VERSION ""

NS_ :

BS_:

BU_: AHLM ASBS CBC DIAGNOST DPDM DTCM ECM EHPS ESC ESL ESM ETM GPF HCP IC IRCM OCM ORC PTS RF_HUB SCCM SGW TBM TCM TPM

BO_ 969 AMB_TEMP_DISP: 4 CBC
 SG_ AMB_TEMP_AVG_C : 8|8@1+ (1,-40) [-40|210] "°C"  IC,SGW
 SG_ AMB_TEMP_AVG_F : 0|8@1+ (1,-40) [-40|210] "°F"  IC,SGW

BO_ 1769 APPL_ECU_AHLM: 8 DIAGNOST
 SG_ APPL_ECU_AHLM : 7|64@0+ (1,0) [0|0] ""  AHLM

BO_ 1738 APPL_ECU_ASBS: 8 DIAGNOST
 SG_ APPL_ECU_ASBS : 7|64@0+ (1,0) [0|0] ""  ASBS

BO_ 1788 APPL_ECU_BSMO: 8 DIAGNOST
 SG_ APPL_ECU_BSMO : 7|64@0+ (1,0) [0|0] ""  ESC

BO_ 1729 APPL_ECU_CBC: 8 DIAGNOST
 SG_ APPL_ECU_CBC : 7|64@0+ (1,0) [0|0] ""  CBC

BO_ 1747 APPL_ECU_DASM: 8 DIAGNOST
 SG_ APPL_ECU_DASM : 7|64@0+ (1,0) [0|0] ""  IRCM

BO_ 1745 APPL_ECU_DPDM: 8 DIAGNOST
 SG_ APPL_ECU_DPDM : 7|64@0+ (1,0) [0|0] ""  DPDM

BO_ 1739 APPL_ECU_DTCM: 8 DIAGNOST
 SG_ APPL_ECU_DTCM : 7|64@0+ (1,0) [0|0] ""  DTCM

BO_ 1784 APPL_ECU_ECM: 8 DIAGNOST
 SG_ APPL_ECU_ECM : 7|64@0+ (1,0) [0|0] ""  ECM

BO_ 1754 APPL_ECU_EPS: 8 DIAGNOST
 SG_ APPL_ECU_EPS : 7|64@0+ (1,0) [0|0] ""  EHPS

BO_ 1735 APPL_ECU_ESC: 8 DIAGNOST
 SG_ APPL_ECU_ESC : 7|64@0+ (1,0) [0|0] ""  ESC

BO_ 1736 APPL_ECU_ESL: 8 DIAGNOST
 SG_ APPL_ECU_ESL : 7|64@0+ (1,0) [0|0] ""  ESL

BO_ 1737 APPL_ECU_ESM: 8 DIAGNOST
 SG_ APPL_ECU_ESM : 7|64@0+ (1,0) [0|0] ""  ESM

BO_ 1778 APPL_ECU_GPF: 8 DIAGNOST
 SG_ APPL_ECU_GPF : 7|64@0+ (1,0) [0|0] ""  GPF

BO_ 1786 APPL_ECU_HCP: 8 DIAGNOST
 SG_ APPL_ECU_HCP : 7|64@0+ (1,0) [0|0] ""  HCP

BO_ 1730 APPL_ECU_IC: 8 DIAGNOST
 SG_ APPL_ECU_IC : 7|64@0+ (1,0) [0|0] ""  IC

BO_ 1758 APPL_ECU_OCM: 8 DIAGNOST
 SG_ APPL_ECU_OCM : 7|64@0+ (1,0) [0|0] ""  OCM

BO_ 1732 APPL_ECU_ORC: 8 DIAGNOST
 SG_ APPL_ECU_ORC : 7|64@0+ (1,0) [0|0] ""  ORC

BO_ 1762 APPL_ECU_PTS: 8 DIAGNOST
 SG_ APPL_ECU_PTS : 7|64@0+ (1,0) [0|0] ""  PTS

BO_ 1728 APPL_ECU_RF_HUB: 8 DIAGNOST
 SG_ APPL_ECU_RF_HUB : 7|64@0+ (1,0) [0|0] ""  RF_HUB

BO_ 1763 APPL_ECU_SCCM: 8 DIAGNOST
 SG_ APPL_ECU_SCCM : 7|64@0+ (1,0) [0|0] ""  SCCM

BO_ 1835 APPL_ECU_TBM: 8 DIAGNOST
 SG_ APPL_ECU_TBM : 7|64@0+ (1,0) [0|0] ""  TBM

BO_ 1785 APPL_ECU_TCM: 8 DIAGNOST
 SG_ APPL_ECU_TCM : 7|64@0+ (1,0) [0|0] ""  TCM

BO_ 1731 APPL_ECU_TPM: 8 DIAGNOST
 SG_ APPL_ECU_TPM : 7|64@0+ (1,0) [0|0] ""  TPM

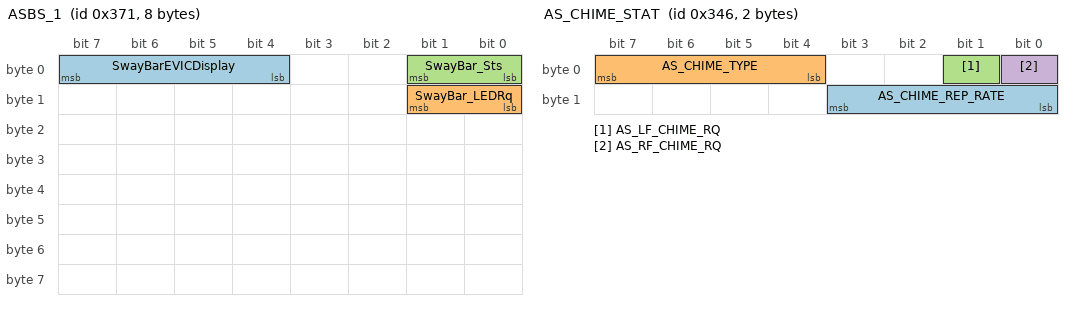
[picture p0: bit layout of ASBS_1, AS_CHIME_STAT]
BO_ 881 ASBS_1: 8 ASBS
 SG_ SwayBarEVICDisplay : 4|4@1+ (1,0) [0|0] ""  ETM,IC,SGW
 SG_ SwayBar_LEDRq : 8|2@1+ (1,0) [0|0] ""  CBC,SGW
 SG_ SwayBar_Sts : 0|2@1+ (1,0) [0|0] ""  ETM,IC,SGW

BO_ 838 AS_CHIME_STAT: 2 IRCM
 SG_ AS_CHIME_REP_RATE : 8|4@1+ (1,0) [0|15] "Hz"  CBC,SGW
 SG_ AS_CHIME_TYPE : 4|4@1+ (1,0) [0|0] ""  CBC,ORC,SGW
 SG_ AS_LF_CHIME_RQ : 1|1@1+ (1,0) [0|0] ""  CBC,SGW
 SG_ AS_RF_CHIME_RQ : 0|1@1+ (1,0) [0|0] ""  CBC,SGW

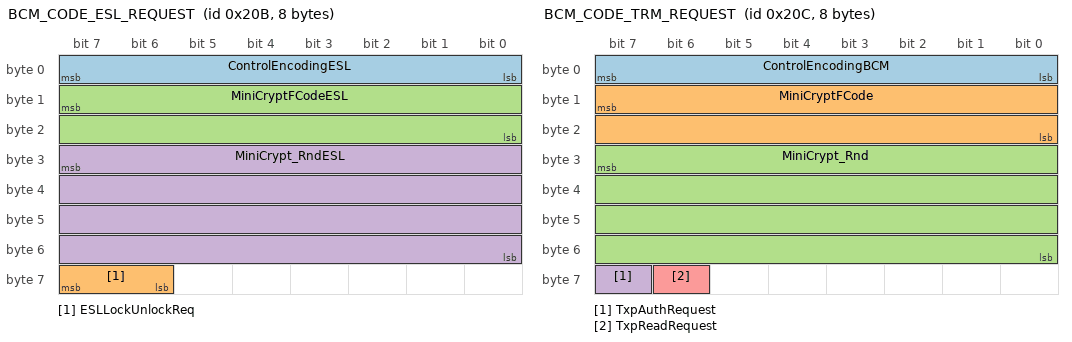
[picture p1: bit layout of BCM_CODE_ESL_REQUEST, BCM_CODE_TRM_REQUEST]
BO_ 523 BCM_CODE_ESL_REQUEST: 8 CBC
 SG_ ControlEncodingESL : 0|8@1+ (1,0) [0|0] ""  ESL,SGW
 SG_ ESLLockUnlockReq : 62|2@1+ (1,0) [0|0] ""  ESL,SGW
 SG_ MiniCryptFCodeESL : 15|16@0+ (1,0) [0|0] ""  ESL,SGW
 SG_ MiniCrypt_RndESL : 31|32@0+ (1,0) [0|0] ""  ESL,SGW

BO_ 524 BCM_CODE_TRM_REQUEST: 8 CBC
 SG_ ControlEncodingBCM : 0|8@1+ (1,0) [0|0] ""  RF_HUB,SGW
 SG_ MiniCryptFCode : 15|16@0+ (1,0) [0|0] ""  RF_HUB,SGW
 SG_ MiniCrypt_Rnd : 31|32@0+ (1,0) [0|0] ""  RF_HUB,SGW
 SG_ TxpAuthRequest : 63|1@1+ (1,0) [0|0] ""  RF_HUB,SGW
 SG_ TxpReadRequest : 62|1@1+ (1,0) [0|0] ""  RF_HUB,SGW

BO_ 525 BCM_MINICRYPT_ACK: 1 CBC
 SG_ MinicryptReceptionSts : 7|1@1+ (1,0) [0|0] ""  RF_HUB,SGW

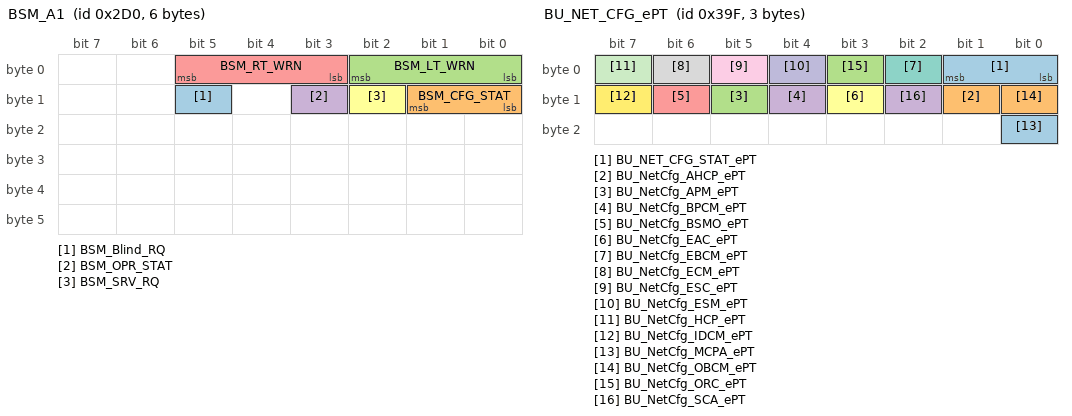
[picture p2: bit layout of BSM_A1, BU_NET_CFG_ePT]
BO_ 720 BSM_A1: 6 CBC
 SG_ BSM_Blind_RQ : 13|1@1+ (1,0) [0|0] ""  IC,IRCM,ORC,SGW
 SG_ BSM_CFG_STAT : 8|2@1+ (1,0) [0|0] ""  IC,IRCM,ORC,SGW
 SG_ BSM_LT_WRN : 0|3@1+ (1,0) [0|0] ""  IRCM,ORC,SGW
 SG_ BSM_OPR_STAT : 11|1@1+ (1,0) [0|0] ""  IC,IRCM,SGW
 SG_ BSM_RT_WRN : 3|3@1+ (1,0) [0|0] ""  IRCM,ORC,SGW
 SG_ BSM_SRV_RQ : 10|1@1+ (1,0) [0|0] ""  IC,IRCM,ORC,SGW

BO_ 998 BU_NET_CFG_INT: 8 RF_HUB
 SG_ BU_NET_CFG_STAT_INT : 0|2@1+ (1,0) [0|0] ""  CBC,SGW
 SG_ BU_NetCfg_AMP_I : 24|1@1+ (1,0) [0|0] ""  CBC,SGW
 SG_ BU_NetCfg_ANC_I : 39|1@1+ (1,0) [0|0] ""  CBC,SGW
 SG_ BU_NetCfg_BSM : 3|1@1+ (1,0) [0|0] ""  CBC,SGW
 SG_ BU_NetCfg_CBC_IN : 4|1@1+ (1,0) [0|0] ""  CBC,SGW
 SG_ BU_NetCfg_CLOCK : 21|1@1+ (1,0) [0|0] ""  CBC,SGW
 SG_ BU_NetCfg_CRSM : 30|1@1+ (1,0) [0|0] ""  CBC,SGW
 SG_ BU_NetCfg_CSWM : 5|1@1+ (1,0) [0|0] ""  CBC,SGW
 SG_ BU_NetCfg_CVPM : 32|1@1+ (1,0) [0|0] ""  CBC,SGW
 SG_ BU_NetCfg_DCM_DR : 6|1@1+ (1,0) [0|0] ""  CBC,SGW
 SG_ BU_NetCfg_DCM_PASS : 7|1@1+ (1,0) [0|0] ""  CBC,SGW
 SG_ BU_NetCfg_DCM_RL : 8|1@1+ (1,0) [0|0] ""  CBC,SGW
 SG_ BU_NetCfg_DCM_RR : 9|1@1+ (1,0) [0|0] ""  CBC,SGW
 SG_ BU_NetCfg_DCSD : 37|1@1+ (1,0) [0|0] ""  CBC,SGW
 SG_ BU_NetCfg_DTV : 19|1@1+ (1,0) [0|0] ""  CBC,SGW
 SG_ BU_NetCfg_DVD_CDM : 25|1@1+ (1,0) [0|0] ""  CBC,SGW
 SG_ BU_NetCfg_FSM : 16|1@1+ (1,0) [0|0] ""  CBC,SGW
 SG_ BU_NetCfg_HFM_CTM : 26|1@1+ (1,0) [0|0] ""  CBC,SGW
 SG_ BU_NetCfg_HVAC : 10|1@1+ (1,0) [0|0] ""  CBC,SGW
 SG_ BU_NetCfg_HVAC_R : 31|1@1+ (1,0) [0|0] ""  CBC,SGW
 SG_ BU_NetCfg_ICS_I : 27|1@1+ (1,0) [0|0] ""  CBC,SGW
 SG_ BU_NetCfg_ICS_R : 34|1@1+ (1,0) [0|0] ""  CBC,SGW
 SG_ BU_NetCfg_ITM : 23|1@1+ (1,0) [0|0] ""  CBC,SGW
 SG_ BU_NetCfg_MSM : 11|1@1+ (1,0) [0|0] ""  CBC,SGW
 SG_ BU_NetCfg_MSM_PASS : 35|1@1+ (1,0) [0|0] ""  CBC,SGW
 SG_ BU_NetCfg_PLG : 12|1@1+ (1,0) [0|0] ""  CBC,SGW
 SG_ BU_NetCfg_PSD_LT : 14|1@1+ (1,0) [0|0] ""  CBC,SGW
 SG_ BU_NetCfg_PSD_RT : 15|1@1+ (1,0) [0|0] ""  CBC,SGW
 SG_ BU_NetCfg_PSSM : 45|1@1+ (1,0) [0|0] ""  CBC,SGW
 SG_ BU_NetCfg_PTCM : 17|1@1+ (1,0) [0|0] ""  CBC,SGW
 SG_ BU_NetCfg_RBC : 18|1@1+ (1,0) [0|0] ""  CBC,SGW
 SG_ BU_NetCfg_RBSS : 2|1@1+ (1,0) [0|0] ""  CBC,SGW
 SG_ BU_NetCfg_TBM : 38|1@1+ (1,0) [0|0] ""  CBC,SGW
 SG_ BU_NetCfg_TGW : 20|1@1+ (1,0) [0|0] ""  CBC,SGW
 SG_ BU_NetCfg_TMM : 33|1@1+ (1,0) [0|0] ""  CBC,SGW
 SG_ BU_NetCfg_TTM : 47|1@1+ (1,0) [0|0] ""  CBC,SGW
 SG_ BU_NetCfg_UPFM : 46|1@1+ (1,0) [0|0] ""  CBC,SGW
 SG_ BU_NetCfg_VES2_I : 28|1@1+ (1,0) [0|0] ""  CBC,SGW
 SG_ BU_NetCfg_VES3_I : 29|1@1+ (1,0) [0|0] ""  CBC,SGW
 SG_ BU_NetCfg_VRM : 36|1@1+ (1,0) [0|0] ""  CBC,SGW
 SG_ BU_NetCfg_VSIM : 22|1@1+ (1,0) [0|0] ""  CBC,SGW
 SG_ BU_NetCfg_VTM : 13|1@1+ (1,0) [0|0] ""  CBC,SGW

BO_ 999 BU_NET_CFG_PT: 8 RF_HUB
 SG_ BU_NET_CFG_STAT_PT : 0|2@1+ (1,0) [0|0] ""  CBC,SGW
 SG_ BU_NetCfg_ACC : 2|1@1+ (1,0) [0|0] ""  CBC,SGW
 SG_ BU_NetCfg_ADCM : 3|1@1+ (1,0) [0|0] ""  CBC,SGW
 SG_ BU_NetCfg_AFLS : 28|1@1+ (1,0) [0|0] ""  CBC,SGW
 SG_ BU_NetCfg_AHLM : 4|1@1+ (1,0) [0|0] ""  CBC,SGW
 SG_ BU_NetCfg_ANC : 39|1@1+ (1,0) [0|0] ""  CBC,SGW
 SG_ BU_NetCfg_ASBS : 35|1@1+ (1,0) [0|0] ""  CBC,SGW
 SG_ BU_NetCfg_ASCM : 6|1@1+ (1,0) [0|0] ""  CBC,SGW
 SG_ BU_NetCfg_BSMO : 36|1@1+ (1,0) [0|0] ""  CBC,SGW
 SG_ BU_NetCfg_CBC_PT : 7|1@1+ (1,0) [0|0] ""  CBC,SGW
 SG_ BU_NetCfg_DASM : 16|1@1+ (1,0) [0|0] ""  CBC,SGW
 SG_ BU_NetCfg_DPDM : 33|1@1+ (1,0) [0|0] ""  CBC,SGW
 SG_ BU_NetCfg_DTCM : 8|1@1+ (1,0) [0|0] ""  CBC,SGW
 SG_ BU_NetCfg_ECM : 9|1@1+ (1,0) [0|0] ""  CBC,SGW
 SG_ BU_NetCfg_ELSD : 24|1@1+ (1,0) [0|0] ""  CBC,SGW
 SG_ BU_NetCfg_EPB : 13|1@1+ (1,0) [0|0] ""  CBC,SGW
 SG_ BU_NetCfg_EPPM : 18|1@1+ (1,0) [0|0] ""  CBC,SGW
 SG_ BU_NetCfg_EPS : 10|1@1+ (1,0) [0|0] ""  CBC,SGW
 SG_ BU_NetCfg_ESC : 12|1@1+ (1,0) [0|0] ""  CBC,SGW
 SG_ BU_NetCfg_ESL : 37|1@1+ (1,0) [0|0] ""  CBC,SGW
 SG_ BU_NetCfg_ESM : 11|1@1+ (1,0) [0|0] ""  CBC,SGW
 SG_ BU_NetCfg_FDCM : 17|1@1+ (1,0) [0|0] ""  CBC,SGW
 SG_ BU_NetCfg_GPF : 58|1@1+ (1,0) [0|0] ""  CBC,SGW
 SG_ BU_NetCfg_HCP : 38|1@1+ (1,0) [0|0] ""  CBC,SGW
 SG_ BU_NetCfg_HaLF : 31|1@1+ (1,0) [0|0] ""  CBC,SGW
 SG_ BU_NetCfg_IC : 15|1@1+ (1,0) [0|0] ""  CBC,SGW
 SG_ BU_NetCfg_ITBM : 29|1@1+ (1,0) [0|0] ""  CBC,SGW
 SG_ BU_NetCfg_OCM : 30|1@1+ (1,0) [0|0] ""  CBC,SGW
 SG_ BU_NetCfg_ORC : 19|1@1+ (1,0) [0|0] ""  CBC,SGW
 SG_ BU_NetCfg_PASS_PT : 27|1@1+ (1,0) [0|0] ""  CBC,SGW
 SG_ BU_NetCfg_PTS : 20|1@1+ (1,0) [0|0] ""  CBC,SGW
 SG_ BU_NetCfg_RF_HUB : 14|1@1+ (1,0) [0|0] ""  CBC,SGW
 SG_ BU_NetCfg_SCCM : 23|1@1+ (1,0) [0|0] ""  CBC,SGW
 SG_ BU_NetCfg_SGW : 34|1@1+ (1,0) [0|0] ""  CBC,SGW
 SG_ BU_NetCfg_TCM : 25|1@1+ (1,0) [0|0] ""  CBC,SGW
 SG_ BU_NetCfg_TIM : 60|1@1+ (1,0) [0|0] ""  CBC,SGW
 SG_ BU_NetCfg_TPM : 26|1@1+ (1,0) [0|0] ""  CBC,SGW
 SG_ BU_NetCfg_TTPM : 59|1@1+ (1,0) [0|0] ""  CBC,SGW
 SG_ BU_NetCfg_VSIM_C : 5|1@1+ (1,0) [0|0] ""  CBC,SGW

BO_ 927 BU_NET_CFG_ePT: 3 RF_HUB
 SG_ BU_NET_CFG_STAT_ePT : 0|2@1+ (1,0) [0|0] ""  CBC,SGW
 SG_ BU_NetCfg_AHCP_ePT : 9|1@1+ (1,0) [0|0] ""  CBC,SGW
 SG_ BU_NetCfg_APM_ePT : 13|1@1+ (1,0) [0|0] ""  CBC,SGW
 SG_ BU_NetCfg_BPCM_ePT : 12|1@1+ (1,0) [0|0] ""  CBC,SGW
 SG_ BU_NetCfg_BSMO_ePT : 14|1@1+ (1,0) [0|0] ""  CBC,SGW
 SG_ BU_NetCfg_EAC_ePT : 11|1@1+ (1,0) [0|0] ""  CBC,SGW
 SG_ BU_NetCfg_EBCM_ePT : 2|1@1+ (1,0) [0|0] ""  CBC,SGW
 SG_ BU_NetCfg_ECM_ePT : 6|1@1+ (1,0) [0|0] ""  CBC,SGW
 SG_ BU_NetCfg_ESC_ePT : 5|1@1+ (1,0) [0|0] ""  CBC,SGW
 SG_ BU_NetCfg_ESM_ePT : 4|1@1+ (1,0) [0|0] ""  CBC,SGW
 SG_ BU_NetCfg_HCP_ePT : 7|1@1+ (1,0) [0|0] ""  CBC,SGW
 SG_ BU_NetCfg_IDCM_ePT : 15|1@1+ (1,0) [0|0] ""  CBC,SGW
 SG_ BU_NetCfg_MCPA_ePT : 16|1@1+ (1,0) [0|0] ""  CBC,SGW
 SG_ BU_NetCfg_OBCM_ePT : 8|1@1+ (1,0) [0|0] ""  CBC,SGW
 SG_ BU_NetCfg_ORC_ePT : 3|1@1+ (1,0) [0|0] ""  CBC,SGW
 SG_ BU_NetCfg_SCA_ePT : 10|1@1+ (1,0) [0|0] ""  CBC,SGW

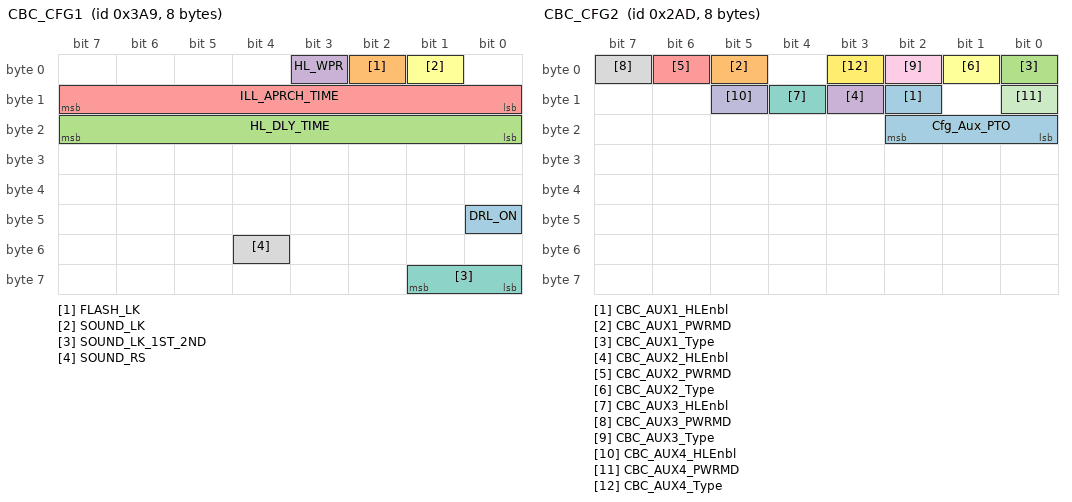
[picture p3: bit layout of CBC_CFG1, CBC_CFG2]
BO_ 937 CBC_CFG1: 8 CBC
 SG_ DRL_ON : 40|1@1+ (1,0) [0|0] ""  SGW
 SG_ FLASH_LK : 2|1@1+ (1,0) [0|0] ""  SGW
 SG_ HL_DLY_TIME : 16|8@1+ (1,0) [0|254] "sec"  SGW
 SG_ HL_WPR : 3|1@1+ (1,0) [0|0] ""  SGW
 SG_ ILL_APRCH_TIME : 8|8@1+ (1,0) [0|254] "sec"  SGW
 SG_ SOUND_LK : 1|1@1+ (1,0) [0|0] ""  SGW
 SG_ SOUND_LK_1ST_2ND : 56|2@1+ (1,0) [0|0] ""  SGW
 SG_ SOUND_RS : 52|1@1+ (1,0) [0|0] ""  SGW

BO_ 685 CBC_CFG2: 8 CBC
 SG_ CBC_AUX1_HLEnbl : 10|1@1+ (1,0) [0|0] ""  SGW
 SG_ CBC_AUX1_PWRMD : 5|1@1+ (1,0) [0|0] ""  SGW
 SG_ CBC_AUX1_Type : 0|1@1+ (1,0) [0|0] ""  SGW
 SG_ CBC_AUX2_HLEnbl : 11|1@1+ (1,0) [0|0] ""  SGW
 SG_ CBC_AUX2_PWRMD : 6|1@1+ (1,0) [0|0] ""  SGW
 SG_ CBC_AUX2_Type : 1|1@1+ (1,0) [0|0] ""  SGW
 SG_ CBC_AUX3_HLEnbl : 12|1@1+ (1,0) [0|0] ""  SGW
 SG_ CBC_AUX3_PWRMD : 7|1@1+ (1,0) [0|0] ""  SGW
 SG_ CBC_AUX3_Type : 2|1@1+ (1,0) [0|0] ""  SGW
 SG_ CBC_AUX4_HLEnbl : 13|1@1+ (1,0) [0|0] ""  SGW
 SG_ CBC_AUX4_PWRMD : 8|1@1+ (1,0) [0|0] ""  SGW
 SG_ CBC_AUX4_Type : 3|1@1+ (1,0) [0|0] ""  SGW
 SG_ Cfg_Aux_PTO : 16|3@1+ (1,0) [0|0] ""  SGW

BO_ 657 CBC_PT1: 8 CBC
 SG_ AHB_ACT : 14|1@1+ (1,0) [0|0] ""  IC,SGW
 SG_ BRK_FLUID_LO : 62|1@1+ (1,0) [0|0] ""  ESC,ETM,IC,SGW,TBM
 SG_ DAY_LGT_MD : 40|1@1+ (1,0) [0|0] ""  ESM,HCP,IC,ORC,RF_HUB,SGW
 SG_ DRV_AJAR : 17|1@1+ (1,0) [0|0] ""  ESC,ETM,HCP,IC,IRCM,RF_HUB,SGW,TBM,TCM
 SG_ DR_LK_STAT : 5|2@1+ (1,0) [0|0] ""  SGW
 SG_ FOB_SrchRq : 8|2@1+ (1,0) [0|0] ""  RF_HUB,SGW
 SG_ FT_FOG_RQ : 2|1@1+ (1,0) [0|0] ""  ECM,ETM,IC,SGW,TBM
 SG_ FT_WPR_NOT_PRK : 56|1@1+ (1,0) [0|0] ""  DTCM,ECM,IRCM,SGW
 SG_ HIBEAM_ON : 58|1@1+ (1,0) [0|0] ""  ECM,ETM,IC,IRCM,SGW,TBM
 SG_ IGN_OFF_TIME_LNG : 27|12@0+ (1,0) [0|4080] "min"  DTCM,ECM,ESC,IRCM,SGW,TCM
 SG_ LOBEAM_ON : 57|1@1+ (1,0) [0|0] ""  AHLM,ECM,ETM,SGW,TBM
 SG_ L_R_AJAR : 19|1@1+ (1,0) [0|0] ""  ETM,IC,RF_HUB,SGW,TBM
 SG_ PANEL_INTS : 48|8@1+ (0.5,0) [0|100] "%"  ESM,HCP,IC,RF_HUB,SGW
 SG_ PARK_BRK_EGD : 23|1@1+ (1,0) [0|0] ""  ECM,ESC,IC,IRCM,ORC,SGW,TCM,TPM
 SG_ PARK_LMP_ON : 16|1@1+ (1,0) [0|0] ""  ETM,IC,SGW,TBM
 SG_ PSG_AJAR : 18|1@1+ (1,0) [0|0] ""  ESC,ETM,IC,RF_HUB,SGW,TBM
 SG_ PTC_REL1_STAT : 42|2@1+ (1,0) [0|0] ""  ECM,SGW
 SG_ PTC_REL2_STAT : 44|2@1+ (1,0) [0|0] ""  ECM,SGW
 SG_ PTC_REL3_STAT : 46|2@1+ (1,0) [0|0] ""  ECM,SGW
 SG_ REV_GEAR : 4|1@1+ (1,0) [0|0] ""  DTCM,ESC,IC,ORC,PTS,SGW,TPM
 SG_ R_FOG_RQ : 3|1@1+ (1,0) [0|0] ""  ECM,ETM,IC,SGW,TBM
 SG_ R_R_AJAR : 20|1@1+ (1,0) [0|0] ""  ETM,IC,RF_HUB,SGW,TBM
 SG_ SHIP_STAT : 28|2@1+ (1,0) [0|0] ""  DTCM,HCP,IC,IRCM,RF_HUB,SGW
 SG_ TLG_AJAR : 22|1@1+ (1,0) [0|0] ""  ETM,IC,RF_HUB,SGW,TBM
 SG_ TurnInd_LT_ON : 30|1@1+ (1,0) [0|0] ""  ETM,IC,SGW,TBM
 SG_ TurnInd_RT_ON : 31|1@1+ (1,0) [0|0] ""  ETM,IC,SGW,TBM
 SG_ WASH_FLUID_LO : 63|1@1+ (1,0) [0|0] ""  ETM,IC,SGW,TBM

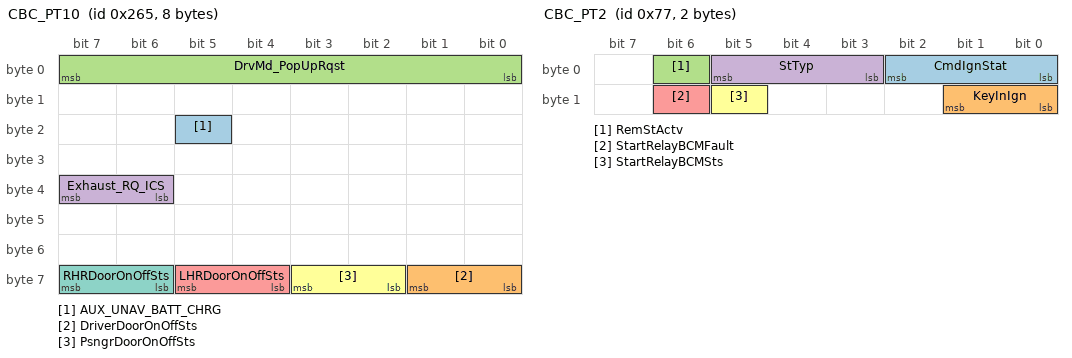
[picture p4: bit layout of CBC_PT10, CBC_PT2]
BO_ 613 CBC_PT10: 8 CBC
 SG_ AUX_UNAV_BATT_CHRG : 21|1@1+ (1,0) [0|0] ""  IC,SGW
 SG_ DriverDoorOnOffSts : 56|2@1+ (1,0) [0|0] ""  ESC,IC,IRCM,RF_HUB,SGW
 SG_ DrvMd_PopUpRqst : 0|8@1+ (1,0) [0|0] ""  IC,SGW
 SG_ Exhaust_RQ_ICS : 38|2@1+ (1,0) [0|0] ""  ECM,SGW
 SG_ LHRDoorOnOffSts : 60|2@1+ (1,0) [0|0] ""  RF_HUB,SGW
 SG_ PsngrDoorOnOffSts : 58|2@1+ (1,0) [0|0] ""  RF_HUB,SGW
 SG_ RHRDoorOnOffSts : 62|2@1+ (1,0) [0|0] ""  RF_HUB,SGW

BO_ 119 CBC_PT2: 2 CBC
 SG_ CmdIgnStat : 0|3@1+ (1,0) [0|0] ""  AHLM,ASBS,DPDM,DTCM,ECM,EHPS,ESC,ESL,ESM,GPF,HCP,IC,IRCM,OCM,ORC,PTS,RF_HUB,SCCM,SGW,TCM,TPM
 SG_ KeyInIgn : 8|2@1+ (1,0) [0|0] ""  ESC,ESL,HCP,IC,RF_HUB,SGW
 SG_ RemStActv : 6|1@1+ (1,0) [0|0] ""  DTCM,ECM,ESM,HCP,IC,ORC,RF_HUB,SGW,TCM,TPM
 SG_ StTyp : 3|3@1+ (1,0) [0|0] ""  DTCM,RF_HUB,SGW
 SG_ StartRelayBCMFault : 14|1@1+ (1,0) [0|0] ""  ECM,SGW
 SG_ StartRelayBCMSts : 13|1@1+ (1,0) [0|0] ""  ECM,SGW

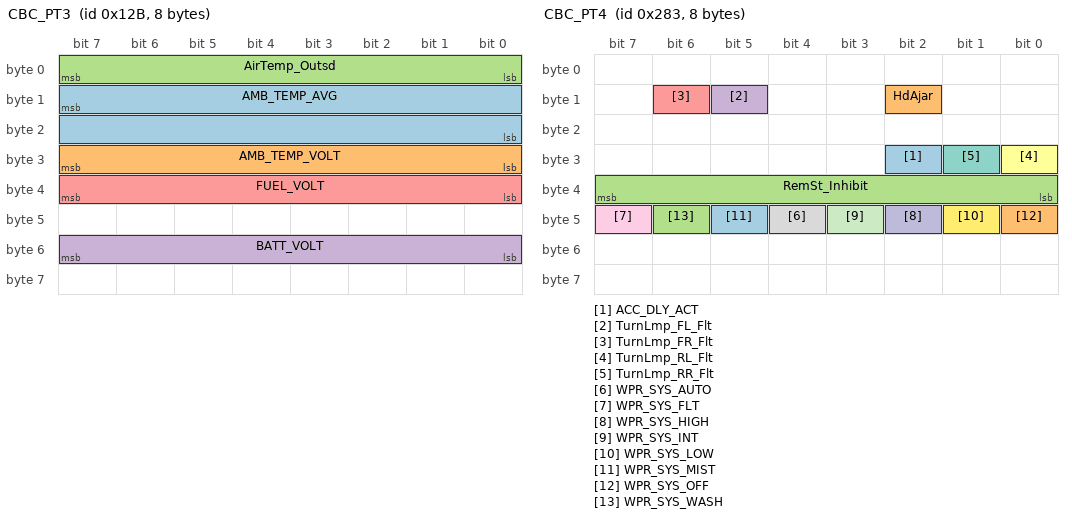
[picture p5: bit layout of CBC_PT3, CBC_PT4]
BO_ 299 CBC_PT3: 8 CBC
 SG_ AMB_TEMP_AVG : 15|16@0+ (0.01,-40) [-40|85] "°C"  DPDM,DTCM,ECM,ESC,HCP,OCM,PTS,SGW,TCM,TPM
 SG_ AMB_TEMP_VOLT : 24|8@1+ (0.019607843,0) [0|4.98] "Volts"  ECM,HCP,SGW
 SG_ AirTemp_Outsd : 0|8@1+ (0.5,-40) [-40|85] "°C"  DTCM,ECM,IRCM,ORC,SGW
 SG_ BATT_VOLT : 48|8@1+ (0.1,0) [5|18] "Volts"  AHLM,ASBS,DPDM,DTCM,ECM,EHPS,ESC,ESL,ESM,GPF,HCP,IC,IRCM,OCM,ORC,PTS,RF_HUB,SCCM,SGW,TCM,TPM
 SG_ FUEL_VOLT : 32|8@1+ (0.019607843,0) [0|4.98] "Volts"  ECM,IC,SGW

BO_ 643 CBC_PT4: 8 CBC
 SG_ ACC_DLY_ACT : 26|1@1+ (1,0) [0|0] ""  IC,SGW
 SG_ HdAjar : 10|1@1+ (1,0) [0|0] ""  ETM,HCP,IC,SGW,TBM
 SG_ RemSt_Inhibit : 32|8@1+ (1,0) [0|0] ""  ETM,IC,SGW,TBM
 SG_ TurnLmp_FL_Flt : 13|1@1+ (1,0) [0|0] ""  ETM,IC,SGW,TBM
 SG_ TurnLmp_FR_Flt : 14|1@1+ (1,0) [0|0] ""  ETM,IC,SGW,TBM
 SG_ TurnLmp_RL_Flt : 24|1@1+ (1,0) [0|0] ""  ETM,IC,SGW,TBM
 SG_ TurnLmp_RR_Flt : 25|1@1+ (1,0) [0|0] ""  ETM,IC,SGW,TBM
 SG_ WPR_SYS_AUTO : 44|1@1+ (1,0) [0|0] ""  ESC,IRCM,SGW
 SG_ WPR_SYS_FLT : 47|1@1+ (1,0) [0|0] ""  ESC,IRCM,SGW
 SG_ WPR_SYS_HIGH : 42|1@1+ (1,0) [0|0] ""  ESC,IRCM,SGW
 SG_ WPR_SYS_INT : 43|1@1+ (1,0) [0|0] ""  ESC,IRCM,SGW
 SG_ WPR_SYS_LOW : 41|1@1+ (1,0) [0|0] ""  ESC,IRCM,SGW
 SG_ WPR_SYS_MIST : 45|1@1+ (1,0) [0|0] ""  DTCM,ESC,IRCM,SGW
 SG_ WPR_SYS_OFF : 40|1@1+ (1,0) [0|0] ""  ESC,IRCM,SGW
 SG_ WPR_SYS_WASH : 46|1@1+ (1,0) [0|0] ""  ESC,IRCM,SGW

BO_TX_BU_ 1769 : DIAGNOST,SGW;
BO_TX_BU_ 1738 : DIAGNOST,SGW;
BO_TX_BU_ 1788 : DIAGNOST,SGW;
BO_TX_BU_ 1729 : DIAGNOST,SGW;
BO_TX_BU_ 1747 : DIAGNOST,SGW;
BO_TX_BU_ 1745 : DIAGNOST,SGW;
BO_TX_BU_ 1739 : DIAGNOST,SGW;
BO_TX_BU_ 1784 : DIAGNOST,SGW;
BO_TX_BU_ 1754 : DIAGNOST,SGW;
BO_TX_BU_ 1735 : DIAGNOST,SGW;
BO_TX_BU_ 1736 : DIAGNOST,SGW;
BO_TX_BU_ 1737 : DIAGNOST,SGW;
BO_TX_BU_ 1778 : DIAGNOST,SGW;
BO_TX_BU_ 1786 : DIAGNOST,SGW;
BO_TX_BU_ 1730 : DIAGNOST,SGW;
BO_TX_BU_ 1758 : DIAGNOST,SGW;
BO_TX_BU_ 1732 : DIAGNOST,SGW;
BO_TX_BU_ 1762 : DIAGNOST,SGW;
BO_TX_BU_ 1728 : DIAGNOST,SGW;
BO_TX_BU_ 1763 : DIAGNOST,SGW;
BO_TX_BU_ 1835 : DIAGNOST,SGW;
BO_TX_BU_ 1785 : DIAGNOST,SGW;
BO_TX_BU_ 1731 : DIAGNOST,SGW;

CM_ "Excel Convert to DBC - Written by Vector CANtech, Inc. 2016";
CM_ SG_ 969 AMB_TEMP_AVG_C "Ambient temperature average - in degrees Celsius";
CM_ SG_ 969 AMB_TEMP_AVG_F "Ambient temperature average - in degrees Fahrenheit";
CM_ SG_ 1769 APPL_ECU_AHLM "External Application to ECU";
CM_ SG_ 1738 APPL_ECU_ASBS "External Application to ECU";
CM_ SG_ 1788 APPL_ECU_BSMO "External Application to ECU";
CM_ SG_ 1729 APPL_ECU_CBC "External Application to ECU";
CM_ SG_ 1747 APPL_ECU_DASM "External Application to ECU";
CM_ SG_ 1745 APPL_ECU_DPDM "External Application to ECU";
CM_ SG_ 1739 APPL_ECU_DTCM "External Application to ECU";
CM_ SG_ 1784 APPL_ECU_ECM "External Application to ECU";
CM_ SG_ 1754 APPL_ECU_EPS "External Application to ECU";
CM_ SG_ 1735 APPL_ECU_ESC "External Application to ECU";
CM_ SG_ 1736 APPL_ECU_ESL "External Application to ECU";
CM_ SG_ 1737 APPL_ECU_ESM "External Application to ECU";
CM_ SG_ 1778 APPL_ECU_GPF "External Application to ECU";
CM_ SG_ 1786 APPL_ECU_HCP "External Application to ECU";
CM_ SG_ 1730 APPL_ECU_IC "External Application to ECU";
CM_ SG_ 1758 APPL_ECU_OCM "External Application to ECU";
CM_ SG_ 1732 APPL_ECU_ORC "External Application to ECU";
CM_ SG_ 1762 APPL_ECU_PTS "External Application to ECU";
CM_ SG_ 1728 APPL_ECU_RF_HUB "External Application to ECU";
CM_ SG_ 1763 APPL_ECU_SCCM "External Application to ECU";
CM_ SG_ 1835 APPL_ECU_TBM "External Application to ECU";
CM_ SG_ 1785 APPL_ECU_TCM "External Application to ECU";
CM_ SG_ 1731 APPL_ECU_TPM "External Application to ECU";
CM_ SG_ 881 SwayBarEVICDisplay "Sway Bar HMI display request";
CM_ SG_ 881 SwayBar_LEDRq "Sway Bar disconnect switch LED request";
CM_ SG_ 881 SwayBar_Sts "Swaybar status";
CM_ SG_ 838 AS_CHIME_REP_RATE "AS chime repetition rate";
CM_ SG_ 838 AS_CHIME_TYPE "AS chime type";
CM_ SG_ 838 AS_LF_CHIME_RQ "AS left front chime on request; True = [1]";
CM_ SG_ 838 AS_RF_CHIME_RQ "AS right front chime on request; True = [1]";
CM_ SG_ 523 ControlEncodingESL "ESL immobilizer action requested";
CM_ SG_ 523 ESLLockUnlockReq "Lock or unlock column";
CM_ SG_ 523 MiniCryptFCodeESL "BCM MiniCrypt code";
CM_ SG_ 523 MiniCrypt_RndESL "MiniCrypt random number";
CM_ SG_ 524 ControlEncodingBCM "Fob authentication or presence query";
CM_ SG_ 524 MiniCryptFCode "MiniCrypt 'F' code output";
CM_ SG_ 524 MiniCrypt_Rnd "MiniCrypt input random number";
CM_ SG_ 524 TxpAuthRequest "Transponder authentication request; Request = [0]";
CM_ SG_ 524 TxpReadRequest "Transponder reading request; Request = [0]";
CM_ SG_ 525 MinicryptReceptionSts "Acknowledge message reception; Received = [1]";
CM_ SG_ 720 BSM_Blind_RQ "Sensor blinded request from BSM; 1= sensor blocked request";
CM_ SG_ 720 BSM_CFG_STAT "BSM configuration status";
CM_ SG_ 720 BSM_LT_WRN "Blind spot detection left side warning";
CM_ SG_ 720 BSM_OPR_STAT "BSM operation status; 1= operational failure";
CM_ SG_ 720 BSM_RT_WRN "Blind spot detection Right side warning";
CM_ SG_ 720 BSM_SRV_RQ "BSM service warning request; 1= service request";
CM_ SG_ 998 BU_NET_CFG_STAT_INT "Backup for network configuration status";
CM_ SG_ 998 BU_NetCfg_AMP_I "Backup for CAN I Amplifier Module (1=present)";
CM_ SG_ 998 BU_NetCfg_ANC_I "Backup for Active Noise Cancellation interior (1=present)";
CM_ SG_ 998 BU_NetCfg_BSM "Backup for Blind-Spot Module (1=present)";
CM_ SG_ 998 BU_NetCfg_CBC_IN "Backup for Common Body Controller Int Bus (1=present)";
CM_ SG_ 998 BU_NetCfg_CLOCK "Backup for CAN I Clock Module (1=present)";
CM_ SG_ 998 BU_NetCfg_CRSM "Backup for CAN I Comfort Rear Seat Module (1=present)";
CM_ SG_ 998 BU_NetCfg_CSWM "Backup for Comfot Seats and Wheel Module (1=present)";
CM_ SG_ 998 BU_NetCfg_CVPM "Backup for CAN I Central Vision Processing Module (1=present)";
CM_ SG_ 998 BU_NetCfg_DCM_DR "Backup for Door Control Module Driver (1=present)";
CM_ SG_ 998 BU_NetCfg_DCM_PASS "Backup for Door Control Module Passenger (1=present)";
CM_ SG_ 998 BU_NetCfg_DCM_RL "Backup for Door Control Module Rear Left (1=present)";
CM_ SG_ 998 BU_NetCfg_DCM_RR "Backup for Door Control Module Rear Right (1=present)";
CM_ SG_ 998 BU_NetCfg_DCSD "Backup for Disassociated Center Stack Display Module (1=present)";
CM_ SG_ 998 BU_NetCfg_DTV "Backup for Digital TV Module (1=present)";
CM_ SG_ 998 BU_NetCfg_DVD_CDM "Backup for CAN I in-dash disc player module (1=present)";
CM_ SG_ 998 BU_NetCfg_FSM "Backup for Folding Seat Module (1=present)";
CM_ SG_ 998 BU_NetCfg_HFM_CTM "Backup for Convergence Telematics Module (1=present)";
CM_ SG_ 998 BU_NetCfg_HVAC "Backup for Heating Ventilation Air Conditioning (1=present)";
CM_ SG_ 998 BU_NetCfg_HVAC_R "Backup for CAN I Rear Heating Ventilation Air Conditioning (1=present)";
CM_ SG_ 998 BU_NetCfg_ICS_I "Backup for CAN I Integrated Center Stack Module (1=present)";
CM_ SG_ 998 BU_NetCfg_ICS_R "Backup for CAN I Integrated rear Center Stack Module (1=present)";
CM_ SG_ 998 BU_NetCfg_ITM "Backup for Intrusion module (1=present)";
CM_ SG_ 998 BU_NetCfg_MSM "Backup for Memory Seat Module (1=present)";
CM_ SG_ 998 BU_NetCfg_MSM_PASS "Backup for CAN I Memory Seat Module Passenger (1=present)";
CM_ SG_ 998 BU_NetCfg_PLG "Backup for Power Liftgate Module (1=present)";
CM_ SG_ 998 BU_NetCfg_PSD_LT "Backup for Power Sliding Door Left Module (1=present)";
CM_ SG_ 998 BU_NetCfg_PSD_RT "Backup for Power Sliding Door Right Module (1=present)";
CM_ SG_ 998 BU_NetCfg_PSSM "NetCfg PSSM";
CM_ SG_ 998 BU_NetCfg_PTCM "Backup for Power Top Control Module (1=present)";
CM_ SG_ 998 BU_NetCfg_RBC "Backup for Rear Body Controller Module (1=present)";
CM_ SG_ 998 BU_NetCfg_RBSS "Backup for Right Blind-Spot Module (1=present)";
CM_ SG_ 998 BU_NetCfg_TBM "Backup for Telematics Box Module (1=present)";
CM_ SG_ 998 BU_NetCfg_TGW "Backup for Telematics gateway (1=present)";
CM_ SG_ 998 BU_NetCfg_TMM "Backup for CAN I Track Mapping Module (1=present)";
CM_ SG_ 998 BU_NetCfg_TTM "0= Not Present;  1= Present";
CM_ SG_ 998 BU_NetCfg_UPFM "Backup for Upfitter Module (1=present)";
CM_ SG_ 998 BU_NetCfg_VES2_I "Backup for CAN I Video Ent. System screen 2 Module (1=present)";
CM_ SG_ 998 BU_NetCfg_VES3_I "Backup for CAN I Video Ent. System screen 1 Module (1=present)";
CM_ SG_ 998 BU_NetCfg_VRM "Backup for Video Routing Module (1=present)";
CM_ SG_ 998 BU_NetCfg_VSIM "Backup for Vehicle System Interface Module (1=present)";
CM_ SG_ 998 BU_NetCfg_VTM "Backup for vehicle theft / tax module (1=present)";
CM_ SG_ 999 BU_NET_CFG_STAT_PT "Backup for network configuration status";
CM_ SG_ 999 BU_NetCfg_ACC "Backup for Active Cruise Control (1=present)";
CM_ SG_ 999 BU_NetCfg_ADCM "Backup for Active Damping Control Module (1=present)";
CM_ SG_ 999 BU_NetCfg_AFLS "Backup for Advanced Front Lighting System (1=present)";
CM_ SG_ 999 BU_NetCfg_AHLM "Backup for Automatic Headlamp Leveling Module (1=present)";
CM_ SG_ 999 BU_NetCfg_ANC "Backup for Active Noise Cancellation (1=present)";
CM_ SG_ 999 BU_NetCfg_ASBS "Automatic Sway Bar System Module (Present = 1, Not Present = 0)";
CM_ SG_ 999 BU_NetCfg_ASCM "Backup for Air Suspension Control Module (1=present)";
CM_ SG_ 999 BU_NetCfg_BSMO "Backup for Brake System Module - OBD (1=present)";
CM_ SG_ 999 BU_NetCfg_CBC_PT "Backup for Common Body Controller PT Bus (1=present)";
CM_ SG_ 999 BU_NetCfg_DASM "Backup for Driver Assistance System Module (1=present)";
CM_ SG_ 999 BU_NetCfg_DPDM "Backup for Driver Presence Detection Module (1=present)";
CM_ SG_ 999 BU_NetCfg_DTCM "Backup for Drivetrain Control Module (1=present)";
CM_ SG_ 999 BU_NetCfg_ECM "Backup for Engine Control Module (1=present)";
CM_ SG_ 999 BU_NetCfg_ELSD "Backup for Electric Limited Slip Differential (1=present)";
CM_ SG_ 999 BU_NetCfg_EPB "Backup for Electric Park Brake Module (1=present)";
CM_ SG_ 999 BU_NetCfg_EPPM "Backup for  Elect. Pedestrian protection module (1=present)";
CM_ SG_ 999 BU_NetCfg_EPS "Backup for Electric Power Steering (1=present)";
CM_ SG_ 999 BU_NetCfg_ESC "Backup for Electronic Stability Module / Anti-Lock Brake (1=present)";
CM_ SG_ 999 BU_NetCfg_ESL "Backup for Electric Steering Lock (1=present)";
CM_ SG_ 999 BU_NetCfg_ESM "Backup for Electronic Shift Module (1=present)";
CM_ SG_ 999 BU_NetCfg_FDCM "Backup for Final Drive Control Module (1=present)";
CM_ SG_ 999 BU_NetCfg_GPF "Gasoline Particulate Filter Net Config Backup, Present=1";
CM_ SG_ 999 BU_NetCfg_HCP "Backup for Hybrid Control Processor (1=present)";
CM_ SG_ 999 BU_NetCfg_HaLF "Backup for Haptic Lane Feedback module (1=present)";
CM_ SG_ 999 BU_NetCfg_IC "Backup for Instrument Cluster (1=present)";
CM_ SG_ 999 BU_NetCfg_ITBM "Backup for Integrated Trailer Brake Module (1=present)";
CM_ SG_ 999 BU_NetCfg_OCM "Backup for Occupant Classification Module (1=present)";
CM_ SG_ 999 BU_NetCfg_ORC "Backup for Occupant Restraint Controller (1=present)";
CM_ SG_ 999 BU_NetCfg_PASS_PT "Backup for Personal Assistant Safety System Module PT Bus (1=present)";
CM_ SG_ 999 BU_NetCfg_PTS "Backup for Parktronics System (1=present)";
CM_ SG_ 999 BU_NetCfg_RF_HUB "Backup for RF HUB Node (1=present)";
CM_ SG_ 999 BU_NetCfg_SCCM "Backup for Steering Column Control Module (1=present)";
CM_ SG_ 999 BU_NetCfg_SGW "Backup for Security GateWay (1=present)";
CM_ SG_ 999 BU_NetCfg_TCM "Backup for Automatic Transmission Controller (1=present)";
CM_ SG_ 999 BU_NetCfg_TIM "Backup for TIM (1=present)";
CM_ SG_ 999 BU_NetCfg_TPM "Backup for Tire Pressure Monitor (1=present)";
CM_ SG_ 999 BU_NetCfg_TTPM "Backup for TTPM (1=present)";
CM_ SG_ 999 BU_NetCfg_VSIM_C "Backup for Vehicle System Interface Module (1=present)";
CM_ SG_ 927 BU_NET_CFG_STAT_ePT "Backup for network configuration status";
CM_ SG_ 927 BU_NetCfg_AHCP_ePT "Backup for Auxiliary Hybrid Control Processor (1=present)";
CM_ SG_ 927 BU_NetCfg_APM_ePT "Backup for Auxiliary Power Module (1=present)";
CM_ SG_ 927 BU_NetCfg_BPCM_ePT "Backup for Battery Pack Control Module (1=present)";
CM_ SG_ 927 BU_NetCfg_BSMO_ePT "Backup for Brake System Module - OBD (1=present)";
CM_ SG_ 927 BU_NetCfg_EAC_ePT "Backup for Electric AC Compressor (1=present)";
CM_ SG_ 927 BU_NetCfg_EBCM_ePT "Backup for Electronic Boost Control Module (1=present)";
CM_ SG_ 927 BU_NetCfg_ECM_ePT "Backup for Engine Controller Module (1=present)";
CM_ SG_ 927 BU_NetCfg_ESC_ePT "Backup for Electronic Stability Control (1=present)";
CM_ SG_ 927 BU_NetCfg_ESM_ePT "Backup for Electronic Shifter Module (1=present)";
CM_ SG_ 927 BU_NetCfg_HCP_ePT "Backup for Hybrid Control Processor (1=present)";
CM_ SG_ 927 BU_NetCfg_IDCM_ePT "Backup for Integrated Dual Charge Module Net Config (1=present)";
CM_ SG_ 927 BU_NetCfg_MCPA_ePT "Backup for Motor Control Processor A (1=present)";
CM_ SG_ 927 BU_NetCfg_OBCM_ePT "Backup for On Board Charging Module (1=present)";
CM_ SG_ 927 BU_NetCfg_ORC_ePT "Backup for Occupant Restraint Controller (1=present)";
CM_ SG_ 927 BU_NetCfg_SCA_ePT "Backup for Smart Cluch Actuator (1=present)";
CM_ SG_ 937 DRL_ON "Daytime running lamps on; enabled = [1]";
CM_ SG_ 937 FLASH_LK "Flash lamps with lock; no = [0], yes = [1]";
CM_ SG_ 937 HL_DLY_TIME "Headlamp delay time";
CM_ SG_ 937 HL_WPR "Headlamp on with wiper; no = [0], yes =[1]";
CM_ SG_ 937 ILL_APRCH_TIME "Illuminated approach time";
CM_ SG_ 937 SOUND_LK "Sound horn on lock; no = [0], yes = [1]";
CM_ SG_ 937 SOUND_LK_1ST_2ND "Sound horn on lock status";
CM_ SG_ 937 SOUND_RS "Sound horn on Remote Start ; no = [0], yes = [1]";
CM_ SG_ 685 CBC_AUX1_HLEnbl "Aux switch 1 enable holding last state; enabled = [1]";
CM_ SG_ 685 CBC_AUX1_PWRMD "Aux switch 1 power mode; ignition = [0], battery = [1]";
CM_ SG_ 685 CBC_AUX1_Type "Aux switch 1 behavior; Latching = [0], Momentary = [1]";
CM_ SG_ 685 CBC_AUX2_HLEnbl "Aux switch 2 enable holding last state; enabled = [1]";
CM_ SG_ 685 CBC_AUX2_PWRMD "Aux switch 2 power mode; ignition = [0], battery = [1]";
CM_ SG_ 685 CBC_AUX2_Type "Aux switch 2 behavior; Latching = [0], Momentary = [1]";
CM_ SG_ 685 CBC_AUX3_HLEnbl "Aux switch 3 enable holding last state; enabled = [1]";
CM_ SG_ 685 CBC_AUX3_PWRMD "Aux switch 3 power mode; ignition = [0], battery = [1]";
CM_ SG_ 685 CBC_AUX3_Type "Aux switch 3 behavior; Latching = [0], Momentary = [1]";
CM_ SG_ 685 CBC_AUX4_HLEnbl "Aux switch 4 enable holding last state; enabled = [1]";
CM_ SG_ 685 CBC_AUX4_PWRMD "Aux switch 4 power mode; ignition = [0], battery = [1]";
CM_ SG_ 685 CBC_AUX4_Type "Aux switch 4 behavior; Latching = [0], Momentary = [1]";
CM_ SG_ 685 Cfg_Aux_PTO "AUX Switches Configuration";
CM_ SG_ 657 AHB_ACT "Automatic high beam active";
CM_ SG_ 657 BRK_FLUID_LO "Low brake fluid warning; low = [1]";
CM_ SG_ 657 DAY_LGT_MD "Day light brightness mode; Night=[0], Day=[1]";
CM_ SG_ 657 DRV_AJAR "Driver door ajar (1 = Door Ajar)";
CM_ SG_ 657 DR_LK_STAT "Door lock status";
CM_ SG_ 657 FOB_SrchRq "FOB search request";
CM_ SG_ 657 FT_FOG_RQ "Front fog request; off=[0], on=[1]";
CM_ SG_ 657 FT_WPR_NOT_PRK "Front wiper outside park position";
CM_ SG_ 657 HIBEAM_ON "High beam is on; off=[0], on=[1]";
CM_ SG_ 657 IGN_OFF_TIME_LNG "Time since last ignition on (long)";
CM_ SG_ 657 LOBEAM_ON "Low beam is on; off=[0], on=[1]";
CM_ SG_ 657 L_R_AJAR "Left rear door ajar";
CM_ SG_ 657 PANEL_INTS "Panel-/display intensity";
CM_ SG_ 657 PARK_BRK_EGD "Park brake switch engaged";
CM_ SG_ 657 PARK_LMP_ON "Parklamps are on; off=[0], on=[1]";
CM_ SG_ 657 PSG_AJAR "Passenger door ajar";
CM_ SG_ 657 PTC_REL1_STAT "PTC Relay # 1 Status";
CM_ SG_ 657 PTC_REL2_STAT "PTC Relay # 2 Status";
CM_ SG_ 657 PTC_REL3_STAT "PTC Relay # 3 Status";
CM_ SG_ 657 REV_GEAR "Reverse Gear (manual trans)";
CM_ SG_ 657 R_FOG_RQ "Rear fog request; [0] = off, [1] = on";
CM_ SG_ 657 R_R_AJAR "Right rear door ajar";
CM_ SG_ 657 SHIP_STAT "Shipping status";
CM_ SG_ 657 TLG_AJAR "Trunk/Liftgate ajar";
CM_ SG_ 657 TurnInd_LT_ON "Turn indication left is on";
CM_ SG_ 657 TurnInd_RT_ON "Turn indication right is on";
CM_ SG_ 657 WASH_FLUID_LO "Low washer fluid warning (1=Fluid is low)";
CM_ SG_ 613 AUX_UNAV_BATT_CHRG "AUX unaviable due to battery charging warning, 1 = Unaviable";
CM_ SG_ 613 DriverDoorOnOffSts "Driver door on/off status";
CM_ SG_ 613 DrvMd_PopUpRqst "Drive modes HMI pop-up message request";
CM_ SG_ 613 Exhaust_RQ_ICS "Exhaust button press status";
CM_ SG_ 613 LHRDoorOnOffSts "Left rear door on/off status";
CM_ SG_ 613 PsngrDoorOnOffSts "Passenger door on/off status";
CM_ SG_ 613 RHRDoorOnOffSts "Right rear door on/off status";
CM_ SG_ 119 CmdIgnStat "Commanded ignition switch status";
CM_ SG_ 119 KeyInIgn "Key in ignition status";
CM_ SG_ 119 RemStActv "Ignition run active for remote start (0=not active, 1=active)";
CM_ SG_ 119 StTyp "Type of start being requested";
CM_ SG_ 119 StartRelayBCMFault "CBC starter relay fault detected";
CM_ SG_ 119 StartRelayBCMSts "CBC starter relay status; [1] = ON";
CM_ SG_ 299 AMB_TEMP_AVG "Averaged ambient temperature";
CM_ SG_ 299 AMB_TEMP_VOLT "Ambient Temp Sensor A/D Voltage";
CM_ SG_ 299 AirTemp_Outsd "Outside air temperature";
CM_ SG_ 299 BATT_VOLT "System voltage";
CM_ SG_ 299 FUEL_VOLT "Fuel level A/D Voltage (Single tank OR Primary on Saddle/Dual Tank)";
CM_ SG_ 643 ACC_DLY_ACT "Accessory Delay Active";
CM_ SG_ 643 HdAjar "Hood latch ajar, left or single (1=ajar)";
CM_ SG_ 643 RemSt_Inhibit "Remote start inhibit";
CM_ SG_ 643 TurnLmp_FL_Flt "Turn indication lamp front left fault";
CM_ SG_ 643 TurnLmp_FR_Flt "Turn indication lamp front right fault";
CM_ SG_ 643 TurnLmp_RL_Flt "Turn indication lamp rear left fault";
CM_ SG_ 643 TurnLmp_RR_Flt "Turn indication lamp rear right fault";
CM_ SG_ 643 WPR_SYS_AUTO "Wiper system auto; [1] = Auto wipers equipped";
CM_ SG_ 643 WPR_SYS_FLT "Wiper system fault present; [1] = fault present";
CM_ SG_ 643 WPR_SYS_HIGH "Wiper system high; [1] = switch is HIGH";
CM_ SG_ 643 WPR_SYS_INT "Wiper system intermittent; [1] = switch is INT";
CM_ SG_ 643 WPR_SYS_LOW "Wiper system low; [1] = switch is LOW";
CM_ SG_ 643 WPR_SYS_MIST "Wiper system mist; [1] = mist request";
CM_ SG_ 643 WPR_SYS_OFF "Wiper system off; [1] = switch is OFF";
CM_ SG_ 643 WPR_SYS_WASH "Wiper system wash; [1] = wash request";
BA_DEF_ BO_  "App-Botschaft" ENUM  "nein","ja";
BA_DEF_ BO_  "CanMsgMinLen" INT 0 8;
BA_DEF_ BO_  "DiagRequest" ENUM  "nein","ja";
BA_DEF_ BO_  "DiagResponse" ENUM  "nein","ja";
BA_DEF_ BO_  "DiagState" ENUM  "nein","ja";
BA_DEF_ BO_  "GenMsgCycleTime" INT 0 65535;
BA_DEF_ BO_  "GenMsgCycleTimeActive" INT 0 65535;
BA_DEF_ BO_  "GenMsgDelayTime" INT 0 65535;
BA_DEF_ BO_  "GenMsgNrOfRepetitions" INT 0 65535;
BA_DEF_ BO_  "GenMsgSendType" ENUM  "cyclicX","spontanX","cyclicIfActiveX","spontanWithDelay","cyclicAndSpontanX","cyclicAndSpontanWithDelay","spontanWithRepitition","cyclicIfActiveAndSpontanWD","cyclicIfActiveFast","cyclicWithRepeatOnDemand","none";
BA_DEF_ BO_  "GenMsgStartDelayTime" INT 0 65535;
BA_DEF_ BO_  "GenMsgStartValue" STRING ;
BA_DEF_ BO_  "NWM-Botschaft" ENUM  "nein","ja";
BA_DEF_ BO_  "TpTxIndex" INT 0 99;
BA_DEF_  "Baudrate" INT 0 1000000;
BA_DEF_  "Manufacturer" ENUM  "DBAG","VAG","BMWAG","PAG","GM";
BA_DEF_  "NBTMax" INT 0 255;
BA_DEF_  "NBTMin" INT 0 255;
BA_DEF_  "NmMessageCount" INT 0 64;
BA_DEF_  "NWM-Basisadresse" HEX 0 536870911;
BA_DEF_  "NWM-Typ" ENUM  "zentral (MB-W210)","dezentral (MB-OSAN)","keines","VAG-OSEK","BMW-OSEK","PAG-OSEK","DBAG-OSEK";
BA_DEF_  "SamplePointMax" FLOAT 0 100;
BA_DEF_  "SamplePointMin" FLOAT 0 100;
BA_DEF_  "Version" HEX 0 4080;
BA_DEF_  "VersionWeek" INT 0 53;
BA_DEF_  "VersionYear" INT 0 99;
BA_DEF_ BU_  "NWM-Knoten" ENUM  "nein","ja";
BA_DEF_ BU_  "NWM-Stationsadresse" HEX 0 63;
BA_DEF_ BU_  "TpNodeBaseAddress" HEX 0 65535;
BA_DEF_ BU_  "TpOwnSystemEcuNumber" HEX 0 255;
BA_DEF_ SG_  "FlexKomComment" STRING ;
BA_DEF_ SG_  "FlexKomIsMotorola" ENUM  "nein","ja";
BA_DEF_ SG_  "FlexKomSID" INT 0 2147483647;
BA_DEF_ SG_  "FlexKomSigLaenge" INT 0 64;
BA_DEF_ SG_  "FlexKomSigName" STRING ;
BA_DEF_ SG_  "FlexKomSigStartPos" INT 0 63;
BA_DEF_ SG_  "FlexKomSigStartValue" STRING ;
BA_DEF_ SG_  "GenSigCycleTime" INT 0 65535;
BA_DEF_ SG_  "GenSigCycleTimeActive" INT 0 65535;
BA_DEF_ SG_  "GenSigSendType" ENUM  "cyclicX","spontanX","cyclicIfActiveX","spontanWithDelay","cyclicAndSpontanX","cyclicAndSpontanWithDelay","spontanWithRepitition","cyclicIfActiveAndSpontanWD","cyclicIfActiveFast","cyclicWithRepeatOnDemand","none";
BA_DEF_ SG_  "GenSigSNA" STRING ;
BA_DEF_ SG_  "GenSigStartValue" HEX 0 2147483648;
BA_DEF_ SG_  "GenSigTimeout_AHLM" INT 0 65535;
BA_DEF_ SG_  "GenSigTimeout_ASBS" INT 0 65535;
BA_DEF_ SG_  "GenSigTimeout_CBC" INT 0 65535;
BA_DEF_ SG_  "GenSigTimeout_DPDM" INT 0 65535;
BA_DEF_ SG_  "GenSigTimeout_DTCM" INT 0 65535;
BA_DEF_ SG_  "GenSigTimeout_EHPS" INT 0 65535;
BA_DEF_ SG_  "GenSigTimeout_ESC" INT 0 65535;
BA_DEF_ SG_  "GenSigTimeout_ESL" INT 0 65535;
BA_DEF_ SG_  "GenSigTimeout_ESM" INT 0 65535;
BA_DEF_ SG_  "GenSigTimeout_ETM" INT 0 65535;
BA_DEF_ SG_  "GenSigTimeout_IC" INT 0 65535;
BA_DEF_ SG_  "GenSigTimeout_OCM" INT 0 65535;
BA_DEF_ SG_  "GenSigTimeout_ORC" INT 0 65535;
BA_DEF_ SG_  "GenSigTimeout_PTS" INT 0 65535;
BA_DEF_ SG_  "GenSigTimeout_RF_HUB" INT 0 65535;
BA_DEF_ SG_  "GenSigTimeout_SCCM" INT 0 65535;
BA_DEF_ SG_  "GenSigTimeout_TBM" INT 0 65535;
BA_DEF_ SG_  "GenSigTimeout_TCM" INT 0 65535;
BA_DEF_ SG_  "GenSigTimeout_TPM" INT 0 65535;
BA_DEF_ SG_  "RID" STRING ;
BA_DEF_ SG_  "SystemSignalLongSymbol" STRING ;
BA_DEF_DEF_  "App-Botschaft" "nein";
BA_DEF_DEF_  "CanMsgMinLen" 0;
BA_DEF_DEF_  "DiagRequest" "nein";
BA_DEF_DEF_  "DiagResponse" "nein";
BA_DEF_DEF_  "DiagState" "nein";
BA_DEF_DEF_  "GenMsgCycleTime" 0;
BA_DEF_DEF_  "GenMsgCycleTimeActive" 0;
BA_DEF_DEF_  "GenMsgDelayTime" 0;
BA_DEF_DEF_  "GenMsgNrOfRepetitions" 0;
BA_DEF_DEF_  "GenMsgSendType" "cyclicX";
BA_DEF_DEF_  "GenMsgStartDelayTime" 0;
BA_DEF_DEF_  "GenMsgStartValue" "";
BA_DEF_DEF_  "NWM-Botschaft" "nein";
BA_DEF_DEF_  "TpTxIndex" 0;
BA_DEF_DEF_  "Baudrate" 500000;
BA_DEF_DEF_  "Manufacturer" "DBAG";
BA_DEF_DEF_  "NBTMax" 20;
BA_DEF_DEF_  "NBTMin" 10;
BA_DEF_DEF_  "NmMessageCount" 64;
BA_DEF_DEF_  "NWM-Basisadresse" 1024;
BA_DEF_DEF_  "NWM-Typ" "DBAG-OSEK";
BA_DEF_DEF_  "SamplePointMax" 81.25;
BA_DEF_DEF_  "SamplePointMin" 75;
BA_DEF_DEF_  "Version" 1;
BA_DEF_DEF_  "VersionWeek" 29;
BA_DEF_DEF_  "VersionYear" 19;
BA_DEF_DEF_  "NWM-Knoten" "nein";
BA_DEF_DEF_  "NWM-Stationsadresse" 0;
BA_DEF_DEF_  "TpNodeBaseAddress" 0;
BA_DEF_DEF_  "TpOwnSystemEcuNumber" 0;
BA_DEF_DEF_  "FlexKomComment" "";
BA_DEF_DEF_  "FlexKomIsMotorola" "nein";
BA_DEF_DEF_  "FlexKomSID" 0;
BA_DEF_DEF_  "FlexKomSigLaenge" 0;
BA_DEF_DEF_  "FlexKomSigName" "";
BA_DEF_DEF_  "FlexKomSigStartPos" 0;
BA_DEF_DEF_  "FlexKomSigStartValue" "";
BA_DEF_DEF_  "GenSigCycleTime" 0;
BA_DEF_DEF_  "GenSigCycleTimeActive" 0;
BA_DEF_DEF_  "GenSigSendType" "cyclicX";
BA_DEF_DEF_  "GenSigSNA" "";
BA_DEF_DEF_  "GenSigStartValue" 0;
BA_DEF_DEF_  "GenSigTimeout_AHLM" 0;
BA_DEF_DEF_  "GenSigTimeout_ASBS" 0;
BA_DEF_DEF_  "GenSigTimeout_CBC" 0;
BA_DEF_DEF_  "GenSigTimeout_DPDM" 0;
BA_DEF_DEF_  "GenSigTimeout_DTCM" 0;
BA_DEF_DEF_  "GenSigTimeout_EHPS" 0;
BA_DEF_DEF_  "GenSigTimeout_ESC" 0;
BA_DEF_DEF_  "GenSigTimeout_ESL" 0;
BA_DEF_DEF_  "GenSigTimeout_ESM" 0;
BA_DEF_DEF_  "GenSigTimeout_ETM" 0;
BA_DEF_DEF_  "GenSigTimeout_IC" 0;
BA_DEF_DEF_  "GenSigTimeout_OCM" 0;
BA_DEF_DEF_  "GenSigTimeout_ORC" 0;
BA_DEF_DEF_  "GenSigTimeout_PTS" 0;
BA_DEF_DEF_  "GenSigTimeout_RF_HUB" 0;
BA_DEF_DEF_  "GenSigTimeout_SCCM" 0;
BA_DEF_DEF_  "GenSigTimeout_TBM" 0;
BA_DEF_DEF_  "GenSigTimeout_TCM" 0;
BA_DEF_DEF_  "GenSigTimeout_TPM" 0;
BA_DEF_DEF_  "RID" "";
BA_DEF_DEF_  "SystemSignalLongSymbol" "";
BA_ "NWM-Stationsadresse" BU_ CBC 1;
BA_ "NWM-Knoten" BU_ CBC 1;
BA_ "NWM-Stationsadresse" BU_ EHPS 26;
BA_ "NWM-Knoten" BU_ EHPS 1;
BA_ "NWM-Stationsadresse" BU_ ESC 7;
BA_ "NWM-Knoten" BU_ ESC 1;
BA_ "NWM-Stationsadresse" BU_ ESL 8;
BA_ "NWM-Knoten" BU_ ESL 1;
BA_ "NWM-Stationsadresse" BU_ ESM 9;
BA_ "NWM-Knoten" BU_ ESM 1;
BA_ "NWM-Stationsadresse" BU_ HCP 58;
BA_ "NWM-Knoten" BU_ HCP 1;
BA_ "NWM-Stationsadresse" BU_ IC 2;
BA_ "NWM-Knoten" BU_ IC 1;
BA_ "NWM-Knoten" BU_ RF_HUB 1;
BA_ "NWM-Stationsadresse" BU_ SCCM 35;
BA_ "NWM-Knoten" BU_ SCCM 1;
BA_ "NWM-Stationsadresse" BU_ TPM 3;
BA_ "NWM-Knoten" BU_ TPM 1;
BA_ "GenMsgStartValue" BO_ 969 "FFFF0000h";
BA_ "GenMsgNrOfRepetitions" BO_ 969 2;
BA_ "GenMsgDelayTime" BO_ 969 20;
BA_ "GenMsgCycleTime" BO_ 969 1000;
BA_ "GenMsgStartValue" BO_ 1769 "0000000000000000h";
BA_ "GenMsgSendType" BO_ 1769 1;
BA_ "GenMsgNrOfRepetitions" BO_ 1769 2;
BA_ "GenMsgDelayTime" BO_ 1769 20;
BA_ "App-Botschaft" BO_ 1769 1;
BA_ "GenMsgStartValue" BO_ 1738 "0000000000000000h";
BA_ "GenMsgSendType" BO_ 1738 1;
BA_ "GenMsgNrOfRepetitions" BO_ 1738 2;
BA_ "GenMsgDelayTime" BO_ 1738 20;
BA_ "App-Botschaft" BO_ 1738 1;
BA_ "GenMsgStartValue" BO_ 1788 "0000000000000000h";
BA_ "GenMsgSendType" BO_ 1788 1;
BA_ "GenMsgNrOfRepetitions" BO_ 1788 2;
BA_ "GenMsgDelayTime" BO_ 1788 20;
BA_ "App-Botschaft" BO_ 1788 1;
BA_ "GenMsgStartValue" BO_ 1729 "0000000000000000h";
BA_ "GenMsgSendType" BO_ 1729 1;
BA_ "GenMsgNrOfRepetitions" BO_ 1729 2;
BA_ "GenMsgDelayTime" BO_ 1729 20;
BA_ "App-Botschaft" BO_ 1729 1;
BA_ "GenMsgStartValue" BO_ 1747 "0000000000000000h";
BA_ "GenMsgSendType" BO_ 1747 1;
BA_ "GenMsgNrOfRepetitions" BO_ 1747 2;
BA_ "GenMsgDelayTime" BO_ 1747 20;
BA_ "App-Botschaft" BO_ 1747 1;
BA_ "GenMsgStartValue" BO_ 1745 "0000000000000000h";
BA_ "GenMsgSendType" BO_ 1745 1;
BA_ "GenMsgNrOfRepetitions" BO_ 1745 2;
BA_ "GenMsgDelayTime" BO_ 1745 20;
BA_ "App-Botschaft" BO_ 1745 1;
BA_ "GenMsgStartValue" BO_ 1739 "0000000000000000h";
BA_ "GenMsgSendType" BO_ 1739 1;
BA_ "GenMsgNrOfRepetitions" BO_ 1739 2;
BA_ "GenMsgDelayTime" BO_ 1739 20;
BA_ "App-Botschaft" BO_ 1739 1;
BA_ "GenMsgStartValue" BO_ 1784 "0000000000000000h";
BA_ "GenMsgSendType" BO_ 1784 1;
BA_ "GenMsgNrOfRepetitions" BO_ 1784 2;
BA_ "GenMsgDelayTime" BO_ 1784 20;
BA_ "App-Botschaft" BO_ 1784 1;
BA_ "GenMsgStartValue" BO_ 1754 "0000000000000000h";
BA_ "GenMsgSendType" BO_ 1754 1;
BA_ "GenMsgNrOfRepetitions" BO_ 1754 2;
BA_ "GenMsgDelayTime" BO_ 1754 20;
BA_ "App-Botschaft" BO_ 1754 1;
BA_ "GenMsgStartValue" BO_ 1735 "0000000000000000h";
BA_ "GenMsgSendType" BO_ 1735 1;
BA_ "GenMsgNrOfRepetitions" BO_ 1735 2;
BA_ "GenMsgDelayTime" BO_ 1735 20;
BA_ "App-Botschaft" BO_ 1735 1;
BA_ "GenMsgStartValue" BO_ 1736 "0000000000000000h";
BA_ "GenMsgSendType" BO_ 1736 1;
BA_ "GenMsgNrOfRepetitions" BO_ 1736 2;
BA_ "GenMsgDelayTime" BO_ 1736 20;
BA_ "App-Botschaft" BO_ 1736 1;
BA_ "GenMsgStartValue" BO_ 1737 "0000000000000000h";
BA_ "GenMsgSendType" BO_ 1737 1;
BA_ "GenMsgNrOfRepetitions" BO_ 1737 2;
BA_ "GenMsgDelayTime" BO_ 1737 20;
BA_ "App-Botschaft" BO_ 1737 1;
BA_ "GenMsgStartValue" BO_ 1778 "0000000000000000h";
BA_ "GenMsgSendType" BO_ 1778 1;
BA_ "GenMsgNrOfRepetitions" BO_ 1778 2;
BA_ "GenMsgDelayTime" BO_ 1778 20;
BA_ "App-Botschaft" BO_ 1778 1;
BA_ "GenMsgStartValue" BO_ 1786 "0000000000000000h";
BA_ "GenMsgSendType" BO_ 1786 1;
BA_ "GenMsgNrOfRepetitions" BO_ 1786 2;
BA_ "GenMsgDelayTime" BO_ 1786 20;
BA_ "App-Botschaft" BO_ 1786 1;
BA_ "GenMsgStartValue" BO_ 1730 "0000000000000000h";
BA_ "GenMsgSendType" BO_ 1730 1;
BA_ "GenMsgNrOfRepetitions" BO_ 1730 2;
BA_ "GenMsgDelayTime" BO_ 1730 20;
BA_ "App-Botschaft" BO_ 1730 1;
BA_ "GenMsgStartValue" BO_ 1758 "0000000000000000h";
BA_ "GenMsgSendType" BO_ 1758 1;
BA_ "GenMsgNrOfRepetitions" BO_ 1758 2;
BA_ "GenMsgDelayTime" BO_ 1758 20;
BA_ "App-Botschaft" BO_ 1758 1;
BA_ "GenMsgStartValue" BO_ 1732 "0000000000000000h";
BA_ "GenMsgSendType" BO_ 1732 1;
BA_ "GenMsgNrOfRepetitions" BO_ 1732 2;
BA_ "GenMsgDelayTime" BO_ 1732 20;
BA_ "App-Botschaft" BO_ 1732 1;
BA_ "GenMsgStartValue" BO_ 1762 "0000000000000000h";
BA_ "GenMsgSendType" BO_ 1762 1;
BA_ "GenMsgNrOfRepetitions" BO_ 1762 2;
BA_ "GenMsgDelayTime" BO_ 1762 20;
BA_ "App-Botschaft" BO_ 1762 1;
BA_ "GenMsgStartValue" BO_ 1728 "0000000000000000h";
BA_ "GenMsgSendType" BO_ 1728 1;
BA_ "GenMsgNrOfRepetitions" BO_ 1728 2;
BA_ "GenMsgDelayTime" BO_ 1728 20;
BA_ "App-Botschaft" BO_ 1728 1;
BA_ "GenMsgStartValue" BO_ 1763 "0000000000000000h";
BA_ "GenMsgSendType" BO_ 1763 1;
BA_ "GenMsgNrOfRepetitions" BO_ 1763 2;
BA_ "GenMsgDelayTime" BO_ 1763 20;
BA_ "App-Botschaft" BO_ 1763 1;
BA_ "GenMsgStartValue" BO_ 1835 "0000000000000000h";
BA_ "GenMsgSendType" BO_ 1835 1;
BA_ "GenMsgNrOfRepetitions" BO_ 1835 2;
BA_ "GenMsgDelayTime" BO_ 1835 20;
BA_ "App-Botschaft" BO_ 1835 1;
BA_ "GenMsgStartValue" BO_ 1785 "0000000000000000h";
BA_ "GenMsgSendType" BO_ 1785 1;
BA_ "GenMsgNrOfRepetitions" BO_ 1785 2;
BA_ "GenMsgDelayTime" BO_ 1785 20;
BA_ "App-Botschaft" BO_ 1785 1;
BA_ "GenMsgStartValue" BO_ 1731 "0000000000000000h";
BA_ "GenMsgSendType" BO_ 1731 1;
BA_ "GenMsgNrOfRepetitions" BO_ 1731 2;
BA_ "GenMsgDelayTime" BO_ 1731 20;
BA_ "App-Botschaft" BO_ 1731 1;
BA_ "GenMsgStartValue" BO_ 881 "0000000000000000h";
BA_ "GenMsgSendType" BO_ 881 5;
BA_ "GenMsgNrOfRepetitions" BO_ 881 2;
BA_ "GenMsgDelayTime" BO_ 881 20;
BA_ "GenMsgCycleTime" BO_ 881 1000;
BA_ "GenMsgStartValue" BO_ 838 "0000h";
BA_ "GenMsgSendType" BO_ 838 5;
BA_ "GenMsgNrOfRepetitions" BO_ 838 2;
BA_ "GenMsgDelayTime" BO_ 838 20;
BA_ "GenMsgCycleTime" BO_ 838 1000;
BA_ "GenMsgStartValue" BO_ 523 "0000000000000000h";
BA_ "GenMsgSendType" BO_ 523 1;
BA_ "GenMsgNrOfRepetitions" BO_ 523 2;
BA_ "GenMsgDelayTime" BO_ 523 20;
BA_ "GenMsgStartValue" BO_ 524 "0000000000000000h";
BA_ "GenMsgSendType" BO_ 524 1;
BA_ "GenMsgNrOfRepetitions" BO_ 524 2;
BA_ "GenMsgDelayTime" BO_ 524 20;
BA_ "GenMsgStartValue" BO_ 525 "00h";
BA_ "GenMsgSendType" BO_ 525 1;
BA_ "GenMsgNrOfRepetitions" BO_ 525 2;
BA_ "GenMsgDelayTime" BO_ 525 20;
BA_ "GenMsgStartValue" BO_ 720 "0003C00006C0h";
BA_ "GenMsgSendType" BO_ 720 5;
BA_ "GenMsgNrOfRepetitions" BO_ 720 2;
BA_ "GenMsgDelayTime" BO_ 720 20;
BA_ "GenMsgCycleTime" BO_ 720 500;
BA_ "GenMsgStartValue" BO_ 998 "0300000000000000h";
BA_ "GenMsgSendType" BO_ 998 1;
BA_ "GenMsgNrOfRepetitions" BO_ 998 2;
BA_ "GenMsgDelayTime" BO_ 998 20;
BA_ "GenMsgStartValue" BO_ 999 "0300000000000000h";
BA_ "GenMsgSendType" BO_ 999 1;
BA_ "GenMsgNrOfRepetitions" BO_ 999 2;
BA_ "GenMsgDelayTime" BO_ 999 20;
BA_ "GenMsgStartValue" BO_ 927 "030000h";
BA_ "GenMsgSendType" BO_ 927 1;
BA_ "GenMsgNrOfRepetitions" BO_ 927 2;
BA_ "GenMsgDelayTime" BO_ 927 20;
BA_ "GenMsgStartValue" BO_ 937 "00FFFFFFFF60C003h";
BA_ "GenMsgStartDelayTime" BO_ 937 10;
BA_ "GenMsgSendType" BO_ 937 5;
BA_ "GenMsgNrOfRepetitions" BO_ 937 2;
BA_ "GenMsgDelayTime" BO_ 937 20;
BA_ "GenMsgCycleTime" BO_ 937 1000;
BA_ "GenMsgStartValue" BO_ 685 "000007000000FFFFh";
BA_ "GenMsgStartDelayTime" BO_ 685 110;
BA_ "GenMsgSendType" BO_ 685 5;
BA_ "GenMsgNrOfRepetitions" BO_ 685 2;
BA_ "GenMsgDelayTime" BO_ 685 20;
BA_ "GenMsgCycleTime" BO_ 685 1000;
BA_ "GenMsgStartValue" BO_ 657 "6000003FFFFC0000h";
BA_ "GenMsgStartDelayTime" BO_ 657 20;
BA_ "GenMsgSendType" BO_ 657 5;
BA_ "GenMsgNrOfRepetitions" BO_ 657 2;
BA_ "GenMsgDelayTime" BO_ 657 20;
BA_ "GenMsgCycleTime" BO_ 657 1000;
BA_ "GenMsgStartValue" BO_ 613 "00000000003F06FFh";
BA_ "GenMsgSendType" BO_ 613 5;
BA_ "GenMsgNrOfRepetitions" BO_ 613 2;
BA_ "GenMsgDelayTime" BO_ 613 20;
BA_ "GenMsgCycleTime" BO_ 613 1000;
BA_ "GenMsgStartValue" BO_ 119 "0000h";
BA_ "GenMsgNrOfRepetitions" BO_ 119 2;
BA_ "GenMsgDelayTime" BO_ 119 20;
BA_ "GenMsgCycleTime" BO_ 119 20;
BA_ "GenMsgStartValue" BO_ 299 "FFFFFFFFFFFFFFFFh";
BA_ "GenMsgNrOfRepetitions" BO_ 299 2;
BA_ "GenMsgDelayTime" BO_ 299 20;
BA_ "GenMsgCycleTime" BO_ 299 100;
BA_ "GenMsgStartValue" BO_ 643 "000C000000010000h";
BA_ "GenMsgStartDelayTime" BO_ 643 30;
BA_ "GenMsgSendType" BO_ 643 5;
BA_ "GenMsgNrOfRepetitions" BO_ 643 2;
BA_ "GenMsgDelayTime" BO_ 643 20;
BA_ "GenMsgCycleTime" BO_ 643 1000;
BA_ "GenSigTimeout_IC" SG_ 969 AMB_TEMP_AVG_C 10500;
BA_ "GenSigTimeout_DTCM" SG_ 969 AMB_TEMP_AVG_C 5500;
BA_ "GenSigStartValue" SG_ 969 AMB_TEMP_AVG_C 255;
BA_ "GenSigSNA" SG_ 969 AMB_TEMP_AVG_C "FFh";
BA_ "GenSigCycleTime" SG_ 969 AMB_TEMP_AVG_C 1000;
BA_ "FlexKomSigStartValue" SG_ 969 AMB_TEMP_AVG_C "FFh";
BA_ "FlexKomSigStartPos" SG_ 969 AMB_TEMP_AVG_C 15;
BA_ "FlexKomSigName" SG_ 969 AMB_TEMP_AVG_C "AMB_TEMP_AVG_C";
BA_ "FlexKomSigLaenge" SG_ 969 AMB_TEMP_AVG_C 8;
BA_ "FlexKomSID" SG_ 969 AMB_TEMP_AVG_C 1427;
BA_ "FlexKomIsMotorola" SG_ 969 AMB_TEMP_AVG_C 1;
BA_ "FlexKomComment" SG_ 969 AMB_TEMP_AVG_C "Ambient temperature average - in degrees Celsius";
BA_ "GenSigTimeout_IC" SG_ 969 AMB_TEMP_AVG_F 10500;
BA_ "GenSigStartValue" SG_ 969 AMB_TEMP_AVG_F 255;
BA_ "GenSigSNA" SG_ 969 AMB_TEMP_AVG_F "FFh";
BA_ "GenSigCycleTime" SG_ 969 AMB_TEMP_AVG_F 1000;
BA_ "FlexKomSigStartValue" SG_ 969 AMB_TEMP_AVG_F "FFh";
BA_ "FlexKomSigStartPos" SG_ 969 AMB_TEMP_AVG_F 7;
BA_ "FlexKomSigName" SG_ 969 AMB_TEMP_AVG_F "AMB_TEMP_AVG_F";
BA_ "FlexKomSigLaenge" SG_ 969 AMB_TEMP_AVG_F 8;
BA_ "FlexKomSID" SG_ 969 AMB_TEMP_AVG_F 1428;
BA_ "FlexKomIsMotorola" SG_ 969 AMB_TEMP_AVG_F 1;
BA_ "FlexKomComment" SG_ 969 AMB_TEMP_AVG_F "Ambient temperature average - in degrees Fahrenhei";
BA_ "GenSigSNA" SG_ 1769 APPL_ECU_AHLM "0h";
BA_ "GenSigSendType" SG_ 1769 APPL_ECU_AHLM 1;
BA_ "FlexKomSigStartValue" SG_ 1769 APPL_ECU_AHLM "0000000000000000h";
BA_ "FlexKomSigStartPos" SG_ 1769 APPL_ECU_AHLM 7;
BA_ "FlexKomSigName" SG_ 1769 APPL_ECU_AHLM "APPL_ECU_AHLM";
BA_ "FlexKomSigLaenge" SG_ 1769 APPL_ECU_AHLM 64;
BA_ "FlexKomSID" SG_ 1769 APPL_ECU_AHLM 275;
BA_ "FlexKomIsMotorola" SG_ 1769 APPL_ECU_AHLM 1;
BA_ "FlexKomComment" SG_ 1769 APPL_ECU_AHLM "External Application to ECU";
BA_ "GenSigSNA" SG_ 1738 APPL_ECU_ASBS "0h";
BA_ "GenSigSendType" SG_ 1738 APPL_ECU_ASBS 1;
BA_ "FlexKomSigStartValue" SG_ 1738 APPL_ECU_ASBS "0000000000000000h";
BA_ "FlexKomSigStartPos" SG_ 1738 APPL_ECU_ASBS 7;
BA_ "FlexKomSigName" SG_ 1738 APPL_ECU_ASBS "APPL_ECU_ASBS";
BA_ "FlexKomSigLaenge" SG_ 1738 APPL_ECU_ASBS 64;
BA_ "FlexKomSID" SG_ 1738 APPL_ECU_ASBS 2622;
BA_ "FlexKomIsMotorola" SG_ 1738 APPL_ECU_ASBS 1;
BA_ "FlexKomComment" SG_ 1738 APPL_ECU_ASBS "External Application to ECU";
BA_ "GenSigSNA" SG_ 1788 APPL_ECU_BSMO "0h";
BA_ "GenSigSendType" SG_ 1788 APPL_ECU_BSMO 1;
BA_ "FlexKomSigStartValue" SG_ 1788 APPL_ECU_BSMO "0000000000000000h";
BA_ "FlexKomSigStartPos" SG_ 1788 APPL_ECU_BSMO 7;
BA_ "FlexKomSigName" SG_ 1788 APPL_ECU_BSMO "APPL_ECU_BSMO";
BA_ "FlexKomSigLaenge" SG_ 1788 APPL_ECU_BSMO 64;
BA_ "FlexKomSID" SG_ 1788 APPL_ECU_BSMO 2285;
BA_ "FlexKomIsMotorola" SG_ 1788 APPL_ECU_BSMO 1;
BA_ "FlexKomComment" SG_ 1788 APPL_ECU_BSMO "External Application to ECU";
BA_ "GenSigSNA" SG_ 1729 APPL_ECU_CBC "0h";
BA_ "GenSigSendType" SG_ 1729 APPL_ECU_CBC 1;
BA_ "FlexKomSigStartValue" SG_ 1729 APPL_ECU_CBC "0000000000000000h";
BA_ "FlexKomSigStartPos" SG_ 1729 APPL_ECU_CBC 7;
BA_ "FlexKomSigName" SG_ 1729 APPL_ECU_CBC "APPL_ECU_CBC";
BA_ "FlexKomSigLaenge" SG_ 1729 APPL_ECU_CBC 64;
BA_ "FlexKomSID" SG_ 1729 APPL_ECU_CBC 280;
BA_ "FlexKomIsMotorola" SG_ 1729 APPL_ECU_CBC 1;
BA_ "FlexKomComment" SG_ 1729 APPL_ECU_CBC "External Application to ECU";
BA_ "GenSigSNA" SG_ 1747 APPL_ECU_DASM "0h";
BA_ "GenSigSendType" SG_ 1747 APPL_ECU_DASM 1;
BA_ "FlexKomSigStartValue" SG_ 1747 APPL_ECU_DASM "0000000000000000h";
BA_ "FlexKomSigStartPos" SG_ 1747 APPL_ECU_DASM 7;
BA_ "FlexKomSigName" SG_ 1747 APPL_ECU_DASM "APPL_ECU_DASM";
BA_ "FlexKomSigLaenge" SG_ 1747 APPL_ECU_DASM 64;
BA_ "FlexKomSID" SG_ 1747 APPL_ECU_DASM 298;
BA_ "FlexKomIsMotorola" SG_ 1747 APPL_ECU_DASM 1;
BA_ "FlexKomComment" SG_ 1747 APPL_ECU_DASM "External Application to ECU";
BA_ "GenSigSNA" SG_ 1745 APPL_ECU_DPDM "0h";
BA_ "GenSigSendType" SG_ 1745 APPL_ECU_DPDM 1;
BA_ "FlexKomSigStartValue" SG_ 1745 APPL_ECU_DPDM "0000000000000000h";
BA_ "FlexKomSigStartPos" SG_ 1745 APPL_ECU_DPDM 7;
BA_ "FlexKomSigName" SG_ 1745 APPL_ECU_DPDM "APPL_ECU_DPDM";
BA_ "FlexKomSigLaenge" SG_ 1745 APPL_ECU_DPDM 64;
BA_ "FlexKomSID" SG_ 1745 APPL_ECU_DPDM 2658;
BA_ "FlexKomIsMotorola" SG_ 1745 APPL_ECU_DPDM 1;
BA_ "FlexKomComment" SG_ 1745 APPL_ECU_DPDM "External Application to ECU";
BA_ "GenSigSNA" SG_ 1739 APPL_ECU_DTCM "0h";
BA_ "GenSigSendType" SG_ 1739 APPL_ECU_DTCM 1;
BA_ "FlexKomSigStartValue" SG_ 1739 APPL_ECU_DTCM "0000000000000000h";
BA_ "FlexKomSigStartPos" SG_ 1739 APPL_ECU_DTCM 7;
BA_ "FlexKomSigName" SG_ 1739 APPL_ECU_DTCM "APPL_ECU_DTCM";
BA_ "FlexKomSigLaenge" SG_ 1739 APPL_ECU_DTCM 64;
BA_ "FlexKomSID" SG_ 1739 APPL_ECU_DTCM 286;
BA_ "FlexKomIsMotorola" SG_ 1739 APPL_ECU_DTCM 1;
BA_ "FlexKomComment" SG_ 1739 APPL_ECU_DTCM "External Application to ECU";
BA_ "GenSigSNA" SG_ 1784 APPL_ECU_ECM "0h";
BA_ "GenSigSendType" SG_ 1784 APPL_ECU_ECM 1;
BA_ "FlexKomSigStartValue" SG_ 1784 APPL_ECU_ECM "0000000000000000h";
BA_ "FlexKomSigStartPos" SG_ 1784 APPL_ECU_ECM 7;
BA_ "FlexKomSigName" SG_ 1784 APPL_ECU_ECM "APPL_ECU_ECM";
BA_ "FlexKomSigLaenge" SG_ 1784 APPL_ECU_ECM 64;
BA_ "FlexKomSID" SG_ 1784 APPL_ECU_ECM 287;
BA_ "FlexKomIsMotorola" SG_ 1784 APPL_ECU_ECM 1;
BA_ "FlexKomComment" SG_ 1784 APPL_ECU_ECM "External Application to ECU";
BA_ "GenSigSNA" SG_ 1754 APPL_ECU_EPS "0h";
BA_ "GenSigSendType" SG_ 1754 APPL_ECU_EPS 1;
BA_ "FlexKomSigStartValue" SG_ 1754 APPL_ECU_EPS "0000000000000000h";
BA_ "FlexKomSigStartPos" SG_ 1754 APPL_ECU_EPS 7;
BA_ "FlexKomSigName" SG_ 1754 APPL_ECU_EPS "APPL_ECU_EPS";
BA_ "FlexKomSigLaenge" SG_ 1754 APPL_ECU_EPS 64;
BA_ "FlexKomSID" SG_ 1754 APPL_ECU_EPS 289;
BA_ "FlexKomIsMotorola" SG_ 1754 APPL_ECU_EPS 1;
BA_ "FlexKomComment" SG_ 1754 APPL_ECU_EPS "External Application to ECU";
BA_ "GenSigSNA" SG_ 1735 APPL_ECU_ESC "0h";
BA_ "GenSigSendType" SG_ 1735 APPL_ECU_ESC 1;
BA_ "FlexKomSigStartValue" SG_ 1735 APPL_ECU_ESC "0000000000000000h";
BA_ "FlexKomSigStartPos" SG_ 1735 APPL_ECU_ESC 7;
BA_ "FlexKomSigName" SG_ 1735 APPL_ECU_ESC "APPL_ECU_ESC";
BA_ "FlexKomSigLaenge" SG_ 1735 APPL_ECU_ESC 64;
BA_ "FlexKomSID" SG_ 1735 APPL_ECU_ESC 291;
BA_ "FlexKomIsMotorola" SG_ 1735 APPL_ECU_ESC 1;
BA_ "FlexKomComment" SG_ 1735 APPL_ECU_ESC "External Application to ECU";
BA_ "GenSigSNA" SG_ 1736 APPL_ECU_ESL "0h";
BA_ "GenSigSendType" SG_ 1736 APPL_ECU_ESL 1;
BA_ "FlexKomSigStartValue" SG_ 1736 APPL_ECU_ESL "0000000000000000h";
BA_ "FlexKomSigStartPos" SG_ 1736 APPL_ECU_ESL 7;
BA_ "FlexKomSigName" SG_ 1736 APPL_ECU_ESL "APPL_ECU_ESL";
BA_ "FlexKomSigLaenge" SG_ 1736 APPL_ECU_ESL 64;
BA_ "FlexKomSID" SG_ 1736 APPL_ECU_ESL 2338;
BA_ "FlexKomIsMotorola" SG_ 1736 APPL_ECU_ESL 1;
BA_ "FlexKomComment" SG_ 1736 APPL_ECU_ESL "External Application to ECU";
BA_ "GenSigSNA" SG_ 1737 APPL_ECU_ESM "0h";
BA_ "GenSigSendType" SG_ 1737 APPL_ECU_ESM 1;
BA_ "FlexKomSigStartValue" SG_ 1737 APPL_ECU_ESM "0000000000000000h";
BA_ "FlexKomSigStartPos" SG_ 1737 APPL_ECU_ESM 7;
BA_ "FlexKomSigName" SG_ 1737 APPL_ECU_ESM "APPL_ECU_ESM";
BA_ "FlexKomSigLaenge" SG_ 1737 APPL_ECU_ESM 64;
BA_ "FlexKomSID" SG_ 1737 APPL_ECU_ESM 290;
BA_ "FlexKomIsMotorola" SG_ 1737 APPL_ECU_ESM 1;
BA_ "FlexKomComment" SG_ 1737 APPL_ECU_ESM "External Application to ECU";
BA_ "GenSigSNA" SG_ 1778 APPL_ECU_GPF "0h";
BA_ "GenSigSendType" SG_ 1778 APPL_ECU_GPF 1;
BA_ "FlexKomSigStartValue" SG_ 1778 APPL_ECU_GPF "0000000000000000h";
BA_ "FlexKomSigStartPos" SG_ 1778 APPL_ECU_GPF 7;
BA_ "FlexKomSigName" SG_ 1778 APPL_ECU_GPF "APPL_ECU_EPS";
BA_ "FlexKomSigLaenge" SG_ 1778 APPL_ECU_GPF 64;
BA_ "FlexKomSID" SG_ 1778 APPL_ECU_GPF 2827;
BA_ "FlexKomIsMotorola" SG_ 1778 APPL_ECU_GPF 1;
BA_ "FlexKomComment" SG_ 1778 APPL_ECU_GPF "External Application to ECU";
BA_ "GenSigSNA" SG_ 1786 APPL_ECU_HCP "0h";
BA_ "GenSigSendType" SG_ 1786 APPL_ECU_HCP 1;
BA_ "FlexKomSigStartValue" SG_ 1786 APPL_ECU_HCP "0000000000000000h";
BA_ "FlexKomSigStartPos" SG_ 1786 APPL_ECU_HCP 7;
BA_ "FlexKomSigName" SG_ 1786 APPL_ECU_HCP "APPL_ECU_HCP";
BA_ "FlexKomSigLaenge" SG_ 1786 APPL_ECU_HCP 64;
BA_ "FlexKomSID" SG_ 1786 APPL_ECU_HCP 2117;
BA_ "FlexKomIsMotorola" SG_ 1786 APPL_ECU_HCP 1;
BA_ "FlexKomComment" SG_ 1786 APPL_ECU_HCP "External Application to ECU";
BA_ "GenSigSNA" SG_ 1730 APPL_ECU_IC "0h";
BA_ "GenSigSendType" SG_ 1730 APPL_ECU_IC 1;
BA_ "FlexKomSigStartValue" SG_ 1730 APPL_ECU_IC "0000000000000000h";
BA_ "FlexKomSigStartPos" SG_ 1730 APPL_ECU_IC 7;
BA_ "FlexKomSigName" SG_ 1730 APPL_ECU_IC "APPL_ECU_IC";
BA_ "FlexKomSigLaenge" SG_ 1730 APPL_ECU_IC 64;
BA_ "FlexKomSID" SG_ 1730 APPL_ECU_IC 296;
BA_ "FlexKomIsMotorola" SG_ 1730 APPL_ECU_IC 1;
BA_ "FlexKomComment" SG_ 1730 APPL_ECU_IC "External Application to ECU";
BA_ "GenSigSNA" SG_ 1758 APPL_ECU_OCM "0h";
BA_ "GenSigSendType" SG_ 1758 APPL_ECU_OCM 1;
BA_ "FlexKomSigStartValue" SG_ 1758 APPL_ECU_OCM "0000000000000000h";
BA_ "FlexKomSigStartPos" SG_ 1758 APPL_ECU_OCM 7;
BA_ "FlexKomSigName" SG_ 1758 APPL_ECU_OCM "APPL_ECU_OCM";
BA_ "FlexKomSigLaenge" SG_ 1758 APPL_ECU_OCM 64;
BA_ "FlexKomSID" SG_ 1758 APPL_ECU_OCM 1539;
BA_ "FlexKomIsMotorola" SG_ 1758 APPL_ECU_OCM 1;
BA_ "FlexKomComment" SG_ 1758 APPL_ECU_OCM "External Application to ECU";
BA_ "GenSigSNA" SG_ 1732 APPL_ECU_ORC "0h";
BA_ "GenSigSendType" SG_ 1732 APPL_ECU_ORC 1;
BA_ "FlexKomSigStartValue" SG_ 1732 APPL_ECU_ORC "0000000000000000h";
BA_ "FlexKomSigStartPos" SG_ 1732 APPL_ECU_ORC 7;
BA_ "FlexKomSigName" SG_ 1732 APPL_ECU_ORC "APPL_ECU_ORC";
BA_ "FlexKomSigLaenge" SG_ 1732 APPL_ECU_ORC 64;
BA_ "FlexKomSID" SG_ 1732 APPL_ECU_ORC 302;
BA_ "FlexKomIsMotorola" SG_ 1732 APPL_ECU_ORC 1;
BA_ "FlexKomComment" SG_ 1732 APPL_ECU_ORC "External Application to ECU";
BA_ "GenSigSNA" SG_ 1762 APPL_ECU_PTS "0h";
BA_ "GenSigSendType" SG_ 1762 APPL_ECU_PTS 1;
BA_ "FlexKomSigStartValue" SG_ 1762 APPL_ECU_PTS "0000000000000000h";
BA_ "FlexKomSigStartPos" SG_ 1762 APPL_ECU_PTS 7;
BA_ "FlexKomSigName" SG_ 1762 APPL_ECU_PTS "APPL_ECU_PTS";
BA_ "FlexKomSigLaenge" SG_ 1762 APPL_ECU_PTS 64;
BA_ "FlexKomSID" SG_ 1762 APPL_ECU_PTS 310;
BA_ "FlexKomIsMotorola" SG_ 1762 APPL_ECU_PTS 1;
BA_ "FlexKomComment" SG_ 1762 APPL_ECU_PTS "External Application to ECU";
BA_ "GenSigSNA" SG_ 1728 APPL_ECU_RF_HUB "0h";
BA_ "GenSigSendType" SG_ 1728 APPL_ECU_RF_HUB 1;
BA_ "FlexKomSigStartValue" SG_ 1728 APPL_ECU_RF_HUB "0000000000000000h";
BA_ "FlexKomSigStartPos" SG_ 1728 APPL_ECU_RF_HUB 7;
BA_ "FlexKomSigName" SG_ 1728 APPL_ECU_RF_HUB "APPL_ECU_RF_HUB";
BA_ "FlexKomSigLaenge" SG_ 1728 APPL_ECU_RF_HUB 64;
BA_ "FlexKomSID" SG_ 1728 APPL_ECU_RF_HUB 293;
BA_ "FlexKomIsMotorola" SG_ 1728 APPL_ECU_RF_HUB 1;
BA_ "FlexKomComment" SG_ 1728 APPL_ECU_RF_HUB "External Application to ECU";
BA_ "GenSigSNA" SG_ 1763 APPL_ECU_SCCM "0h";
BA_ "GenSigSendType" SG_ 1763 APPL_ECU_SCCM 1;
BA_ "FlexKomSigStartValue" SG_ 1763 APPL_ECU_SCCM "0000000000000000h";
BA_ "FlexKomSigStartPos" SG_ 1763 APPL_ECU_SCCM 7;
BA_ "FlexKomSigName" SG_ 1763 APPL_ECU_SCCM "APPL_ECU_SCCM";
BA_ "FlexKomSigLaenge" SG_ 1763 APPL_ECU_SCCM 64;
BA_ "FlexKomSID" SG_ 1763 APPL_ECU_SCCM 314;
BA_ "FlexKomIsMotorola" SG_ 1763 APPL_ECU_SCCM 1;
BA_ "FlexKomComment" SG_ 1763 APPL_ECU_SCCM "External Application to ECU";
BA_ "GenSigSNA" SG_ 1835 APPL_ECU_TBM "0h";
BA_ "GenSigSendType" SG_ 1835 APPL_ECU_TBM 1;
BA_ "FlexKomSigStartValue" SG_ 1835 APPL_ECU_TBM "0000000000000000h";
BA_ "FlexKomSigStartPos" SG_ 1835 APPL_ECU_TBM 7;
BA_ "FlexKomSigName" SG_ 1835 APPL_ECU_TBM "APPL_ECU_TBM";
BA_ "FlexKomSigLaenge" SG_ 1835 APPL_ECU_TBM 64;
BA_ "FlexKomSID" SG_ 1835 APPL_ECU_TBM 2932;
BA_ "FlexKomIsMotorola" SG_ 1835 APPL_ECU_TBM 1;
BA_ "FlexKomComment" SG_ 1835 APPL_ECU_TBM "External Application to ECU";
BA_ "GenSigSNA" SG_ 1785 APPL_ECU_TCM "0h";
BA_ "GenSigSendType" SG_ 1785 APPL_ECU_TCM 1;
BA_ "FlexKomSigStartValue" SG_ 1785 APPL_ECU_TCM "0000000000000000h";
BA_ "FlexKomSigStartPos" SG_ 1785 APPL_ECU_TCM 7;
BA_ "FlexKomSigName" SG_ 1785 APPL_ECU_TCM "APPL_ECU_TCM";
BA_ "FlexKomSigLaenge" SG_ 1785 APPL_ECU_TCM 64;
BA_ "FlexKomSID" SG_ 1785 APPL_ECU_TCM 318;
BA_ "FlexKomIsMotorola" SG_ 1785 APPL_ECU_TCM 1;
BA_ "FlexKomComment" SG_ 1785 APPL_ECU_TCM "External Application to ECU";
BA_ "GenSigSNA" SG_ 1731 APPL_ECU_TPM "0h";
BA_ "GenSigSendType" SG_ 1731 APPL_ECU_TPM 1;
BA_ "FlexKomSigStartValue" SG_ 1731 APPL_ECU_TPM "0000000000000000h";
BA_ "FlexKomSigStartPos" SG_ 1731 APPL_ECU_TPM 7;
BA_ "FlexKomSigName" SG_ 1731 APPL_ECU_TPM "APPL_ECU_TPM";
BA_ "FlexKomSigLaenge" SG_ 1731 APPL_ECU_TPM 64;
BA_ "FlexKomSID" SG_ 1731 APPL_ECU_TPM 321;
BA_ "FlexKomIsMotorola" SG_ 1731 APPL_ECU_TPM 1;
BA_ "FlexKomComment" SG_ 1731 APPL_ECU_TPM "External Application to ECU";
BA_ "GenSigTimeout_IC" SG_ 881 SwayBarEVICDisplay 10500;
BA_ "GenSigSNA" SG_ 881 SwayBarEVICDisplay "Fh";
BA_ "GenSigSendType" SG_ 881 SwayBarEVICDisplay 5;
BA_ "GenSigCycleTime" SG_ 881 SwayBarEVICDisplay 1000;
BA_ "FlexKomSigStartValue" SG_ 881 SwayBarEVICDisplay "0000000000000000h";
BA_ "FlexKomSigStartPos" SG_ 881 SwayBarEVICDisplay 7;
BA_ "FlexKomSigName" SG_ 881 SwayBarEVICDisplay "ASBS_1_Pkt";
BA_ "FlexKomSigLaenge" SG_ 881 SwayBarEVICDisplay 64;
BA_ "FlexKomSID" SG_ 881 SwayBarEVICDisplay 2631;
BA_ "FlexKomIsMotorola" SG_ 881 SwayBarEVICDisplay 1;
BA_ "FlexKomComment" SG_ 881 SwayBarEVICDisplay "ASBS message 1 packet";
BA_ "GenSigTimeout_CBC" SG_ 881 SwayBar_LEDRq 10500;
BA_ "GenSigSNA" SG_ 881 SwayBar_LEDRq "3h";
BA_ "GenSigSendType" SG_ 881 SwayBar_LEDRq 5;
BA_ "GenSigCycleTime" SG_ 881 SwayBar_LEDRq 1000;
BA_ "FlexKomSigStartValue" SG_ 881 SwayBar_LEDRq "0000000000000000h";
BA_ "FlexKomSigStartPos" SG_ 881 SwayBar_LEDRq 7;
BA_ "FlexKomSigName" SG_ 881 SwayBar_LEDRq "ASBS_1_Pkt";
BA_ "FlexKomSigLaenge" SG_ 881 SwayBar_LEDRq 64;
BA_ "FlexKomSID" SG_ 881 SwayBar_LEDRq 2631;
BA_ "FlexKomIsMotorola" SG_ 881 SwayBar_LEDRq 1;
BA_ "FlexKomComment" SG_ 881 SwayBar_LEDRq "ASBS message 1 packet";
BA_ "GenSigTimeout_IC" SG_ 881 SwayBar_Sts 10500;
BA_ "GenSigSNA" SG_ 881 SwayBar_Sts "3h";
BA_ "GenSigSendType" SG_ 881 SwayBar_Sts 5;
BA_ "GenSigCycleTime" SG_ 881 SwayBar_Sts 1000;
BA_ "FlexKomSigStartValue" SG_ 881 SwayBar_Sts "0000000000000000h";
BA_ "FlexKomSigStartPos" SG_ 881 SwayBar_Sts 7;
BA_ "FlexKomSigName" SG_ 881 SwayBar_Sts "ASBS_1_Pkt";
BA_ "FlexKomSigLaenge" SG_ 881 SwayBar_Sts 64;
BA_ "FlexKomSID" SG_ 881 SwayBar_Sts 2631;
BA_ "FlexKomIsMotorola" SG_ 881 SwayBar_Sts 1;
BA_ "FlexKomComment" SG_ 881 SwayBar_Sts "ASBS message 1 packet";
BA_ "RID" SG_ 838 AS_CHIME_REP_RATE "1192";
BA_ "GenSigSNA" SG_ 838 AS_CHIME_REP_RATE "0h";
BA_ "GenSigSendType" SG_ 838 AS_CHIME_REP_RATE 5;
BA_ "GenSigCycleTime" SG_ 838 AS_CHIME_REP_RATE 1000;
BA_ "FlexKomSigStartValue" SG_ 838 AS_CHIME_REP_RATE "0000h";
BA_ "FlexKomSigStartPos" SG_ 838 AS_CHIME_REP_RATE 7;
BA_ "FlexKomSigName" SG_ 838 AS_CHIME_REP_RATE "AS_CHIME_STAT";
BA_ "FlexKomSigLaenge" SG_ 838 AS_CHIME_REP_RATE 16;
BA_ "FlexKomSID" SG_ 838 AS_CHIME_REP_RATE 1016;
BA_ "FlexKomIsMotorola" SG_ 838 AS_CHIME_REP_RATE 1;
BA_ "FlexKomComment" SG_ 838 AS_CHIME_REP_RATE "AS chime status";
BA_ "RID" SG_ 838 AS_CHIME_TYPE "1056";
BA_ "GenSigTimeout_ORC" SG_ 838 AS_CHIME_TYPE 3500;
BA_ "GenSigTimeout_IC" SG_ 838 AS_CHIME_TYPE 10500;
BA_ "GenSigSNA" SG_ 838 AS_CHIME_TYPE "Fh";
BA_ "GenSigSendType" SG_ 838 AS_CHIME_TYPE 5;
BA_ "GenSigCycleTime" SG_ 838 AS_CHIME_TYPE 1000;
BA_ "FlexKomSigStartValue" SG_ 838 AS_CHIME_TYPE "0000h";
BA_ "FlexKomSigStartPos" SG_ 838 AS_CHIME_TYPE 7;
BA_ "FlexKomSigName" SG_ 838 AS_CHIME_TYPE "AS_CHIME_STAT";
BA_ "FlexKomSigLaenge" SG_ 838 AS_CHIME_TYPE 16;
BA_ "FlexKomSID" SG_ 838 AS_CHIME_TYPE 1016;
BA_ "FlexKomIsMotorola" SG_ 838 AS_CHIME_TYPE 1;
BA_ "FlexKomComment" SG_ 838 AS_CHIME_TYPE "AS chime status";
BA_ "RID" SG_ 838 AS_LF_CHIME_RQ "1121";
BA_ "GenSigSNA" SG_ 838 AS_LF_CHIME_RQ "0h";
BA_ "GenSigSendType" SG_ 838 AS_LF_CHIME_RQ 5;
BA_ "GenSigCycleTime" SG_ 838 AS_LF_CHIME_RQ 1000;
BA_ "FlexKomSigStartValue" SG_ 838 AS_LF_CHIME_RQ "0000h";
BA_ "FlexKomSigStartPos" SG_ 838 AS_LF_CHIME_RQ 7;
BA_ "FlexKomSigName" SG_ 838 AS_LF_CHIME_RQ "AS_CHIME_STAT";
BA_ "FlexKomSigLaenge" SG_ 838 AS_LF_CHIME_RQ 16;
BA_ "FlexKomSID" SG_ 838 AS_LF_CHIME_RQ 1016;
BA_ "FlexKomIsMotorola" SG_ 838 AS_LF_CHIME_RQ 1;
BA_ "FlexKomComment" SG_ 838 AS_LF_CHIME_RQ "AS chime status";
BA_ "RID" SG_ 838 AS_RF_CHIME_RQ "1245";
BA_ "GenSigSNA" SG_ 838 AS_RF_CHIME_RQ "0h";
BA_ "GenSigSendType" SG_ 838 AS_RF_CHIME_RQ 5;
BA_ "GenSigCycleTime" SG_ 838 AS_RF_CHIME_RQ 1000;
BA_ "FlexKomSigStartValue" SG_ 838 AS_RF_CHIME_RQ "0000h";
BA_ "FlexKomSigStartPos" SG_ 838 AS_RF_CHIME_RQ 7;
BA_ "FlexKomSigName" SG_ 838 AS_RF_CHIME_RQ "AS_CHIME_STAT";
BA_ "FlexKomSigLaenge" SG_ 838 AS_RF_CHIME_RQ 16;
BA_ "FlexKomSID" SG_ 838 AS_RF_CHIME_RQ 1016;
BA_ "FlexKomIsMotorola" SG_ 838 AS_RF_CHIME_RQ 1;
BA_ "FlexKomComment" SG_ 838 AS_RF_CHIME_RQ "AS chime status";
BA_ "GenSigSNA" SG_ 523 ControlEncodingESL "0h";
BA_ "GenSigSendType" SG_ 523 ControlEncodingESL 1;
BA_ "FlexKomSigStartValue" SG_ 523 ControlEncodingESL "0000000000000000h";
BA_ "FlexKomSigStartPos" SG_ 523 ControlEncodingESL 7;
BA_ "FlexKomSigName" SG_ 523 ControlEncodingESL "Code_ESL_RqPkt";
BA_ "FlexKomSigLaenge" SG_ 523 ControlEncodingESL 64;
BA_ "FlexKomSID" SG_ 523 ControlEncodingESL 2345;
BA_ "FlexKomIsMotorola" SG_ 523 ControlEncodingESL 1;
BA_ "FlexKomComment" SG_ 523 ControlEncodingESL "Code steering lock request packet";
BA_ "GenSigSNA" SG_ 523 ESLLockUnlockReq "0h";
BA_ "GenSigSendType" SG_ 523 ESLLockUnlockReq 1;
BA_ "FlexKomSigStartValue" SG_ 523 ESLLockUnlockReq "0000000000000000h";
BA_ "FlexKomSigStartPos" SG_ 523 ESLLockUnlockReq 7;
BA_ "FlexKomSigName" SG_ 523 ESLLockUnlockReq "Code_ESL_RqPkt";
BA_ "FlexKomSigLaenge" SG_ 523 ESLLockUnlockReq 64;
BA_ "FlexKomSID" SG_ 523 ESLLockUnlockReq 2345;
BA_ "FlexKomIsMotorola" SG_ 523 ESLLockUnlockReq 1;
BA_ "FlexKomComment" SG_ 523 ESLLockUnlockReq "Code steering lock request packet";
BA_ "GenSigSNA" SG_ 523 MiniCryptFCodeESL "0h";
BA_ "GenSigSendType" SG_ 523 MiniCryptFCodeESL 1;
BA_ "FlexKomSigStartValue" SG_ 523 MiniCryptFCodeESL "0000000000000000h";
BA_ "FlexKomSigStartPos" SG_ 523 MiniCryptFCodeESL 7;
BA_ "FlexKomSigName" SG_ 523 MiniCryptFCodeESL "Code_ESL_RqPkt";
BA_ "FlexKomSigLaenge" SG_ 523 MiniCryptFCodeESL 64;
BA_ "FlexKomSID" SG_ 523 MiniCryptFCodeESL 2345;
BA_ "FlexKomIsMotorola" SG_ 523 MiniCryptFCodeESL 1;
BA_ "FlexKomComment" SG_ 523 MiniCryptFCodeESL "Code steering lock request packet";
BA_ "GenSigSNA" SG_ 523 MiniCrypt_RndESL "0h";
BA_ "GenSigSendType" SG_ 523 MiniCrypt_RndESL 1;
BA_ "FlexKomSigStartValue" SG_ 523 MiniCrypt_RndESL "0000000000000000h";
BA_ "FlexKomSigStartPos" SG_ 523 MiniCrypt_RndESL 7;
BA_ "FlexKomSigName" SG_ 523 MiniCrypt_RndESL "Code_ESL_RqPkt";
BA_ "FlexKomSigLaenge" SG_ 523 MiniCrypt_RndESL 64;
BA_ "FlexKomSID" SG_ 523 MiniCrypt_RndESL 2345;
BA_ "FlexKomIsMotorola" SG_ 523 MiniCrypt_RndESL 1;
BA_ "FlexKomComment" SG_ 523 MiniCrypt_RndESL "Code steering lock request packet";
BA_ "GenSigSNA" SG_ 524 ControlEncodingBCM "0h";
BA_ "GenSigSendType" SG_ 524 ControlEncodingBCM 1;
BA_ "FlexKomSigStartValue" SG_ 524 ControlEncodingBCM "0000000000000000h";
BA_ "FlexKomSigStartPos" SG_ 524 ControlEncodingBCM 7;
BA_ "FlexKomSigName" SG_ 524 ControlEncodingBCM "Code_TRM_RqPkt";
BA_ "FlexKomSigLaenge" SG_ 524 ControlEncodingBCM 64;
BA_ "FlexKomSID" SG_ 524 ControlEncodingBCM 2331;
BA_ "FlexKomIsMotorola" SG_ 524 ControlEncodingBCM 1;
BA_ "FlexKomComment" SG_ 524 ControlEncodingBCM "Code transponder request packet";
BA_ "GenSigSNA" SG_ 524 MiniCryptFCode "0h";
BA_ "GenSigSendType" SG_ 524 MiniCryptFCode 1;
BA_ "FlexKomSigStartValue" SG_ 524 MiniCryptFCode "0000000000000000h";
BA_ "FlexKomSigStartPos" SG_ 524 MiniCryptFCode 7;
BA_ "FlexKomSigName" SG_ 524 MiniCryptFCode "Code_TRM_RqPkt";
BA_ "FlexKomSigLaenge" SG_ 524 MiniCryptFCode 64;
BA_ "FlexKomSID" SG_ 524 MiniCryptFCode 2331;
BA_ "FlexKomIsMotorola" SG_ 524 MiniCryptFCode 1;
BA_ "FlexKomComment" SG_ 524 MiniCryptFCode "Code transponder request packet";
BA_ "GenSigSNA" SG_ 524 MiniCrypt_Rnd "0h";
BA_ "GenSigSendType" SG_ 524 MiniCrypt_Rnd 1;
BA_ "FlexKomSigStartValue" SG_ 524 MiniCrypt_Rnd "0000000000000000h";
BA_ "FlexKomSigStartPos" SG_ 524 MiniCrypt_Rnd 7;
BA_ "FlexKomSigName" SG_ 524 MiniCrypt_Rnd "Code_TRM_RqPkt";
BA_ "FlexKomSigLaenge" SG_ 524 MiniCrypt_Rnd 64;
BA_ "FlexKomSID" SG_ 524 MiniCrypt_Rnd 2331;
BA_ "FlexKomIsMotorola" SG_ 524 MiniCrypt_Rnd 1;
BA_ "FlexKomComment" SG_ 524 MiniCrypt_Rnd "Code transponder request packet";
BA_ "GenSigSNA" SG_ 524 TxpAuthRequest "0h";
BA_ "GenSigSendType" SG_ 524 TxpAuthRequest 1;
BA_ "FlexKomSigStartValue" SG_ 524 TxpAuthRequest "0000000000000000h";
BA_ "FlexKomSigStartPos" SG_ 524 TxpAuthRequest 7;
BA_ "FlexKomSigName" SG_ 524 TxpAuthRequest "Code_TRM_RqPkt";
BA_ "FlexKomSigLaenge" SG_ 524 TxpAuthRequest 64;
BA_ "FlexKomSID" SG_ 524 TxpAuthRequest 2331;
BA_ "FlexKomIsMotorola" SG_ 524 TxpAuthRequest 1;
BA_ "FlexKomComment" SG_ 524 TxpAuthRequest "Code transponder request packet";
BA_ "GenSigSNA" SG_ 524 TxpReadRequest "0h";
BA_ "GenSigSendType" SG_ 524 TxpReadRequest 1;
BA_ "FlexKomSigStartValue" SG_ 524 TxpReadRequest "0000000000000000h";
BA_ "FlexKomSigStartPos" SG_ 524 TxpReadRequest 7;
BA_ "FlexKomSigName" SG_ 524 TxpReadRequest "Code_TRM_RqPkt";
BA_ "FlexKomSigLaenge" SG_ 524 TxpReadRequest 64;
BA_ "FlexKomSID" SG_ 524 TxpReadRequest 2331;
BA_ "FlexKomIsMotorola" SG_ 524 TxpReadRequest 1;
BA_ "FlexKomComment" SG_ 524 TxpReadRequest "Code transponder request packet";
BA_ "GenSigSNA" SG_ 525 MinicryptReceptionSts "0h";
BA_ "GenSigSendType" SG_ 525 MinicryptReceptionSts 1;
BA_ "FlexKomSigStartValue" SG_ 525 MinicryptReceptionSts "00h";
BA_ "FlexKomSigStartPos" SG_ 525 MinicryptReceptionSts 7;
BA_ "FlexKomSigName" SG_ 525 MinicryptReceptionSts "Minicrypt_AckPkt";
BA_ "FlexKomSigLaenge" SG_ 525 MinicryptReceptionSts 8;
BA_ "FlexKomSID" SG_ 525 MinicryptReceptionSts 2332;
BA_ "FlexKomIsMotorola" SG_ 525 MinicryptReceptionSts 1;
BA_ "FlexKomComment" SG_ 525 MinicryptReceptionSts "Minicrypt acknowledge packet";
BA_ "RID" SG_ 720 BSM_Blind_RQ "1158";
BA_ "GenSigTimeout_IC" SG_ 720 BSM_Blind_RQ 5250;
BA_ "GenSigSNA" SG_ 720 BSM_Blind_RQ "0h";
BA_ "GenSigSendType" SG_ 720 BSM_Blind_RQ 5;
BA_ "GenSigCycleTime" SG_ 720 BSM_Blind_RQ 500;
BA_ "FlexKomSigStartValue" SG_ 720 BSM_Blind_RQ "00h";
BA_ "FlexKomSigStartPos" SG_ 720 BSM_Blind_RQ 13;
BA_ "FlexKomSigName" SG_ 720 BSM_Blind_RQ "BSM_Blind_RQ";
BA_ "FlexKomSigLaenge" SG_ 720 BSM_Blind_RQ 1;
BA_ "FlexKomSID" SG_ 720 BSM_Blind_RQ 1362;
BA_ "FlexKomIsMotorola" SG_ 720 BSM_Blind_RQ 1;
BA_ "FlexKomComment" SG_ 720 BSM_Blind_RQ "Sensor blinded request from BSM; 1= sensor blocked";
BA_ "RID" SG_ 720 BSM_CFG_STAT "1248";
BA_ "GenSigTimeout_IC" SG_ 720 BSM_CFG_STAT 5250;
BA_ "GenSigStartValue" SG_ 720 BSM_CFG_STAT 3;
BA_ "GenSigSNA" SG_ 720 BSM_CFG_STAT "3h";
BA_ "GenSigSendType" SG_ 720 BSM_CFG_STAT 5;
BA_ "GenSigCycleTime" SG_ 720 BSM_CFG_STAT 500;
BA_ "FlexKomSigStartValue" SG_ 720 BSM_CFG_STAT "03h";
BA_ "FlexKomSigStartPos" SG_ 720 BSM_CFG_STAT 9;
BA_ "FlexKomSigName" SG_ 720 BSM_CFG_STAT "BSM_CFG_STAT";
BA_ "FlexKomSigLaenge" SG_ 720 BSM_CFG_STAT 2;
BA_ "FlexKomSID" SG_ 720 BSM_CFG_STAT 4;
BA_ "FlexKomIsMotorola" SG_ 720 BSM_CFG_STAT 1;
BA_ "FlexKomComment" SG_ 720 BSM_CFG_STAT "BSM configuration status";
BA_ "RID" SG_ 720 BSM_LT_WRN "1209";
BA_ "GenSigTimeout_IC" SG_ 720 BSM_LT_WRN 5250;
BA_ "GenSigSNA" SG_ 720 BSM_LT_WRN "7h";
BA_ "GenSigSendType" SG_ 720 BSM_LT_WRN 5;
BA_ "GenSigCycleTime" SG_ 720 BSM_LT_WRN 500;
BA_ "FlexKomSigStartValue" SG_ 720 BSM_LT_WRN "00h";
BA_ "FlexKomSigStartPos" SG_ 720 BSM_LT_WRN 5;
BA_ "FlexKomSigName" SG_ 720 BSM_LT_WRN "BSM_WRN";
BA_ "FlexKomSigLaenge" SG_ 720 BSM_LT_WRN 6;
BA_ "FlexKomSID" SG_ 720 BSM_LT_WRN 9;
BA_ "FlexKomIsMotorola" SG_ 720 BSM_LT_WRN 1;
BA_ "FlexKomComment" SG_ 720 BSM_LT_WRN "Blind spot detection warning status";
BA_ "RID" SG_ 720 BSM_OPR_STAT "1115";
BA_ "GenSigTimeout_IC" SG_ 720 BSM_OPR_STAT 5250;
BA_ "GenSigSNA" SG_ 720 BSM_OPR_STAT "0h";
BA_ "GenSigSendType" SG_ 720 BSM_OPR_STAT 5;
BA_ "GenSigCycleTime" SG_ 720 BSM_OPR_STAT 500;
BA_ "FlexKomSigStartValue" SG_ 720 BSM_OPR_STAT "00h";
BA_ "FlexKomSigStartPos" SG_ 720 BSM_OPR_STAT 11;
BA_ "FlexKomSigName" SG_ 720 BSM_OPR_STAT "BSM_OPR_STAT";
BA_ "FlexKomSigLaenge" SG_ 720 BSM_OPR_STAT 1;
BA_ "FlexKomSID" SG_ 720 BSM_OPR_STAT 7;
BA_ "FlexKomIsMotorola" SG_ 720 BSM_OPR_STAT 1;
BA_ "FlexKomComment" SG_ 720 BSM_OPR_STAT "BSM operation status; 1= operational failure";
BA_ "RID" SG_ 720 BSM_RT_WRN "1169";
BA_ "GenSigTimeout_IC" SG_ 720 BSM_RT_WRN 5250;
BA_ "GenSigSNA" SG_ 720 BSM_RT_WRN "7h";
BA_ "GenSigSendType" SG_ 720 BSM_RT_WRN 5;
BA_ "GenSigCycleTime" SG_ 720 BSM_RT_WRN 500;
BA_ "FlexKomSigStartValue" SG_ 720 BSM_RT_WRN "00h";
BA_ "FlexKomSigStartPos" SG_ 720 BSM_RT_WRN 5;
BA_ "FlexKomSigName" SG_ 720 BSM_RT_WRN "BSM_WRN";
BA_ "FlexKomSigLaenge" SG_ 720 BSM_RT_WRN 6;
BA_ "FlexKomSID" SG_ 720 BSM_RT_WRN 9;
BA_ "FlexKomIsMotorola" SG_ 720 BSM_RT_WRN 1;
BA_ "FlexKomComment" SG_ 720 BSM_RT_WRN "Blind spot detection warning status";
BA_ "RID" SG_ 720 BSM_SRV_RQ "1242";
BA_ "GenSigTimeout_IC" SG_ 720 BSM_SRV_RQ 5250;
BA_ "GenSigSNA" SG_ 720 BSM_SRV_RQ "0h";
BA_ "GenSigSendType" SG_ 720 BSM_SRV_RQ 5;
BA_ "GenSigCycleTime" SG_ 720 BSM_SRV_RQ 500;
BA_ "FlexKomSigStartValue" SG_ 720 BSM_SRV_RQ "00h";
BA_ "FlexKomSigStartPos" SG_ 720 BSM_SRV_RQ 10;
BA_ "FlexKomSigName" SG_ 720 BSM_SRV_RQ "BSM_SRV_RQ";
BA_ "FlexKomSigLaenge" SG_ 720 BSM_SRV_RQ 1;
BA_ "FlexKomSID" SG_ 720 BSM_SRV_RQ 6;
BA_ "FlexKomIsMotorola" SG_ 720 BSM_SRV_RQ 1;
BA_ "FlexKomComment" SG_ 720 BSM_SRV_RQ "BSM service warning request; 1= service request";
BA_ "GenSigStartValue" SG_ 998 BU_NET_CFG_STAT_INT 3;
BA_ "GenSigSNA" SG_ 998 BU_NET_CFG_STAT_INT "3h";
BA_ "GenSigSendType" SG_ 998 BU_NET_CFG_STAT_INT 1;
BA_ "FlexKomSigStartValue" SG_ 998 BU_NET_CFG_STAT_INT "0300000000000000h";
BA_ "FlexKomSigStartPos" SG_ 998 BU_NET_CFG_STAT_INT 7;
BA_ "FlexKomSigName" SG_ 998 BU_NET_CFG_STAT_INT "BU_NET_CFG_DATA_INT";
BA_ "FlexKomSigLaenge" SG_ 998 BU_NET_CFG_STAT_INT 64;
BA_ "FlexKomSID" SG_ 998 BU_NET_CFG_STAT_INT 871;
BA_ "FlexKomIsMotorola" SG_ 998 BU_NET_CFG_STAT_INT 1;
BA_ "FlexKomComment" SG_ 998 BU_NET_CFG_STAT_INT "Backup for network ECU config data for interior";
BA_ "GenSigSNA" SG_ 998 BU_NetCfg_AMP_I "0h";
BA_ "GenSigSendType" SG_ 998 BU_NetCfg_AMP_I 1;
BA_ "FlexKomSigStartValue" SG_ 998 BU_NetCfg_AMP_I "0300000000000000h";
BA_ "FlexKomSigStartPos" SG_ 998 BU_NetCfg_AMP_I 7;
BA_ "FlexKomSigName" SG_ 998 BU_NetCfg_AMP_I "BU_NET_CFG_DATA_INT";
BA_ "FlexKomSigLaenge" SG_ 998 BU_NetCfg_AMP_I 64;
BA_ "FlexKomSID" SG_ 998 BU_NetCfg_AMP_I 871;
BA_ "FlexKomIsMotorola" SG_ 998 BU_NetCfg_AMP_I 1;
BA_ "FlexKomComment" SG_ 998 BU_NetCfg_AMP_I "Backup for network ECU config data for interior";
BA_ "GenSigSNA" SG_ 998 BU_NetCfg_ANC_I "0h";
BA_ "GenSigSendType" SG_ 998 BU_NetCfg_ANC_I 1;
BA_ "FlexKomSigStartValue" SG_ 998 BU_NetCfg_ANC_I "0300000000000000h";
BA_ "FlexKomSigStartPos" SG_ 998 BU_NetCfg_ANC_I 7;
BA_ "FlexKomSigName" SG_ 998 BU_NetCfg_ANC_I "BU_NET_CFG_DATA_INT";
BA_ "FlexKomSigLaenge" SG_ 998 BU_NetCfg_ANC_I 64;
BA_ "FlexKomSID" SG_ 998 BU_NetCfg_ANC_I 871;
BA_ "FlexKomIsMotorola" SG_ 998 BU_NetCfg_ANC_I 1;
BA_ "FlexKomComment" SG_ 998 BU_NetCfg_ANC_I "Backup for network ECU config data for interior";
BA_ "GenSigSNA" SG_ 998 BU_NetCfg_BSM "0h";
BA_ "GenSigSendType" SG_ 998 BU_NetCfg_BSM 1;
BA_ "FlexKomSigStartValue" SG_ 998 BU_NetCfg_BSM "0300000000000000h";
BA_ "FlexKomSigStartPos" SG_ 998 BU_NetCfg_BSM 7;
BA_ "FlexKomSigName" SG_ 998 BU_NetCfg_BSM "BU_NET_CFG_DATA_INT";
BA_ "FlexKomSigLaenge" SG_ 998 BU_NetCfg_BSM 64;
BA_ "FlexKomSID" SG_ 998 BU_NetCfg_BSM 871;
BA_ "FlexKomIsMotorola" SG_ 998 BU_NetCfg_BSM 1;
BA_ "FlexKomComment" SG_ 998 BU_NetCfg_BSM "Backup for network ECU config data for interior";
BA_ "GenSigSNA" SG_ 998 BU_NetCfg_CBC_IN "0h";
BA_ "GenSigSendType" SG_ 998 BU_NetCfg_CBC_IN 1;
BA_ "FlexKomSigStartValue" SG_ 998 BU_NetCfg_CBC_IN "0300000000000000h";
BA_ "FlexKomSigStartPos" SG_ 998 BU_NetCfg_CBC_IN 7;
BA_ "FlexKomSigName" SG_ 998 BU_NetCfg_CBC_IN "BU_NET_CFG_DATA_INT";
BA_ "FlexKomSigLaenge" SG_ 998 BU_NetCfg_CBC_IN 64;
BA_ "FlexKomSID" SG_ 998 BU_NetCfg_CBC_IN 871;
BA_ "FlexKomIsMotorola" SG_ 998 BU_NetCfg_CBC_IN 1;
BA_ "FlexKomComment" SG_ 998 BU_NetCfg_CBC_IN "Backup for network ECU config data for interior";
BA_ "GenSigSNA" SG_ 998 BU_NetCfg_CLOCK "0h";
BA_ "GenSigSendType" SG_ 998 BU_NetCfg_CLOCK 1;
BA_ "FlexKomSigStartValue" SG_ 998 BU_NetCfg_CLOCK "0300000000000000h";
BA_ "FlexKomSigStartPos" SG_ 998 BU_NetCfg_CLOCK 7;
BA_ "FlexKomSigName" SG_ 998 BU_NetCfg_CLOCK "BU_NET_CFG_DATA_INT";
BA_ "FlexKomSigLaenge" SG_ 998 BU_NetCfg_CLOCK 64;
BA_ "FlexKomSID" SG_ 998 BU_NetCfg_CLOCK 871;
BA_ "FlexKomIsMotorola" SG_ 998 BU_NetCfg_CLOCK 1;
BA_ "FlexKomComment" SG_ 998 BU_NetCfg_CLOCK "Backup for network ECU config data for interior";
BA_ "GenSigSNA" SG_ 998 BU_NetCfg_CRSM "0h";
BA_ "GenSigSendType" SG_ 998 BU_NetCfg_CRSM 1;
BA_ "FlexKomSigStartValue" SG_ 998 BU_NetCfg_CRSM "0300000000000000h";
BA_ "FlexKomSigStartPos" SG_ 998 BU_NetCfg_CRSM 7;
BA_ "FlexKomSigName" SG_ 998 BU_NetCfg_CRSM "BU_NET_CFG_DATA_INT";
BA_ "FlexKomSigLaenge" SG_ 998 BU_NetCfg_CRSM 64;
BA_ "FlexKomSID" SG_ 998 BU_NetCfg_CRSM 871;
BA_ "FlexKomIsMotorola" SG_ 998 BU_NetCfg_CRSM 1;
BA_ "FlexKomComment" SG_ 998 BU_NetCfg_CRSM "Backup for network ECU config data for interior";
BA_ "GenSigSNA" SG_ 998 BU_NetCfg_CSWM "0h";
BA_ "GenSigSendType" SG_ 998 BU_NetCfg_CSWM 1;
BA_ "FlexKomSigStartValue" SG_ 998 BU_NetCfg_CSWM "0300000000000000h";
BA_ "FlexKomSigStartPos" SG_ 998 BU_NetCfg_CSWM 7;
BA_ "FlexKomSigName" SG_ 998 BU_NetCfg_CSWM "BU_NET_CFG_DATA_INT";
BA_ "FlexKomSigLaenge" SG_ 998 BU_NetCfg_CSWM 64;
BA_ "FlexKomSID" SG_ 998 BU_NetCfg_CSWM 871;
BA_ "FlexKomIsMotorola" SG_ 998 BU_NetCfg_CSWM 1;
BA_ "FlexKomComment" SG_ 998 BU_NetCfg_CSWM "Backup for network ECU config data for interior";
BA_ "GenSigSNA" SG_ 998 BU_NetCfg_CVPM "0h";
BA_ "GenSigSendType" SG_ 998 BU_NetCfg_CVPM 1;
BA_ "FlexKomSigStartValue" SG_ 998 BU_NetCfg_CVPM "0300000000000000h";
BA_ "FlexKomSigStartPos" SG_ 998 BU_NetCfg_CVPM 7;
BA_ "FlexKomSigName" SG_ 998 BU_NetCfg_CVPM "BU_NET_CFG_DATA_INT";
BA_ "FlexKomSigLaenge" SG_ 998 BU_NetCfg_CVPM 64;
BA_ "FlexKomSID" SG_ 998 BU_NetCfg_CVPM 871;
BA_ "FlexKomIsMotorola" SG_ 998 BU_NetCfg_CVPM 1;
BA_ "FlexKomComment" SG_ 998 BU_NetCfg_CVPM "Backup for network ECU config data for interior";
BA_ "GenSigSNA" SG_ 998 BU_NetCfg_DCM_DR "0h";
BA_ "GenSigSendType" SG_ 998 BU_NetCfg_DCM_DR 1;
BA_ "FlexKomSigStartValue" SG_ 998 BU_NetCfg_DCM_DR "0300000000000000h";
BA_ "FlexKomSigStartPos" SG_ 998 BU_NetCfg_DCM_DR 7;
BA_ "FlexKomSigName" SG_ 998 BU_NetCfg_DCM_DR "BU_NET_CFG_DATA_INT";
BA_ "FlexKomSigLaenge" SG_ 998 BU_NetCfg_DCM_DR 64;
BA_ "FlexKomSID" SG_ 998 BU_NetCfg_DCM_DR 871;
BA_ "FlexKomIsMotorola" SG_ 998 BU_NetCfg_DCM_DR 1;
BA_ "FlexKomComment" SG_ 998 BU_NetCfg_DCM_DR "Backup for network ECU config data for interior";
BA_ "GenSigSNA" SG_ 998 BU_NetCfg_DCM_PASS "0h";
BA_ "GenSigSendType" SG_ 998 BU_NetCfg_DCM_PASS 1;
BA_ "FlexKomSigStartValue" SG_ 998 BU_NetCfg_DCM_PASS "0300000000000000h";
BA_ "FlexKomSigStartPos" SG_ 998 BU_NetCfg_DCM_PASS 7;
BA_ "FlexKomSigName" SG_ 998 BU_NetCfg_DCM_PASS "BU_NET_CFG_DATA_INT";
BA_ "FlexKomSigLaenge" SG_ 998 BU_NetCfg_DCM_PASS 64;
BA_ "FlexKomSID" SG_ 998 BU_NetCfg_DCM_PASS 871;
BA_ "FlexKomIsMotorola" SG_ 998 BU_NetCfg_DCM_PASS 1;
BA_ "FlexKomComment" SG_ 998 BU_NetCfg_DCM_PASS "Backup for network ECU config data for interior";
BA_ "GenSigSNA" SG_ 998 BU_NetCfg_DCM_RL "0h";
BA_ "GenSigSendType" SG_ 998 BU_NetCfg_DCM_RL 1;
BA_ "FlexKomSigStartValue" SG_ 998 BU_NetCfg_DCM_RL "0300000000000000h";
BA_ "FlexKomSigStartPos" SG_ 998 BU_NetCfg_DCM_RL 7;
BA_ "FlexKomSigName" SG_ 998 BU_NetCfg_DCM_RL "BU_NET_CFG_DATA_INT";
BA_ "FlexKomSigLaenge" SG_ 998 BU_NetCfg_DCM_RL 64;
BA_ "FlexKomSID" SG_ 998 BU_NetCfg_DCM_RL 871;
BA_ "FlexKomIsMotorola" SG_ 998 BU_NetCfg_DCM_RL 1;
BA_ "FlexKomComment" SG_ 998 BU_NetCfg_DCM_RL "Backup for network ECU config data for interior";
BA_ "GenSigSNA" SG_ 998 BU_NetCfg_DCM_RR "0h";
BA_ "GenSigSendType" SG_ 998 BU_NetCfg_DCM_RR 1;
BA_ "FlexKomSigStartValue" SG_ 998 BU_NetCfg_DCM_RR "0300000000000000h";
BA_ "FlexKomSigStartPos" SG_ 998 BU_NetCfg_DCM_RR 7;
BA_ "FlexKomSigName" SG_ 998 BU_NetCfg_DCM_RR "BU_NET_CFG_DATA_INT";
BA_ "FlexKomSigLaenge" SG_ 998 BU_NetCfg_DCM_RR 64;
BA_ "FlexKomSID" SG_ 998 BU_NetCfg_DCM_RR 871;
BA_ "FlexKomIsMotorola" SG_ 998 BU_NetCfg_DCM_RR 1;
BA_ "FlexKomComment" SG_ 998 BU_NetCfg_DCM_RR "Backup for network ECU config data for interior";
BA_ "GenSigSNA" SG_ 998 BU_NetCfg_DCSD "0h";
BA_ "GenSigSendType" SG_ 998 BU_NetCfg_DCSD 1;
BA_ "FlexKomSigStartValue" SG_ 998 BU_NetCfg_DCSD "0300000000000000h";
BA_ "FlexKomSigStartPos" SG_ 998 BU_NetCfg_DCSD 7;
BA_ "FlexKomSigName" SG_ 998 BU_NetCfg_DCSD "BU_NET_CFG_DATA_INT";
BA_ "FlexKomSigLaenge" SG_ 998 BU_NetCfg_DCSD 64;
BA_ "FlexKomSID" SG_ 998 BU_NetCfg_DCSD 871;
BA_ "FlexKomIsMotorola" SG_ 998 BU_NetCfg_DCSD 1;
BA_ "FlexKomComment" SG_ 998 BU_NetCfg_DCSD "Backup for network ECU config data for interior";
BA_ "GenSigSNA" SG_ 998 BU_NetCfg_DTV "0h";
BA_ "GenSigSendType" SG_ 998 BU_NetCfg_DTV 1;
BA_ "FlexKomSigStartValue" SG_ 998 BU_NetCfg_DTV "0300000000000000h";
BA_ "FlexKomSigStartPos" SG_ 998 BU_NetCfg_DTV 7;
BA_ "FlexKomSigName" SG_ 998 BU_NetCfg_DTV "BU_NET_CFG_DATA_INT";
BA_ "FlexKomSigLaenge" SG_ 998 BU_NetCfg_DTV 64;
BA_ "FlexKomSID" SG_ 998 BU_NetCfg_DTV 871;
BA_ "FlexKomIsMotorola" SG_ 998 BU_NetCfg_DTV 1;
BA_ "FlexKomComment" SG_ 998 BU_NetCfg_DTV "Backup for network ECU config data for interior";
BA_ "GenSigSNA" SG_ 998 BU_NetCfg_DVD_CDM "0h";
BA_ "GenSigSendType" SG_ 998 BU_NetCfg_DVD_CDM 1;
BA_ "FlexKomSigStartValue" SG_ 998 BU_NetCfg_DVD_CDM "0300000000000000h";
BA_ "FlexKomSigStartPos" SG_ 998 BU_NetCfg_DVD_CDM 7;
BA_ "FlexKomSigName" SG_ 998 BU_NetCfg_DVD_CDM "BU_NET_CFG_DATA_INT";
BA_ "FlexKomSigLaenge" SG_ 998 BU_NetCfg_DVD_CDM 64;
BA_ "FlexKomSID" SG_ 998 BU_NetCfg_DVD_CDM 871;
BA_ "FlexKomIsMotorola" SG_ 998 BU_NetCfg_DVD_CDM 1;
BA_ "FlexKomComment" SG_ 998 BU_NetCfg_DVD_CDM "Backup for network ECU config data for interior";
BA_ "GenSigSNA" SG_ 998 BU_NetCfg_FSM "0h";
BA_ "GenSigSendType" SG_ 998 BU_NetCfg_FSM 1;
BA_ "FlexKomSigStartValue" SG_ 998 BU_NetCfg_FSM "0300000000000000h";
BA_ "FlexKomSigStartPos" SG_ 998 BU_NetCfg_FSM 7;
BA_ "FlexKomSigName" SG_ 998 BU_NetCfg_FSM "BU_NET_CFG_DATA_INT";
BA_ "FlexKomSigLaenge" SG_ 998 BU_NetCfg_FSM 64;
BA_ "FlexKomSID" SG_ 998 BU_NetCfg_FSM 871;
BA_ "FlexKomIsMotorola" SG_ 998 BU_NetCfg_FSM 1;
BA_ "FlexKomComment" SG_ 998 BU_NetCfg_FSM "Backup for network ECU config data for interior";
BA_ "GenSigSNA" SG_ 998 BU_NetCfg_HFM_CTM "0h";
BA_ "GenSigSendType" SG_ 998 BU_NetCfg_HFM_CTM 1;
BA_ "FlexKomSigStartValue" SG_ 998 BU_NetCfg_HFM_CTM "0300000000000000h";
BA_ "FlexKomSigStartPos" SG_ 998 BU_NetCfg_HFM_CTM 7;
BA_ "FlexKomSigName" SG_ 998 BU_NetCfg_HFM_CTM "BU_NET_CFG_DATA_INT";
BA_ "FlexKomSigLaenge" SG_ 998 BU_NetCfg_HFM_CTM 64;
BA_ "FlexKomSID" SG_ 998 BU_NetCfg_HFM_CTM 871;
BA_ "FlexKomIsMotorola" SG_ 998 BU_NetCfg_HFM_CTM 1;
BA_ "FlexKomComment" SG_ 998 BU_NetCfg_HFM_CTM "Backup for network ECU config data for interior";
BA_ "GenSigSNA" SG_ 998 BU_NetCfg_HVAC "0h";
BA_ "GenSigSendType" SG_ 998 BU_NetCfg_HVAC 1;
BA_ "FlexKomSigStartValue" SG_ 998 BU_NetCfg_HVAC "0300000000000000h";
BA_ "FlexKomSigStartPos" SG_ 998 BU_NetCfg_HVAC 7;
BA_ "FlexKomSigName" SG_ 998 BU_NetCfg_HVAC "BU_NET_CFG_DATA_INT";
BA_ "FlexKomSigLaenge" SG_ 998 BU_NetCfg_HVAC 64;
BA_ "FlexKomSID" SG_ 998 BU_NetCfg_HVAC 871;
BA_ "FlexKomIsMotorola" SG_ 998 BU_NetCfg_HVAC 1;
BA_ "FlexKomComment" SG_ 998 BU_NetCfg_HVAC "Backup for network ECU config data for interior";
BA_ "GenSigSNA" SG_ 998 BU_NetCfg_HVAC_R "0h";
BA_ "GenSigSendType" SG_ 998 BU_NetCfg_HVAC_R 1;
BA_ "FlexKomSigStartValue" SG_ 998 BU_NetCfg_HVAC_R "0300000000000000h";
BA_ "FlexKomSigStartPos" SG_ 998 BU_NetCfg_HVAC_R 7;
BA_ "FlexKomSigName" SG_ 998 BU_NetCfg_HVAC_R "BU_NET_CFG_DATA_INT";
BA_ "FlexKomSigLaenge" SG_ 998 BU_NetCfg_HVAC_R 64;
BA_ "FlexKomSID" SG_ 998 BU_NetCfg_HVAC_R 871;
BA_ "FlexKomIsMotorola" SG_ 998 BU_NetCfg_HVAC_R 1;
BA_ "FlexKomComment" SG_ 998 BU_NetCfg_HVAC_R "Backup for network ECU config data for interior";
BA_ "GenSigSNA" SG_ 998 BU_NetCfg_ICS_I "0h";
BA_ "GenSigSendType" SG_ 998 BU_NetCfg_ICS_I 1;
BA_ "FlexKomSigStartValue" SG_ 998 BU_NetCfg_ICS_I "0300000000000000h";
BA_ "FlexKomSigStartPos" SG_ 998 BU_NetCfg_ICS_I 7;
BA_ "FlexKomSigName" SG_ 998 BU_NetCfg_ICS_I "BU_NET_CFG_DATA_INT";
BA_ "FlexKomSigLaenge" SG_ 998 BU_NetCfg_ICS_I 64;
BA_ "FlexKomSID" SG_ 998 BU_NetCfg_ICS_I 871;
BA_ "FlexKomIsMotorola" SG_ 998 BU_NetCfg_ICS_I 1;
BA_ "FlexKomComment" SG_ 998 BU_NetCfg_ICS_I "Backup for network ECU config data for interior";
BA_ "GenSigSNA" SG_ 998 BU_NetCfg_ICS_R "0h";
BA_ "GenSigSendType" SG_ 998 BU_NetCfg_ICS_R 1;
BA_ "FlexKomSigStartValue" SG_ 998 BU_NetCfg_ICS_R "0300000000000000h";
BA_ "FlexKomSigStartPos" SG_ 998 BU_NetCfg_ICS_R 7;
BA_ "FlexKomSigName" SG_ 998 BU_NetCfg_ICS_R "BU_NET_CFG_DATA_INT";
BA_ "FlexKomSigLaenge" SG_ 998 BU_NetCfg_ICS_R 64;
BA_ "FlexKomSID" SG_ 998 BU_NetCfg_ICS_R 871;
BA_ "FlexKomIsMotorola" SG_ 998 BU_NetCfg_ICS_R 1;
BA_ "FlexKomComment" SG_ 998 BU_NetCfg_ICS_R "Backup for network ECU config data for interior";
BA_ "GenSigSNA" SG_ 998 BU_NetCfg_ITM "0h";
BA_ "GenSigSendType" SG_ 998 BU_NetCfg_ITM 1;
BA_ "FlexKomSigStartValue" SG_ 998 BU_NetCfg_ITM "0300000000000000h";
BA_ "FlexKomSigStartPos" SG_ 998 BU_NetCfg_ITM 7;
BA_ "FlexKomSigName" SG_ 998 BU_NetCfg_ITM "BU_NET_CFG_DATA_INT";
BA_ "FlexKomSigLaenge" SG_ 998 BU_NetCfg_ITM 64;
BA_ "FlexKomSID" SG_ 998 BU_NetCfg_ITM 871;
BA_ "FlexKomIsMotorola" SG_ 998 BU_NetCfg_ITM 1;
BA_ "FlexKomComment" SG_ 998 BU_NetCfg_ITM "Backup for network ECU config data for interior";
BA_ "GenSigSNA" SG_ 998 BU_NetCfg_MSM "0h";
BA_ "GenSigSendType" SG_ 998 BU_NetCfg_MSM 1;
BA_ "FlexKomSigStartValue" SG_ 998 BU_NetCfg_MSM "0300000000000000h";
BA_ "FlexKomSigStartPos" SG_ 998 BU_NetCfg_MSM 7;
BA_ "FlexKomSigName" SG_ 998 BU_NetCfg_MSM "BU_NET_CFG_DATA_INT";
BA_ "FlexKomSigLaenge" SG_ 998 BU_NetCfg_MSM 64;
BA_ "FlexKomSID" SG_ 998 BU_NetCfg_MSM 871;
BA_ "FlexKomIsMotorola" SG_ 998 BU_NetCfg_MSM 1;
BA_ "FlexKomComment" SG_ 998 BU_NetCfg_MSM "Backup for network ECU config data for interior";
BA_ "GenSigSNA" SG_ 998 BU_NetCfg_MSM_PASS "0h";
BA_ "GenSigSendType" SG_ 998 BU_NetCfg_MSM_PASS 1;
BA_ "FlexKomSigStartValue" SG_ 998 BU_NetCfg_MSM_PASS "0300000000000000h";
BA_ "FlexKomSigStartPos" SG_ 998 BU_NetCfg_MSM_PASS 7;
BA_ "FlexKomSigName" SG_ 998 BU_NetCfg_MSM_PASS "BU_NET_CFG_DATA_INT";
BA_ "FlexKomSigLaenge" SG_ 998 BU_NetCfg_MSM_PASS 64;
BA_ "FlexKomSID" SG_ 998 BU_NetCfg_MSM_PASS 871;
BA_ "FlexKomIsMotorola" SG_ 998 BU_NetCfg_MSM_PASS 1;
BA_ "FlexKomComment" SG_ 998 BU_NetCfg_MSM_PASS "Backup for network ECU config data for interior";
BA_ "GenSigSNA" SG_ 998 BU_NetCfg_PLG "0h";
BA_ "GenSigSendType" SG_ 998 BU_NetCfg_PLG 1;
BA_ "FlexKomSigStartValue" SG_ 998 BU_NetCfg_PLG "0300000000000000h";
BA_ "FlexKomSigStartPos" SG_ 998 BU_NetCfg_PLG 7;
BA_ "FlexKomSigName" SG_ 998 BU_NetCfg_PLG "BU_NET_CFG_DATA_INT";
BA_ "FlexKomSigLaenge" SG_ 998 BU_NetCfg_PLG 64;
BA_ "FlexKomSID" SG_ 998 BU_NetCfg_PLG 871;
BA_ "FlexKomIsMotorola" SG_ 998 BU_NetCfg_PLG 1;
BA_ "FlexKomComment" SG_ 998 BU_NetCfg_PLG "Backup for network ECU config data for interior";
BA_ "GenSigSNA" SG_ 998 BU_NetCfg_PSD_LT "0h";
BA_ "GenSigSendType" SG_ 998 BU_NetCfg_PSD_LT 1;
BA_ "FlexKomSigStartValue" SG_ 998 BU_NetCfg_PSD_LT "0300000000000000h";
BA_ "FlexKomSigStartPos" SG_ 998 BU_NetCfg_PSD_LT 7;
BA_ "FlexKomSigName" SG_ 998 BU_NetCfg_PSD_LT "BU_NET_CFG_DATA_INT";
BA_ "FlexKomSigLaenge" SG_ 998 BU_NetCfg_PSD_LT 64;
BA_ "FlexKomSID" SG_ 998 BU_NetCfg_PSD_LT 871;
BA_ "FlexKomIsMotorola" SG_ 998 BU_NetCfg_PSD_LT 1;
BA_ "FlexKomComment" SG_ 998 BU_NetCfg_PSD_LT "Backup for network ECU config data for interior";
BA_ "GenSigSNA" SG_ 998 BU_NetCfg_PSD_RT "0h";
BA_ "GenSigSendType" SG_ 998 BU_NetCfg_PSD_RT 1;
BA_ "FlexKomSigStartValue" SG_ 998 BU_NetCfg_PSD_RT "0300000000000000h";
BA_ "FlexKomSigStartPos" SG_ 998 BU_NetCfg_PSD_RT 7;
BA_ "FlexKomSigName" SG_ 998 BU_NetCfg_PSD_RT "BU_NET_CFG_DATA_INT";
BA_ "FlexKomSigLaenge" SG_ 998 BU_NetCfg_PSD_RT 64;
BA_ "FlexKomSID" SG_ 998 BU_NetCfg_PSD_RT 871;
BA_ "FlexKomIsMotorola" SG_ 998 BU_NetCfg_PSD_RT 1;
BA_ "FlexKomComment" SG_ 998 BU_NetCfg_PSD_RT "Backup for network ECU config data for interior";
BA_ "GenSigSNA" SG_ 998 BU_NetCfg_PSSM "0h";
BA_ "GenSigSendType" SG_ 998 BU_NetCfg_PSSM 1;
BA_ "FlexKomSigStartValue" SG_ 998 BU_NetCfg_PSSM "0300000000000000h";
BA_ "FlexKomSigStartPos" SG_ 998 BU_NetCfg_PSSM 7;
BA_ "FlexKomSigName" SG_ 998 BU_NetCfg_PSSM "BU_NET_CFG_DATA_INT";
BA_ "FlexKomSigLaenge" SG_ 998 BU_NetCfg_PSSM 64;
BA_ "FlexKomSID" SG_ 998 BU_NetCfg_PSSM 871;
BA_ "FlexKomIsMotorola" SG_ 998 BU_NetCfg_PSSM 1;
BA_ "FlexKomComment" SG_ 998 BU_NetCfg_PSSM "Backup for network ECU config data for interior";
BA_ "GenSigSNA" SG_ 998 BU_NetCfg_PTCM "0h";
BA_ "GenSigSendType" SG_ 998 BU_NetCfg_PTCM 1;
BA_ "FlexKomSigStartValue" SG_ 998 BU_NetCfg_PTCM "0300000000000000h";
BA_ "FlexKomSigStartPos" SG_ 998 BU_NetCfg_PTCM 7;
BA_ "FlexKomSigName" SG_ 998 BU_NetCfg_PTCM "BU_NET_CFG_DATA_INT";
BA_ "FlexKomSigLaenge" SG_ 998 BU_NetCfg_PTCM 64;
BA_ "FlexKomSID" SG_ 998 BU_NetCfg_PTCM 871;
BA_ "FlexKomIsMotorola" SG_ 998 BU_NetCfg_PTCM 1;
BA_ "FlexKomComment" SG_ 998 BU_NetCfg_PTCM "Backup for network ECU config data for interior";
BA_ "GenSigSNA" SG_ 998 BU_NetCfg_RBC "0h";
BA_ "GenSigSendType" SG_ 998 BU_NetCfg_RBC 1;
BA_ "FlexKomSigStartValue" SG_ 998 BU_NetCfg_RBC "0300000000000000h";
BA_ "FlexKomSigStartPos" SG_ 998 BU_NetCfg_RBC 7;
BA_ "FlexKomSigName" SG_ 998 BU_NetCfg_RBC "BU_NET_CFG_DATA_INT";
BA_ "FlexKomSigLaenge" SG_ 998 BU_NetCfg_RBC 64;
BA_ "FlexKomSID" SG_ 998 BU_NetCfg_RBC 871;
BA_ "FlexKomIsMotorola" SG_ 998 BU_NetCfg_RBC 1;
BA_ "FlexKomComment" SG_ 998 BU_NetCfg_RBC "Backup for network ECU config data for interior";
BA_ "GenSigSNA" SG_ 998 BU_NetCfg_RBSS "0h";
BA_ "GenSigSendType" SG_ 998 BU_NetCfg_RBSS 1;
BA_ "FlexKomSigStartValue" SG_ 998 BU_NetCfg_RBSS "0300000000000000h";
BA_ "FlexKomSigStartPos" SG_ 998 BU_NetCfg_RBSS 7;
BA_ "FlexKomSigName" SG_ 998 BU_NetCfg_RBSS "BU_NET_CFG_DATA_INT";
BA_ "FlexKomSigLaenge" SG_ 998 BU_NetCfg_RBSS 64;
BA_ "FlexKomSID" SG_ 998 BU_NetCfg_RBSS 871;
BA_ "FlexKomIsMotorola" SG_ 998 BU_NetCfg_RBSS 1;
BA_ "FlexKomComment" SG_ 998 BU_NetCfg_RBSS "Backup for network ECU config data for interior";
BA_ "GenSigSNA" SG_ 998 BU_NetCfg_TBM "0h";
BA_ "GenSigSendType" SG_ 998 BU_NetCfg_TBM 1;
BA_ "FlexKomSigStartValue" SG_ 998 BU_NetCfg_TBM "0300000000000000h";
BA_ "FlexKomSigStartPos" SG_ 998 BU_NetCfg_TBM 7;
BA_ "FlexKomSigName" SG_ 998 BU_NetCfg_TBM "BU_NET_CFG_DATA_INT";
BA_ "FlexKomSigLaenge" SG_ 998 BU_NetCfg_TBM 64;
BA_ "FlexKomSID" SG_ 998 BU_NetCfg_TBM 871;
BA_ "FlexKomIsMotorola" SG_ 998 BU_NetCfg_TBM 1;
BA_ "FlexKomComment" SG_ 998 BU_NetCfg_TBM "Backup for network ECU config data for interior";
BA_ "GenSigSNA" SG_ 998 BU_NetCfg_TGW "0h";
BA_ "GenSigSendType" SG_ 998 BU_NetCfg_TGW 1;
BA_ "FlexKomSigStartValue" SG_ 998 BU_NetCfg_TGW "0300000000000000h";
BA_ "FlexKomSigStartPos" SG_ 998 BU_NetCfg_TGW 7;
BA_ "FlexKomSigName" SG_ 998 BU_NetCfg_TGW "BU_NET_CFG_DATA_INT";
BA_ "FlexKomSigLaenge" SG_ 998 BU_NetCfg_TGW 64;
BA_ "FlexKomSID" SG_ 998 BU_NetCfg_TGW 871;
BA_ "FlexKomIsMotorola" SG_ 998 BU_NetCfg_TGW 1;
BA_ "FlexKomComment" SG_ 998 BU_NetCfg_TGW "Backup for network ECU config data for interior";
BA_ "GenSigSNA" SG_ 998 BU_NetCfg_TMM "0h";
BA_ "GenSigSendType" SG_ 998 BU_NetCfg_TMM 1;
BA_ "FlexKomSigStartValue" SG_ 998 BU_NetCfg_TMM "0300000000000000h";
BA_ "FlexKomSigStartPos" SG_ 998 BU_NetCfg_TMM 7;
BA_ "FlexKomSigName" SG_ 998 BU_NetCfg_TMM "BU_NET_CFG_DATA_INT";
BA_ "FlexKomSigLaenge" SG_ 998 BU_NetCfg_TMM 64;
BA_ "FlexKomSID" SG_ 998 BU_NetCfg_TMM 871;
BA_ "FlexKomIsMotorola" SG_ 998 BU_NetCfg_TMM 1;
BA_ "FlexKomComment" SG_ 998 BU_NetCfg_TMM "Backup for network ECU config data for interior";
BA_ "GenSigSNA" SG_ 998 BU_NetCfg_TTM "0h";
BA_ "GenSigSendType" SG_ 998 BU_NetCfg_TTM 1;
BA_ "FlexKomSigStartValue" SG_ 998 BU_NetCfg_TTM "0300000000000000h";
BA_ "FlexKomSigStartPos" SG_ 998 BU_NetCfg_TTM 7;
BA_ "FlexKomSigName" SG_ 998 BU_NetCfg_TTM "BU_NET_CFG_DATA_INT";
BA_ "FlexKomSigLaenge" SG_ 998 BU_NetCfg_TTM 64;
BA_ "FlexKomSID" SG_ 998 BU_NetCfg_TTM 871;
BA_ "FlexKomIsMotorola" SG_ 998 BU_NetCfg_TTM 1;
BA_ "FlexKomComment" SG_ 998 BU_NetCfg_TTM "Backup for network ECU config data for interior";
BA_ "GenSigSNA" SG_ 998 BU_NetCfg_UPFM "0h";
BA_ "GenSigSendType" SG_ 998 BU_NetCfg_UPFM 1;
BA_ "FlexKomSigStartValue" SG_ 998 BU_NetCfg_UPFM "0300000000000000h";
BA_ "FlexKomSigStartPos" SG_ 998 BU_NetCfg_UPFM 7;
BA_ "FlexKomSigName" SG_ 998 BU_NetCfg_UPFM "BU_NET_CFG_DATA_INT";
BA_ "FlexKomSigLaenge" SG_ 998 BU_NetCfg_UPFM 64;
BA_ "FlexKomSID" SG_ 998 BU_NetCfg_UPFM 871;
BA_ "FlexKomIsMotorola" SG_ 998 BU_NetCfg_UPFM 1;
BA_ "FlexKomComment" SG_ 998 BU_NetCfg_UPFM "Backup for network ECU config data for interior";
BA_ "GenSigSNA" SG_ 998 BU_NetCfg_VES2_I "0h";
BA_ "GenSigSendType" SG_ 998 BU_NetCfg_VES2_I 1;
BA_ "FlexKomSigStartValue" SG_ 998 BU_NetCfg_VES2_I "0300000000000000h";
BA_ "FlexKomSigStartPos" SG_ 998 BU_NetCfg_VES2_I 7;
BA_ "FlexKomSigName" SG_ 998 BU_NetCfg_VES2_I "BU_NET_CFG_DATA_INT";
BA_ "FlexKomSigLaenge" SG_ 998 BU_NetCfg_VES2_I 64;
BA_ "FlexKomSID" SG_ 998 BU_NetCfg_VES2_I 871;
BA_ "FlexKomIsMotorola" SG_ 998 BU_NetCfg_VES2_I 1;
BA_ "FlexKomComment" SG_ 998 BU_NetCfg_VES2_I "Backup for network ECU config data for interior";
BA_ "GenSigSNA" SG_ 998 BU_NetCfg_VES3_I "0h";
BA_ "GenSigSendType" SG_ 998 BU_NetCfg_VES3_I 1;
BA_ "FlexKomSigStartValue" SG_ 998 BU_NetCfg_VES3_I "0300000000000000h";
BA_ "FlexKomSigStartPos" SG_ 998 BU_NetCfg_VES3_I 7;
BA_ "FlexKomSigName" SG_ 998 BU_NetCfg_VES3_I "BU_NET_CFG_DATA_INT";
BA_ "FlexKomSigLaenge" SG_ 998 BU_NetCfg_VES3_I 64;
BA_ "FlexKomSID" SG_ 998 BU_NetCfg_VES3_I 871;
BA_ "FlexKomIsMotorola" SG_ 998 BU_NetCfg_VES3_I 1;
BA_ "FlexKomComment" SG_ 998 BU_NetCfg_VES3_I "Backup for network ECU config data for interior";
BA_ "GenSigSNA" SG_ 998 BU_NetCfg_VRM "0h";
BA_ "GenSigSendType" SG_ 998 BU_NetCfg_VRM 1;
BA_ "FlexKomSigStartValue" SG_ 998 BU_NetCfg_VRM "0300000000000000h";
BA_ "FlexKomSigStartPos" SG_ 998 BU_NetCfg_VRM 7;
BA_ "FlexKomSigName" SG_ 998 BU_NetCfg_VRM "BU_NET_CFG_DATA_INT";
BA_ "FlexKomSigLaenge" SG_ 998 BU_NetCfg_VRM 64;
BA_ "FlexKomSID" SG_ 998 BU_NetCfg_VRM 871;
BA_ "FlexKomIsMotorola" SG_ 998 BU_NetCfg_VRM 1;
BA_ "FlexKomComment" SG_ 998 BU_NetCfg_VRM "Backup for network ECU config data for interior";
BA_ "GenSigSNA" SG_ 998 BU_NetCfg_VSIM "0h";
BA_ "GenSigSendType" SG_ 998 BU_NetCfg_VSIM 1;
BA_ "FlexKomSigStartValue" SG_ 998 BU_NetCfg_VSIM "0300000000000000h";
BA_ "FlexKomSigStartPos" SG_ 998 BU_NetCfg_VSIM 7;
BA_ "FlexKomSigName" SG_ 998 BU_NetCfg_VSIM "BU_NET_CFG_DATA_INT";
BA_ "FlexKomSigLaenge" SG_ 998 BU_NetCfg_VSIM 64;
BA_ "FlexKomSID" SG_ 998 BU_NetCfg_VSIM 871;
BA_ "FlexKomIsMotorola" SG_ 998 BU_NetCfg_VSIM 1;
BA_ "FlexKomComment" SG_ 998 BU_NetCfg_VSIM "Backup for network ECU config data for interior";
BA_ "GenSigSNA" SG_ 998 BU_NetCfg_VTM "0h";
BA_ "GenSigSendType" SG_ 998 BU_NetCfg_VTM 1;
BA_ "FlexKomSigStartValue" SG_ 998 BU_NetCfg_VTM "0300000000000000h";
BA_ "FlexKomSigStartPos" SG_ 998 BU_NetCfg_VTM 7;
BA_ "FlexKomSigName" SG_ 998 BU_NetCfg_VTM "BU_NET_CFG_DATA_INT";
BA_ "FlexKomSigLaenge" SG_ 998 BU_NetCfg_VTM 64;
BA_ "FlexKomSID" SG_ 998 BU_NetCfg_VTM 871;
BA_ "FlexKomIsMotorola" SG_ 998 BU_NetCfg_VTM 1;
BA_ "FlexKomComment" SG_ 998 BU_NetCfg_VTM "Backup for network ECU config data for interior";
BA_ "GenSigStartValue" SG_ 999 BU_NET_CFG_STAT_PT 3;
BA_ "GenSigSNA" SG_ 999 BU_NET_CFG_STAT_PT "3h";
BA_ "GenSigSendType" SG_ 999 BU_NET_CFG_STAT_PT 1;
BA_ "FlexKomSigStartValue" SG_ 999 BU_NET_CFG_STAT_PT "0300000000000000h";
BA_ "FlexKomSigStartPos" SG_ 999 BU_NET_CFG_STAT_PT 7;
BA_ "FlexKomSigName" SG_ 999 BU_NET_CFG_STAT_PT "BU_NET_CFG_DATA_PT";
BA_ "FlexKomSigLaenge" SG_ 999 BU_NET_CFG_STAT_PT 64;
BA_ "FlexKomSID" SG_ 999 BU_NET_CFG_STAT_PT 872;
BA_ "FlexKomIsMotorola" SG_ 999 BU_NET_CFG_STAT_PT 1;
BA_ "FlexKomComment" SG_ 999 BU_NET_CFG_STAT_PT "Backup for network ECU config data for Powertrain";
BA_ "GenSigSNA" SG_ 999 BU_NetCfg_ACC "0h";
BA_ "GenSigSendType" SG_ 999 BU_NetCfg_ACC 1;
BA_ "FlexKomSigStartValue" SG_ 999 BU_NetCfg_ACC "0300000000000000h";
BA_ "FlexKomSigStartPos" SG_ 999 BU_NetCfg_ACC 7;
BA_ "FlexKomSigName" SG_ 999 BU_NetCfg_ACC "BU_NET_CFG_DATA_PT";
BA_ "FlexKomSigLaenge" SG_ 999 BU_NetCfg_ACC 64;
BA_ "FlexKomSID" SG_ 999 BU_NetCfg_ACC 872;
BA_ "FlexKomIsMotorola" SG_ 999 BU_NetCfg_ACC 1;
BA_ "FlexKomComment" SG_ 999 BU_NetCfg_ACC "Backup for network ECU config data for Powertrain";
BA_ "GenSigSNA" SG_ 999 BU_NetCfg_ADCM "0h";
BA_ "GenSigSendType" SG_ 999 BU_NetCfg_ADCM 1;
BA_ "FlexKomSigStartValue" SG_ 999 BU_NetCfg_ADCM "0300000000000000h";
BA_ "FlexKomSigStartPos" SG_ 999 BU_NetCfg_ADCM 7;
BA_ "FlexKomSigName" SG_ 999 BU_NetCfg_ADCM "BU_NET_CFG_DATA_PT";
BA_ "FlexKomSigLaenge" SG_ 999 BU_NetCfg_ADCM 64;
BA_ "FlexKomSID" SG_ 999 BU_NetCfg_ADCM 872;
BA_ "FlexKomIsMotorola" SG_ 999 BU_NetCfg_ADCM 1;
BA_ "FlexKomComment" SG_ 999 BU_NetCfg_ADCM "Backup for network ECU config data for Powertrain";
BA_ "GenSigSNA" SG_ 999 BU_NetCfg_AFLS "0h";
BA_ "GenSigSendType" SG_ 999 BU_NetCfg_AFLS 1;
BA_ "FlexKomSigStartValue" SG_ 999 BU_NetCfg_AFLS "0300000000000000h";
BA_ "FlexKomSigStartPos" SG_ 999 BU_NetCfg_AFLS 7;
BA_ "FlexKomSigName" SG_ 999 BU_NetCfg_AFLS "BU_NET_CFG_DATA_PT";
BA_ "FlexKomSigLaenge" SG_ 999 BU_NetCfg_AFLS 64;
BA_ "FlexKomSID" SG_ 999 BU_NetCfg_AFLS 872;
BA_ "FlexKomIsMotorola" SG_ 999 BU_NetCfg_AFLS 1;
BA_ "FlexKomComment" SG_ 999 BU_NetCfg_AFLS "Backup for network ECU config data for Powertrain";
BA_ "GenSigSNA" SG_ 999 BU_NetCfg_AHLM "0h";
BA_ "GenSigSendType" SG_ 999 BU_NetCfg_AHLM 1;
BA_ "FlexKomSigStartValue" SG_ 999 BU_NetCfg_AHLM "0300000000000000h";
BA_ "FlexKomSigStartPos" SG_ 999 BU_NetCfg_AHLM 7;
BA_ "FlexKomSigName" SG_ 999 BU_NetCfg_AHLM "BU_NET_CFG_DATA_PT";
BA_ "FlexKomSigLaenge" SG_ 999 BU_NetCfg_AHLM 64;
BA_ "FlexKomSID" SG_ 999 BU_NetCfg_AHLM 872;
BA_ "FlexKomIsMotorola" SG_ 999 BU_NetCfg_AHLM 1;
BA_ "FlexKomComment" SG_ 999 BU_NetCfg_AHLM "Backup for network ECU config data for Powertrain";
BA_ "GenSigSNA" SG_ 999 BU_NetCfg_ANC "0h";
BA_ "GenSigSendType" SG_ 999 BU_NetCfg_ANC 1;
BA_ "FlexKomSigStartValue" SG_ 999 BU_NetCfg_ANC "0300000000000000h";
BA_ "FlexKomSigStartPos" SG_ 999 BU_NetCfg_ANC 7;
BA_ "FlexKomSigName" SG_ 999 BU_NetCfg_ANC "BU_NET_CFG_DATA_PT";
BA_ "FlexKomSigLaenge" SG_ 999 BU_NetCfg_ANC 64;
BA_ "FlexKomSID" SG_ 999 BU_NetCfg_ANC 872;
BA_ "FlexKomIsMotorola" SG_ 999 BU_NetCfg_ANC 1;
BA_ "FlexKomComment" SG_ 999 BU_NetCfg_ANC "Backup for network ECU config data for Powertrain";
BA_ "GenSigSNA" SG_ 999 BU_NetCfg_ASBS "0h";
BA_ "GenSigSendType" SG_ 999 BU_NetCfg_ASBS 1;
BA_ "FlexKomSigStartValue" SG_ 999 BU_NetCfg_ASBS "0300000000000000h";
BA_ "FlexKomSigStartPos" SG_ 999 BU_NetCfg_ASBS 7;
BA_ "FlexKomSigName" SG_ 999 BU_NetCfg_ASBS "BU_NET_CFG_DATA_PT";
BA_ "FlexKomSigLaenge" SG_ 999 BU_NetCfg_ASBS 64;
BA_ "FlexKomSID" SG_ 999 BU_NetCfg_ASBS 872;
BA_ "FlexKomIsMotorola" SG_ 999 BU_NetCfg_ASBS 1;
BA_ "FlexKomComment" SG_ 999 BU_NetCfg_ASBS "Backup for network ECU config data for Powertrain";
BA_ "GenSigSNA" SG_ 999 BU_NetCfg_ASCM "0h";
BA_ "GenSigSendType" SG_ 999 BU_NetCfg_ASCM 1;
BA_ "FlexKomSigStartValue" SG_ 999 BU_NetCfg_ASCM "0300000000000000h";
BA_ "FlexKomSigStartPos" SG_ 999 BU_NetCfg_ASCM 7;
BA_ "FlexKomSigName" SG_ 999 BU_NetCfg_ASCM "BU_NET_CFG_DATA_PT";
BA_ "FlexKomSigLaenge" SG_ 999 BU_NetCfg_ASCM 64;
BA_ "FlexKomSID" SG_ 999 BU_NetCfg_ASCM 872;
BA_ "FlexKomIsMotorola" SG_ 999 BU_NetCfg_ASCM 1;
BA_ "FlexKomComment" SG_ 999 BU_NetCfg_ASCM "Backup for network ECU config data for Powertrain";
BA_ "GenSigSNA" SG_ 999 BU_NetCfg_BSMO "0h";
BA_ "GenSigSendType" SG_ 999 BU_NetCfg_BSMO 1;
BA_ "FlexKomSigStartValue" SG_ 999 BU_NetCfg_BSMO "0300000000000000h";
BA_ "FlexKomSigStartPos" SG_ 999 BU_NetCfg_BSMO 7;
BA_ "FlexKomSigName" SG_ 999 BU_NetCfg_BSMO "BU_NET_CFG_DATA_PT";
BA_ "FlexKomSigLaenge" SG_ 999 BU_NetCfg_BSMO 64;
BA_ "FlexKomSID" SG_ 999 BU_NetCfg_BSMO 872;
BA_ "FlexKomIsMotorola" SG_ 999 BU_NetCfg_BSMO 1;
BA_ "FlexKomComment" SG_ 999 BU_NetCfg_BSMO "Backup for network ECU config data for Powertrain";
BA_ "GenSigSNA" SG_ 999 BU_NetCfg_CBC_PT "0h";
BA_ "GenSigSendType" SG_ 999 BU_NetCfg_CBC_PT 1;
BA_ "FlexKomSigStartValue" SG_ 999 BU_NetCfg_CBC_PT "0300000000000000h";
BA_ "FlexKomSigStartPos" SG_ 999 BU_NetCfg_CBC_PT 7;
BA_ "FlexKomSigName" SG_ 999 BU_NetCfg_CBC_PT "BU_NET_CFG_DATA_PT";
BA_ "FlexKomSigLaenge" SG_ 999 BU_NetCfg_CBC_PT 64;
BA_ "FlexKomSID" SG_ 999 BU_NetCfg_CBC_PT 872;
BA_ "FlexKomIsMotorola" SG_ 999 BU_NetCfg_CBC_PT 1;
BA_ "FlexKomComment" SG_ 999 BU_NetCfg_CBC_PT "Backup for network ECU config data for Powertrain";
BA_ "GenSigSNA" SG_ 999 BU_NetCfg_DASM "0h";
BA_ "GenSigSendType" SG_ 999 BU_NetCfg_DASM 1;
BA_ "FlexKomSigStartValue" SG_ 999 BU_NetCfg_DASM "0300000000000000h";
BA_ "FlexKomSigStartPos" SG_ 999 BU_NetCfg_DASM 7;
BA_ "FlexKomSigName" SG_ 999 BU_NetCfg_DASM "BU_NET_CFG_DATA_PT";
BA_ "FlexKomSigLaenge" SG_ 999 BU_NetCfg_DASM 64;
BA_ "FlexKomSID" SG_ 999 BU_NetCfg_DASM 872;
BA_ "FlexKomIsMotorola" SG_ 999 BU_NetCfg_DASM 1;
BA_ "FlexKomComment" SG_ 999 BU_NetCfg_DASM "Backup for network ECU config data for Powertrain";
BA_ "GenSigSNA" SG_ 999 BU_NetCfg_DPDM "0h";
BA_ "GenSigSendType" SG_ 999 BU_NetCfg_DPDM 1;
BA_ "FlexKomSigStartValue" SG_ 999 BU_NetCfg_DPDM "0300000000000000h";
BA_ "FlexKomSigStartPos" SG_ 999 BU_NetCfg_DPDM 7;
BA_ "FlexKomSigName" SG_ 999 BU_NetCfg_DPDM "BU_NET_CFG_DATA_PT";
BA_ "FlexKomSigLaenge" SG_ 999 BU_NetCfg_DPDM 64;
BA_ "FlexKomSID" SG_ 999 BU_NetCfg_DPDM 872;
BA_ "FlexKomIsMotorola" SG_ 999 BU_NetCfg_DPDM 1;
BA_ "FlexKomComment" SG_ 999 BU_NetCfg_DPDM "Backup for network ECU config data for Powertrain";
BA_ "GenSigSNA" SG_ 999 BU_NetCfg_DTCM "0h";
BA_ "GenSigSendType" SG_ 999 BU_NetCfg_DTCM 1;
BA_ "FlexKomSigStartValue" SG_ 999 BU_NetCfg_DTCM "0300000000000000h";
BA_ "FlexKomSigStartPos" SG_ 999 BU_NetCfg_DTCM 7;
BA_ "FlexKomSigName" SG_ 999 BU_NetCfg_DTCM "BU_NET_CFG_DATA_PT";
BA_ "FlexKomSigLaenge" SG_ 999 BU_NetCfg_DTCM 64;
BA_ "FlexKomSID" SG_ 999 BU_NetCfg_DTCM 872;
BA_ "FlexKomIsMotorola" SG_ 999 BU_NetCfg_DTCM 1;
BA_ "FlexKomComment" SG_ 999 BU_NetCfg_DTCM "Backup for network ECU config data for Powertrain";
BA_ "GenSigSNA" SG_ 999 BU_NetCfg_ECM "0h";
BA_ "GenSigSendType" SG_ 999 BU_NetCfg_ECM 1;
BA_ "FlexKomSigStartValue" SG_ 999 BU_NetCfg_ECM "0300000000000000h";
BA_ "FlexKomSigStartPos" SG_ 999 BU_NetCfg_ECM 7;
BA_ "FlexKomSigName" SG_ 999 BU_NetCfg_ECM "BU_NET_CFG_DATA_PT";
BA_ "FlexKomSigLaenge" SG_ 999 BU_NetCfg_ECM 64;
BA_ "FlexKomSID" SG_ 999 BU_NetCfg_ECM 872;
BA_ "FlexKomIsMotorola" SG_ 999 BU_NetCfg_ECM 1;
BA_ "FlexKomComment" SG_ 999 BU_NetCfg_ECM "Backup for network ECU config data for Powertrain";
BA_ "GenSigSNA" SG_ 999 BU_NetCfg_ELSD "0h";
BA_ "GenSigSendType" SG_ 999 BU_NetCfg_ELSD 1;
BA_ "FlexKomSigStartValue" SG_ 999 BU_NetCfg_ELSD "0300000000000000h";
BA_ "FlexKomSigStartPos" SG_ 999 BU_NetCfg_ELSD 7;
BA_ "FlexKomSigName" SG_ 999 BU_NetCfg_ELSD "BU_NET_CFG_DATA_PT";
BA_ "FlexKomSigLaenge" SG_ 999 BU_NetCfg_ELSD 64;
BA_ "FlexKomSID" SG_ 999 BU_NetCfg_ELSD 872;
BA_ "FlexKomIsMotorola" SG_ 999 BU_NetCfg_ELSD 1;
BA_ "FlexKomComment" SG_ 999 BU_NetCfg_ELSD "Backup for network ECU config data for Powertrain";
BA_ "GenSigSNA" SG_ 999 BU_NetCfg_EPB "0h";
BA_ "GenSigSendType" SG_ 999 BU_NetCfg_EPB 1;
BA_ "FlexKomSigStartValue" SG_ 999 BU_NetCfg_EPB "0300000000000000h";
BA_ "FlexKomSigStartPos" SG_ 999 BU_NetCfg_EPB 7;
BA_ "FlexKomSigName" SG_ 999 BU_NetCfg_EPB "BU_NET_CFG_DATA_PT";
BA_ "FlexKomSigLaenge" SG_ 999 BU_NetCfg_EPB 64;
BA_ "FlexKomSID" SG_ 999 BU_NetCfg_EPB 872;
BA_ "FlexKomIsMotorola" SG_ 999 BU_NetCfg_EPB 1;
BA_ "FlexKomComment" SG_ 999 BU_NetCfg_EPB "Backup for network ECU config data for Powertrain";
BA_ "GenSigSNA" SG_ 999 BU_NetCfg_EPPM "0h";
BA_ "GenSigSendType" SG_ 999 BU_NetCfg_EPPM 1;
BA_ "FlexKomSigStartValue" SG_ 999 BU_NetCfg_EPPM "0300000000000000h";
BA_ "FlexKomSigStartPos" SG_ 999 BU_NetCfg_EPPM 7;
BA_ "FlexKomSigName" SG_ 999 BU_NetCfg_EPPM "BU_NET_CFG_DATA_PT";
BA_ "FlexKomSigLaenge" SG_ 999 BU_NetCfg_EPPM 64;
BA_ "FlexKomSID" SG_ 999 BU_NetCfg_EPPM 872;
BA_ "FlexKomIsMotorola" SG_ 999 BU_NetCfg_EPPM 1;
BA_ "FlexKomComment" SG_ 999 BU_NetCfg_EPPM "Backup for network ECU config data for Powertrain";
BA_ "GenSigSNA" SG_ 999 BU_NetCfg_EPS "0h";
BA_ "GenSigSendType" SG_ 999 BU_NetCfg_EPS 1;
BA_ "FlexKomSigStartValue" SG_ 999 BU_NetCfg_EPS "0300000000000000h";
BA_ "FlexKomSigStartPos" SG_ 999 BU_NetCfg_EPS 7;
BA_ "FlexKomSigName" SG_ 999 BU_NetCfg_EPS "BU_NET_CFG_DATA_PT";
BA_ "FlexKomSigLaenge" SG_ 999 BU_NetCfg_EPS 64;
BA_ "FlexKomSID" SG_ 999 BU_NetCfg_EPS 872;
BA_ "FlexKomIsMotorola" SG_ 999 BU_NetCfg_EPS 1;
BA_ "FlexKomComment" SG_ 999 BU_NetCfg_EPS "Backup for network ECU config data for Powertrain";
BA_ "GenSigSNA" SG_ 999 BU_NetCfg_ESC "0h";
BA_ "GenSigSendType" SG_ 999 BU_NetCfg_ESC 1;
BA_ "FlexKomSigStartValue" SG_ 999 BU_NetCfg_ESC "0300000000000000h";
BA_ "FlexKomSigStartPos" SG_ 999 BU_NetCfg_ESC 7;
BA_ "FlexKomSigName" SG_ 999 BU_NetCfg_ESC "BU_NET_CFG_DATA_PT";
BA_ "FlexKomSigLaenge" SG_ 999 BU_NetCfg_ESC 64;
BA_ "FlexKomSID" SG_ 999 BU_NetCfg_ESC 872;
BA_ "FlexKomIsMotorola" SG_ 999 BU_NetCfg_ESC 1;
BA_ "FlexKomComment" SG_ 999 BU_NetCfg_ESC "Backup for network ECU config data for Powertrain";
BA_ "GenSigSNA" SG_ 999 BU_NetCfg_ESL "0h";
BA_ "GenSigSendType" SG_ 999 BU_NetCfg_ESL 1;
BA_ "FlexKomSigStartValue" SG_ 999 BU_NetCfg_ESL "0300000000000000h";
BA_ "FlexKomSigStartPos" SG_ 999 BU_NetCfg_ESL 7;
BA_ "FlexKomSigName" SG_ 999 BU_NetCfg_ESL "BU_NET_CFG_DATA_PT";
BA_ "FlexKomSigLaenge" SG_ 999 BU_NetCfg_ESL 64;
BA_ "FlexKomSID" SG_ 999 BU_NetCfg_ESL 872;
BA_ "FlexKomIsMotorola" SG_ 999 BU_NetCfg_ESL 1;
BA_ "FlexKomComment" SG_ 999 BU_NetCfg_ESL "Backup for network ECU config data for Powertrain";
BA_ "GenSigSNA" SG_ 999 BU_NetCfg_ESM "0h";
BA_ "GenSigSendType" SG_ 999 BU_NetCfg_ESM 1;
BA_ "FlexKomSigStartValue" SG_ 999 BU_NetCfg_ESM "0300000000000000h";
BA_ "FlexKomSigStartPos" SG_ 999 BU_NetCfg_ESM 7;
BA_ "FlexKomSigName" SG_ 999 BU_NetCfg_ESM "BU_NET_CFG_DATA_PT";
BA_ "FlexKomSigLaenge" SG_ 999 BU_NetCfg_ESM 64;
BA_ "FlexKomSID" SG_ 999 BU_NetCfg_ESM 872;
BA_ "FlexKomIsMotorola" SG_ 999 BU_NetCfg_ESM 1;
BA_ "FlexKomComment" SG_ 999 BU_NetCfg_ESM "Backup for network ECU config data for Powertrain";
BA_ "GenSigSNA" SG_ 999 BU_NetCfg_FDCM "0h";
BA_ "GenSigSendType" SG_ 999 BU_NetCfg_FDCM 1;
BA_ "FlexKomSigStartValue" SG_ 999 BU_NetCfg_FDCM "0300000000000000h";
BA_ "FlexKomSigStartPos" SG_ 999 BU_NetCfg_FDCM 7;
BA_ "FlexKomSigName" SG_ 999 BU_NetCfg_FDCM "BU_NET_CFG_DATA_PT";
BA_ "FlexKomSigLaenge" SG_ 999 BU_NetCfg_FDCM 64;
BA_ "FlexKomSID" SG_ 999 BU_NetCfg_FDCM 872;
BA_ "FlexKomIsMotorola" SG_ 999 BU_NetCfg_FDCM 1;
BA_ "FlexKomComment" SG_ 999 BU_NetCfg_FDCM "Backup for network ECU config data for Powertrain";
BA_ "GenSigSNA" SG_ 999 BU_NetCfg_GPF "0h";
BA_ "GenSigSendType" SG_ 999 BU_NetCfg_GPF 1;
BA_ "FlexKomSigStartValue" SG_ 999 BU_NetCfg_GPF "0300000000000000h";
BA_ "FlexKomSigStartPos" SG_ 999 BU_NetCfg_GPF 7;
BA_ "FlexKomSigName" SG_ 999 BU_NetCfg_GPF "BU_NET_CFG_DATA_PT";
BA_ "FlexKomSigLaenge" SG_ 999 BU_NetCfg_GPF 64;
BA_ "FlexKomSID" SG_ 999 BU_NetCfg_GPF 872;
BA_ "FlexKomIsMotorola" SG_ 999 BU_NetCfg_GPF 1;
BA_ "FlexKomComment" SG_ 999 BU_NetCfg_GPF "Backup for network ECU config data for Powertrain";
BA_ "GenSigSNA" SG_ 999 BU_NetCfg_HCP "0h";
BA_ "GenSigSendType" SG_ 999 BU_NetCfg_HCP 1;
BA_ "FlexKomSigStartValue" SG_ 999 BU_NetCfg_HCP "0300000000000000h";
BA_ "FlexKomSigStartPos" SG_ 999 BU_NetCfg_HCP 7;
BA_ "FlexKomSigName" SG_ 999 BU_NetCfg_HCP "BU_NET_CFG_DATA_PT";
BA_ "FlexKomSigLaenge" SG_ 999 BU_NetCfg_HCP 64;
BA_ "FlexKomSID" SG_ 999 BU_NetCfg_HCP 872;
BA_ "FlexKomIsMotorola" SG_ 999 BU_NetCfg_HCP 1;
BA_ "FlexKomComment" SG_ 999 BU_NetCfg_HCP "Backup for network ECU config data for Powertrain";
BA_ "GenSigSNA" SG_ 999 BU_NetCfg_HaLF "0h";
BA_ "GenSigSendType" SG_ 999 BU_NetCfg_HaLF 1;
BA_ "FlexKomSigStartValue" SG_ 999 BU_NetCfg_HaLF "0300000000000000h";
BA_ "FlexKomSigStartPos" SG_ 999 BU_NetCfg_HaLF 7;
BA_ "FlexKomSigName" SG_ 999 BU_NetCfg_HaLF "BU_NET_CFG_DATA_PT";
BA_ "FlexKomSigLaenge" SG_ 999 BU_NetCfg_HaLF 64;
BA_ "FlexKomSID" SG_ 999 BU_NetCfg_HaLF 872;
BA_ "FlexKomIsMotorola" SG_ 999 BU_NetCfg_HaLF 1;
BA_ "FlexKomComment" SG_ 999 BU_NetCfg_HaLF "Backup for network ECU config data for Powertrain";
BA_ "GenSigSNA" SG_ 999 BU_NetCfg_IC "0h";
BA_ "GenSigSendType" SG_ 999 BU_NetCfg_IC 1;
BA_ "FlexKomSigStartValue" SG_ 999 BU_NetCfg_IC "0300000000000000h";
BA_ "FlexKomSigStartPos" SG_ 999 BU_NetCfg_IC 7;
BA_ "FlexKomSigName" SG_ 999 BU_NetCfg_IC "BU_NET_CFG_DATA_PT";
BA_ "FlexKomSigLaenge" SG_ 999 BU_NetCfg_IC 64;
BA_ "FlexKomSID" SG_ 999 BU_NetCfg_IC 872;
BA_ "FlexKomIsMotorola" SG_ 999 BU_NetCfg_IC 1;
BA_ "FlexKomComment" SG_ 999 BU_NetCfg_IC "Backup for network ECU config data for Powertrain";
BA_ "GenSigSNA" SG_ 999 BU_NetCfg_ITBM "0h";
BA_ "GenSigSendType" SG_ 999 BU_NetCfg_ITBM 1;
BA_ "FlexKomSigStartValue" SG_ 999 BU_NetCfg_ITBM "0300000000000000h";
BA_ "FlexKomSigStartPos" SG_ 999 BU_NetCfg_ITBM 7;
BA_ "FlexKomSigName" SG_ 999 BU_NetCfg_ITBM "BU_NET_CFG_DATA_PT";
BA_ "FlexKomSigLaenge" SG_ 999 BU_NetCfg_ITBM 64;
BA_ "FlexKomSID" SG_ 999 BU_NetCfg_ITBM 872;
BA_ "FlexKomIsMotorola" SG_ 999 BU_NetCfg_ITBM 1;
BA_ "FlexKomComment" SG_ 999 BU_NetCfg_ITBM "Backup for network ECU config data for Powertrain";
BA_ "GenSigSNA" SG_ 999 BU_NetCfg_OCM "0h";
BA_ "GenSigSendType" SG_ 999 BU_NetCfg_OCM 1;
BA_ "FlexKomSigStartValue" SG_ 999 BU_NetCfg_OCM "0300000000000000h";
BA_ "FlexKomSigStartPos" SG_ 999 BU_NetCfg_OCM 7;
BA_ "FlexKomSigName" SG_ 999 BU_NetCfg_OCM "BU_NET_CFG_DATA_PT";
BA_ "FlexKomSigLaenge" SG_ 999 BU_NetCfg_OCM 64;
BA_ "FlexKomSID" SG_ 999 BU_NetCfg_OCM 872;
BA_ "FlexKomIsMotorola" SG_ 999 BU_NetCfg_OCM 1;
BA_ "FlexKomComment" SG_ 999 BU_NetCfg_OCM "Backup for network ECU config data for Powertrain";
BA_ "GenSigSNA" SG_ 999 BU_NetCfg_ORC "0h";
BA_ "GenSigSendType" SG_ 999 BU_NetCfg_ORC 1;
BA_ "FlexKomSigStartValue" SG_ 999 BU_NetCfg_ORC "0300000000000000h";
BA_ "FlexKomSigStartPos" SG_ 999 BU_NetCfg_ORC 7;
BA_ "FlexKomSigName" SG_ 999 BU_NetCfg_ORC "BU_NET_CFG_DATA_PT";
BA_ "FlexKomSigLaenge" SG_ 999 BU_NetCfg_ORC 64;
BA_ "FlexKomSID" SG_ 999 BU_NetCfg_ORC 872;
BA_ "FlexKomIsMotorola" SG_ 999 BU_NetCfg_ORC 1;
BA_ "FlexKomComment" SG_ 999 BU_NetCfg_ORC "Backup for network ECU config data for Powertrain";
BA_ "GenSigSNA" SG_ 999 BU_NetCfg_PASS_PT "0h";
BA_ "GenSigSendType" SG_ 999 BU_NetCfg_PASS_PT 1;
BA_ "FlexKomSigStartValue" SG_ 999 BU_NetCfg_PASS_PT "0300000000000000h";
BA_ "FlexKomSigStartPos" SG_ 999 BU_NetCfg_PASS_PT 7;
BA_ "FlexKomSigName" SG_ 999 BU_NetCfg_PASS_PT "BU_NET_CFG_DATA_PT";
BA_ "FlexKomSigLaenge" SG_ 999 BU_NetCfg_PASS_PT 64;
BA_ "FlexKomSID" SG_ 999 BU_NetCfg_PASS_PT 872;
BA_ "FlexKomIsMotorola" SG_ 999 BU_NetCfg_PASS_PT 1;
BA_ "FlexKomComment" SG_ 999 BU_NetCfg_PASS_PT "Backup for network ECU config data for Powertrain";
BA_ "GenSigSNA" SG_ 999 BU_NetCfg_PTS "0h";
BA_ "GenSigSendType" SG_ 999 BU_NetCfg_PTS 1;
BA_ "FlexKomSigStartValue" SG_ 999 BU_NetCfg_PTS "0300000000000000h";
BA_ "FlexKomSigStartPos" SG_ 999 BU_NetCfg_PTS 7;
BA_ "FlexKomSigName" SG_ 999 BU_NetCfg_PTS "BU_NET_CFG_DATA_PT";
BA_ "FlexKomSigLaenge" SG_ 999 BU_NetCfg_PTS 64;
BA_ "FlexKomSID" SG_ 999 BU_NetCfg_PTS 872;
BA_ "FlexKomIsMotorola" SG_ 999 BU_NetCfg_PTS 1;
BA_ "FlexKomComment" SG_ 999 BU_NetCfg_PTS "Backup for network ECU config data for Powertrain";
BA_ "GenSigSNA" SG_ 999 BU_NetCfg_RF_HUB "0h";
BA_ "GenSigSendType" SG_ 999 BU_NetCfg_RF_HUB 1;
BA_ "FlexKomSigStartValue" SG_ 999 BU_NetCfg_RF_HUB "0300000000000000h";
BA_ "FlexKomSigStartPos" SG_ 999 BU_NetCfg_RF_HUB 7;
BA_ "FlexKomSigName" SG_ 999 BU_NetCfg_RF_HUB "BU_NET_CFG_DATA_PT";
BA_ "FlexKomSigLaenge" SG_ 999 BU_NetCfg_RF_HUB 64;
BA_ "FlexKomSID" SG_ 999 BU_NetCfg_RF_HUB 872;
BA_ "FlexKomIsMotorola" SG_ 999 BU_NetCfg_RF_HUB 1;
BA_ "FlexKomComment" SG_ 999 BU_NetCfg_RF_HUB "Backup for network ECU config data for Powertrain";
BA_ "GenSigSNA" SG_ 999 BU_NetCfg_SCCM "0h";
BA_ "GenSigSendType" SG_ 999 BU_NetCfg_SCCM 1;
BA_ "FlexKomSigStartValue" SG_ 999 BU_NetCfg_SCCM "0300000000000000h";
BA_ "FlexKomSigStartPos" SG_ 999 BU_NetCfg_SCCM 7;
BA_ "FlexKomSigName" SG_ 999 BU_NetCfg_SCCM "BU_NET_CFG_DATA_PT";
BA_ "FlexKomSigLaenge" SG_ 999 BU_NetCfg_SCCM 64;
BA_ "FlexKomSID" SG_ 999 BU_NetCfg_SCCM 872;
BA_ "FlexKomIsMotorola" SG_ 999 BU_NetCfg_SCCM 1;
BA_ "FlexKomComment" SG_ 999 BU_NetCfg_SCCM "Backup for network ECU config data for Powertrain";
BA_ "GenSigSNA" SG_ 999 BU_NetCfg_SGW "0h";
BA_ "GenSigSendType" SG_ 999 BU_NetCfg_SGW 1;
BA_ "FlexKomSigStartValue" SG_ 999 BU_NetCfg_SGW "0300000000000000h";
BA_ "FlexKomSigStartPos" SG_ 999 BU_NetCfg_SGW 7;
BA_ "FlexKomSigName" SG_ 999 BU_NetCfg_SGW "BU_NET_CFG_DATA_PT";
BA_ "FlexKomSigLaenge" SG_ 999 BU_NetCfg_SGW 64;
BA_ "FlexKomSID" SG_ 999 BU_NetCfg_SGW 872;
BA_ "FlexKomIsMotorola" SG_ 999 BU_NetCfg_SGW 1;
BA_ "FlexKomComment" SG_ 999 BU_NetCfg_SGW "Backup for network ECU config data for Powertrain";
BA_ "GenSigSNA" SG_ 999 BU_NetCfg_TCM "0h";
BA_ "GenSigSendType" SG_ 999 BU_NetCfg_TCM 1;
BA_ "FlexKomSigStartValue" SG_ 999 BU_NetCfg_TCM "0300000000000000h";
BA_ "FlexKomSigStartPos" SG_ 999 BU_NetCfg_TCM 7;
BA_ "FlexKomSigName" SG_ 999 BU_NetCfg_TCM "BU_NET_CFG_DATA_PT";
BA_ "FlexKomSigLaenge" SG_ 999 BU_NetCfg_TCM 64;
BA_ "FlexKomSID" SG_ 999 BU_NetCfg_TCM 872;
BA_ "FlexKomIsMotorola" SG_ 999 BU_NetCfg_TCM 1;
BA_ "FlexKomComment" SG_ 999 BU_NetCfg_TCM "Backup for network ECU config data for Powertrain";
BA_ "GenSigSNA" SG_ 999 BU_NetCfg_TIM "0h";
BA_ "GenSigSendType" SG_ 999 BU_NetCfg_TIM 1;
BA_ "FlexKomSigStartValue" SG_ 999 BU_NetCfg_TIM "0300000000000000h";
BA_ "FlexKomSigStartPos" SG_ 999 BU_NetCfg_TIM 7;
BA_ "FlexKomSigName" SG_ 999 BU_NetCfg_TIM "BU_NET_CFG_DATA_PT";
BA_ "FlexKomSigLaenge" SG_ 999 BU_NetCfg_TIM 64;
BA_ "FlexKomSID" SG_ 999 BU_NetCfg_TIM 872;
BA_ "FlexKomIsMotorola" SG_ 999 BU_NetCfg_TIM 1;
BA_ "FlexKomComment" SG_ 999 BU_NetCfg_TIM "Backup for network ECU config data for Powertrain";
BA_ "GenSigSNA" SG_ 999 BU_NetCfg_TPM "0h";
BA_ "GenSigSendType" SG_ 999 BU_NetCfg_TPM 1;
BA_ "FlexKomSigStartValue" SG_ 999 BU_NetCfg_TPM "0300000000000000h";
BA_ "FlexKomSigStartPos" SG_ 999 BU_NetCfg_TPM 7;
BA_ "FlexKomSigName" SG_ 999 BU_NetCfg_TPM "BU_NET_CFG_DATA_PT";
BA_ "FlexKomSigLaenge" SG_ 999 BU_NetCfg_TPM 64;
BA_ "FlexKomSID" SG_ 999 BU_NetCfg_TPM 872;
BA_ "FlexKomIsMotorola" SG_ 999 BU_NetCfg_TPM 1;
BA_ "FlexKomComment" SG_ 999 BU_NetCfg_TPM "Backup for network ECU config data for Powertrain";
BA_ "GenSigSNA" SG_ 999 BU_NetCfg_TTPM "0h";
BA_ "GenSigSendType" SG_ 999 BU_NetCfg_TTPM 1;
BA_ "FlexKomSigStartValue" SG_ 999 BU_NetCfg_TTPM "0300000000000000h";
BA_ "FlexKomSigStartPos" SG_ 999 BU_NetCfg_TTPM 7;
BA_ "FlexKomSigName" SG_ 999 BU_NetCfg_TTPM "BU_NET_CFG_DATA_PT";
BA_ "FlexKomSigLaenge" SG_ 999 BU_NetCfg_TTPM 64;
BA_ "FlexKomSID" SG_ 999 BU_NetCfg_TTPM 872;
BA_ "FlexKomIsMotorola" SG_ 999 BU_NetCfg_TTPM 1;
BA_ "FlexKomComment" SG_ 999 BU_NetCfg_TTPM "Backup for network ECU config data for Powertrain";
BA_ "GenSigSNA" SG_ 999 BU_NetCfg_VSIM_C "0h";
BA_ "GenSigSendType" SG_ 999 BU_NetCfg_VSIM_C 1;
BA_ "FlexKomSigStartValue" SG_ 999 BU_NetCfg_VSIM_C "0300000000000000h";
BA_ "FlexKomSigStartPos" SG_ 999 BU_NetCfg_VSIM_C 7;
BA_ "FlexKomSigName" SG_ 999 BU_NetCfg_VSIM_C "BU_NET_CFG_DATA_PT";
BA_ "FlexKomSigLaenge" SG_ 999 BU_NetCfg_VSIM_C 64;
BA_ "FlexKomSID" SG_ 999 BU_NetCfg_VSIM_C 872;
BA_ "FlexKomIsMotorola" SG_ 999 BU_NetCfg_VSIM_C 1;
BA_ "FlexKomComment" SG_ 999 BU_NetCfg_VSIM_C "Backup for network ECU config data for Powertrain";
BA_ "GenSigStartValue" SG_ 927 BU_NET_CFG_STAT_ePT 3;
BA_ "GenSigSNA" SG_ 927 BU_NET_CFG_STAT_ePT "3h";
BA_ "GenSigSendType" SG_ 927 BU_NET_CFG_STAT_ePT 1;
BA_ "FlexKomSigStartValue" SG_ 927 BU_NET_CFG_STAT_ePT "030000h";
BA_ "FlexKomSigStartPos" SG_ 927 BU_NET_CFG_STAT_ePT 7;
BA_ "FlexKomSigName" SG_ 927 BU_NET_CFG_STAT_ePT "BU_NET_CFG_DATA_ePT";
BA_ "FlexKomSigLaenge" SG_ 927 BU_NET_CFG_STAT_ePT 24;
BA_ "FlexKomSID" SG_ 927 BU_NET_CFG_STAT_ePT 2470;
BA_ "FlexKomIsMotorola" SG_ 927 BU_NET_CFG_STAT_ePT 1;
BA_ "FlexKomComment" SG_ 927 BU_NET_CFG_STAT_ePT "Backup for network ECU config data for hybrid netw";
BA_ "GenSigSNA" SG_ 927 BU_NetCfg_AHCP_ePT "0h";
BA_ "GenSigSendType" SG_ 927 BU_NetCfg_AHCP_ePT 1;
BA_ "FlexKomSigStartValue" SG_ 927 BU_NetCfg_AHCP_ePT "030000h";
BA_ "FlexKomSigStartPos" SG_ 927 BU_NetCfg_AHCP_ePT 7;
BA_ "FlexKomSigName" SG_ 927 BU_NetCfg_AHCP_ePT "BU_NET_CFG_DATA_ePT";
BA_ "FlexKomSigLaenge" SG_ 927 BU_NetCfg_AHCP_ePT 24;
BA_ "FlexKomSID" SG_ 927 BU_NetCfg_AHCP_ePT 2470;
BA_ "FlexKomIsMotorola" SG_ 927 BU_NetCfg_AHCP_ePT 1;
BA_ "FlexKomComment" SG_ 927 BU_NetCfg_AHCP_ePT "Backup for network ECU config data for hybrid netw";
BA_ "GenSigSNA" SG_ 927 BU_NetCfg_APM_ePT "0h";
BA_ "GenSigSendType" SG_ 927 BU_NetCfg_APM_ePT 1;
BA_ "FlexKomSigStartValue" SG_ 927 BU_NetCfg_APM_ePT "030000h";
BA_ "FlexKomSigStartPos" SG_ 927 BU_NetCfg_APM_ePT 7;
BA_ "FlexKomSigName" SG_ 927 BU_NetCfg_APM_ePT "BU_NET_CFG_DATA_ePT";
BA_ "FlexKomSigLaenge" SG_ 927 BU_NetCfg_APM_ePT 24;
BA_ "FlexKomSID" SG_ 927 BU_NetCfg_APM_ePT 2470;
BA_ "FlexKomIsMotorola" SG_ 927 BU_NetCfg_APM_ePT 1;
BA_ "FlexKomComment" SG_ 927 BU_NetCfg_APM_ePT "Backup for network ECU config data for hybrid netw";
BA_ "GenSigSNA" SG_ 927 BU_NetCfg_BPCM_ePT "0h";
BA_ "GenSigSendType" SG_ 927 BU_NetCfg_BPCM_ePT 1;
BA_ "FlexKomSigStartValue" SG_ 927 BU_NetCfg_BPCM_ePT "030000h";
BA_ "FlexKomSigStartPos" SG_ 927 BU_NetCfg_BPCM_ePT 7;
BA_ "FlexKomSigName" SG_ 927 BU_NetCfg_BPCM_ePT "BU_NET_CFG_DATA_ePT";
BA_ "FlexKomSigLaenge" SG_ 927 BU_NetCfg_BPCM_ePT 24;
BA_ "FlexKomSID" SG_ 927 BU_NetCfg_BPCM_ePT 2470;
BA_ "FlexKomIsMotorola" SG_ 927 BU_NetCfg_BPCM_ePT 1;
BA_ "FlexKomComment" SG_ 927 BU_NetCfg_BPCM_ePT "Backup for network ECU config data for hybrid netw";
BA_ "GenSigSNA" SG_ 927 BU_NetCfg_BSMO_ePT "0h";
BA_ "GenSigSendType" SG_ 927 BU_NetCfg_BSMO_ePT 1;
BA_ "FlexKomSigStartValue" SG_ 927 BU_NetCfg_BSMO_ePT "030000h";
BA_ "FlexKomSigStartPos" SG_ 927 BU_NetCfg_BSMO_ePT 7;
BA_ "FlexKomSigName" SG_ 927 BU_NetCfg_BSMO_ePT "BU_NET_CFG_DATA_ePT";
BA_ "FlexKomSigLaenge" SG_ 927 BU_NetCfg_BSMO_ePT 24;
BA_ "FlexKomSID" SG_ 927 BU_NetCfg_BSMO_ePT 2470;
BA_ "FlexKomIsMotorola" SG_ 927 BU_NetCfg_BSMO_ePT 1;
BA_ "FlexKomComment" SG_ 927 BU_NetCfg_BSMO_ePT "Backup for network ECU config data for hybrid netw";
BA_ "GenSigSNA" SG_ 927 BU_NetCfg_EAC_ePT "0h";
BA_ "GenSigSendType" SG_ 927 BU_NetCfg_EAC_ePT 1;
BA_ "FlexKomSigStartValue" SG_ 927 BU_NetCfg_EAC_ePT "030000h";
BA_ "FlexKomSigStartPos" SG_ 927 BU_NetCfg_EAC_ePT 7;
BA_ "FlexKomSigName" SG_ 927 BU_NetCfg_EAC_ePT "BU_NET_CFG_DATA_ePT";
BA_ "FlexKomSigLaenge" SG_ 927 BU_NetCfg_EAC_ePT 24;
BA_ "FlexKomSID" SG_ 927 BU_NetCfg_EAC_ePT 2470;
BA_ "FlexKomIsMotorola" SG_ 927 BU_NetCfg_EAC_ePT 1;
BA_ "FlexKomComment" SG_ 927 BU_NetCfg_EAC_ePT "Backup for network ECU config data for hybrid netw";
BA_ "GenSigSNA" SG_ 927 BU_NetCfg_EBCM_ePT "0h";
BA_ "GenSigSendType" SG_ 927 BU_NetCfg_EBCM_ePT 1;
BA_ "FlexKomSigStartValue" SG_ 927 BU_NetCfg_EBCM_ePT "030000h";
BA_ "FlexKomSigStartPos" SG_ 927 BU_NetCfg_EBCM_ePT 7;
BA_ "FlexKomSigName" SG_ 927 BU_NetCfg_EBCM_ePT "BU_NET_CFG_DATA_ePT";
BA_ "FlexKomSigLaenge" SG_ 927 BU_NetCfg_EBCM_ePT 24;
BA_ "FlexKomSID" SG_ 927 BU_NetCfg_EBCM_ePT 2470;
BA_ "FlexKomIsMotorola" SG_ 927 BU_NetCfg_EBCM_ePT 1;
BA_ "FlexKomComment" SG_ 927 BU_NetCfg_EBCM_ePT "Backup for network ECU config data for hybrid netw";
BA_ "GenSigSNA" SG_ 927 BU_NetCfg_ECM_ePT "0h";
BA_ "GenSigSendType" SG_ 927 BU_NetCfg_ECM_ePT 1;
BA_ "FlexKomSigStartValue" SG_ 927 BU_NetCfg_ECM_ePT "030000h";
BA_ "FlexKomSigStartPos" SG_ 927 BU_NetCfg_ECM_ePT 7;
BA_ "FlexKomSigName" SG_ 927 BU_NetCfg_ECM_ePT "BU_NET_CFG_DATA_ePT";
BA_ "FlexKomSigLaenge" SG_ 927 BU_NetCfg_ECM_ePT 24;
BA_ "FlexKomSID" SG_ 927 BU_NetCfg_ECM_ePT 2470;
BA_ "FlexKomIsMotorola" SG_ 927 BU_NetCfg_ECM_ePT 1;
BA_ "FlexKomComment" SG_ 927 BU_NetCfg_ECM_ePT "Backup for network ECU config data for hybrid netw";
BA_ "GenSigSNA" SG_ 927 BU_NetCfg_ESC_ePT "0h";
BA_ "GenSigSendType" SG_ 927 BU_NetCfg_ESC_ePT 1;
BA_ "FlexKomSigStartValue" SG_ 927 BU_NetCfg_ESC_ePT "030000h";
BA_ "FlexKomSigStartPos" SG_ 927 BU_NetCfg_ESC_ePT 7;
BA_ "FlexKomSigName" SG_ 927 BU_NetCfg_ESC_ePT "BU_NET_CFG_DATA_ePT";
BA_ "FlexKomSigLaenge" SG_ 927 BU_NetCfg_ESC_ePT 24;
BA_ "FlexKomSID" SG_ 927 BU_NetCfg_ESC_ePT 2470;
BA_ "FlexKomIsMotorola" SG_ 927 BU_NetCfg_ESC_ePT 1;
BA_ "FlexKomComment" SG_ 927 BU_NetCfg_ESC_ePT "Backup for network ECU config data for hybrid netw";
BA_ "GenSigSNA" SG_ 927 BU_NetCfg_ESM_ePT "0h";
BA_ "GenSigSendType" SG_ 927 BU_NetCfg_ESM_ePT 1;
BA_ "FlexKomSigStartValue" SG_ 927 BU_NetCfg_ESM_ePT "030000h";
BA_ "FlexKomSigStartPos" SG_ 927 BU_NetCfg_ESM_ePT 7;
BA_ "FlexKomSigName" SG_ 927 BU_NetCfg_ESM_ePT "BU_NET_CFG_DATA_ePT";
BA_ "FlexKomSigLaenge" SG_ 927 BU_NetCfg_ESM_ePT 24;
BA_ "FlexKomSID" SG_ 927 BU_NetCfg_ESM_ePT 2470;
BA_ "FlexKomIsMotorola" SG_ 927 BU_NetCfg_ESM_ePT 1;
BA_ "FlexKomComment" SG_ 927 BU_NetCfg_ESM_ePT "Backup for network ECU config data for hybrid netw";
BA_ "GenSigSNA" SG_ 927 BU_NetCfg_HCP_ePT "0h";
BA_ "GenSigSendType" SG_ 927 BU_NetCfg_HCP_ePT 1;
BA_ "FlexKomSigStartValue" SG_ 927 BU_NetCfg_HCP_ePT "030000h";
BA_ "FlexKomSigStartPos" SG_ 927 BU_NetCfg_HCP_ePT 7;
BA_ "FlexKomSigName" SG_ 927 BU_NetCfg_HCP_ePT "BU_NET_CFG_DATA_ePT";
BA_ "FlexKomSigLaenge" SG_ 927 BU_NetCfg_HCP_ePT 24;
BA_ "FlexKomSID" SG_ 927 BU_NetCfg_HCP_ePT 2470;
BA_ "FlexKomIsMotorola" SG_ 927 BU_NetCfg_HCP_ePT 1;
BA_ "FlexKomComment" SG_ 927 BU_NetCfg_HCP_ePT "Backup for network ECU config data for hybrid netw";
BA_ "GenSigSNA" SG_ 927 BU_NetCfg_IDCM_ePT "0h";
BA_ "GenSigSendType" SG_ 927 BU_NetCfg_IDCM_ePT 1;
BA_ "FlexKomSigStartValue" SG_ 927 BU_NetCfg_IDCM_ePT "030000h";
BA_ "FlexKomSigStartPos" SG_ 927 BU_NetCfg_IDCM_ePT 7;
BA_ "FlexKomSigName" SG_ 927 BU_NetCfg_IDCM_ePT "BU_NET_CFG_DATA_ePT";
BA_ "FlexKomSigLaenge" SG_ 927 BU_NetCfg_IDCM_ePT 24;
BA_ "FlexKomSID" SG_ 927 BU_NetCfg_IDCM_ePT 2470;
BA_ "FlexKomIsMotorola" SG_ 927 BU_NetCfg_IDCM_ePT 1;
BA_ "FlexKomComment" SG_ 927 BU_NetCfg_IDCM_ePT "Backup for network ECU config data for hybrid netw";
BA_ "GenSigSNA" SG_ 927 BU_NetCfg_MCPA_ePT "0h";
BA_ "GenSigSendType" SG_ 927 BU_NetCfg_MCPA_ePT 1;
BA_ "FlexKomSigStartValue" SG_ 927 BU_NetCfg_MCPA_ePT "030000h";
BA_ "FlexKomSigStartPos" SG_ 927 BU_NetCfg_MCPA_ePT 7;
BA_ "FlexKomSigName" SG_ 927 BU_NetCfg_MCPA_ePT "BU_NET_CFG_DATA_ePT";
BA_ "FlexKomSigLaenge" SG_ 927 BU_NetCfg_MCPA_ePT 24;
BA_ "FlexKomSID" SG_ 927 BU_NetCfg_MCPA_ePT 2470;
BA_ "FlexKomIsMotorola" SG_ 927 BU_NetCfg_MCPA_ePT 1;
BA_ "FlexKomComment" SG_ 927 BU_NetCfg_MCPA_ePT "Backup for network ECU config data for hybrid netw";
BA_ "GenSigSNA" SG_ 927 BU_NetCfg_OBCM_ePT "0h";
BA_ "GenSigSendType" SG_ 927 BU_NetCfg_OBCM_ePT 1;
BA_ "FlexKomSigStartValue" SG_ 927 BU_NetCfg_OBCM_ePT "030000h";
BA_ "FlexKomSigStartPos" SG_ 927 BU_NetCfg_OBCM_ePT 7;
BA_ "FlexKomSigName" SG_ 927 BU_NetCfg_OBCM_ePT "BU_NET_CFG_DATA_ePT";
BA_ "FlexKomSigLaenge" SG_ 927 BU_NetCfg_OBCM_ePT 24;
BA_ "FlexKomSID" SG_ 927 BU_NetCfg_OBCM_ePT 2470;
BA_ "FlexKomIsMotorola" SG_ 927 BU_NetCfg_OBCM_ePT 1;
BA_ "FlexKomComment" SG_ 927 BU_NetCfg_OBCM_ePT "Backup for network ECU config data for hybrid netw";
BA_ "GenSigSNA" SG_ 927 BU_NetCfg_ORC_ePT "0h";
BA_ "GenSigSendType" SG_ 927 BU_NetCfg_ORC_ePT 1;
BA_ "FlexKomSigStartValue" SG_ 927 BU_NetCfg_ORC_ePT "030000h";
BA_ "FlexKomSigStartPos" SG_ 927 BU_NetCfg_ORC_ePT 7;
BA_ "FlexKomSigName" SG_ 927 BU_NetCfg_ORC_ePT "BU_NET_CFG_DATA_ePT";
BA_ "FlexKomSigLaenge" SG_ 927 BU_NetCfg_ORC_ePT 24;
BA_ "FlexKomSID" SG_ 927 BU_NetCfg_ORC_ePT 2470;
BA_ "FlexKomIsMotorola" SG_ 927 BU_NetCfg_ORC_ePT 1;
BA_ "FlexKomComment" SG_ 927 BU_NetCfg_ORC_ePT "Backup for network ECU config data for hybrid netw";
BA_ "GenSigSNA" SG_ 927 BU_NetCfg_SCA_ePT "0h";
BA_ "GenSigSendType" SG_ 927 BU_NetCfg_SCA_ePT 1;
BA_ "FlexKomSigStartValue" SG_ 927 BU_NetCfg_SCA_ePT "030000h";
BA_ "FlexKomSigStartPos" SG_ 927 BU_NetCfg_SCA_ePT 7;
BA_ "FlexKomSigName" SG_ 927 BU_NetCfg_SCA_ePT "BU_NET_CFG_DATA_ePT";
BA_ "FlexKomSigLaenge" SG_ 927 BU_NetCfg_SCA_ePT 24;
BA_ "FlexKomSID" SG_ 927 BU_NetCfg_SCA_ePT 2470;
BA_ "FlexKomIsMotorola" SG_ 927 BU_NetCfg_SCA_ePT 1;
BA_ "FlexKomComment" SG_ 927 BU_NetCfg_SCA_ePT "Backup for network ECU config data for hybrid netw";
BA_ "GenSigTimeout_IC" SG_ 937 DRL_ON 10500;
BA_ "GenSigSNA" SG_ 937 DRL_ON "0h";
BA_ "GenSigSendType" SG_ 937 DRL_ON 5;
BA_ "GenSigCycleTime" SG_ 937 DRL_ON 1000;
BA_ "FlexKomSigStartValue" SG_ 937 DRL_ON "00FFFFFFFF60h";
BA_ "FlexKomSigStartPos" SG_ 937 DRL_ON 7;
BA_ "FlexKomSigName" SG_ 937 DRL_ON "CBC_CFG_STAT";
BA_ "FlexKomSigLaenge" SG_ 937 DRL_ON 48;
BA_ "FlexKomSID" SG_ 937 DRL_ON 843;
BA_ "FlexKomIsMotorola" SG_ 937 DRL_ON 1;
BA_ "FlexKomComment" SG_ 937 DRL_ON "Configuration status CBC";
BA_ "GenSigTimeout_IC" SG_ 937 FLASH_LK 10500;
BA_ "GenSigSNA" SG_ 937 FLASH_LK "0h";
BA_ "GenSigSendType" SG_ 937 FLASH_LK 5;
BA_ "GenSigCycleTime" SG_ 937 FLASH_LK 1000;
BA_ "FlexKomSigStartValue" SG_ 937 FLASH_LK "00FFFFFFFF60h";
BA_ "FlexKomSigStartPos" SG_ 937 FLASH_LK 7;
BA_ "FlexKomSigName" SG_ 937 FLASH_LK "CBC_CFG_STAT";
BA_ "FlexKomSigLaenge" SG_ 937 FLASH_LK 48;
BA_ "FlexKomSID" SG_ 937 FLASH_LK 843;
BA_ "FlexKomIsMotorola" SG_ 937 FLASH_LK 1;
BA_ "FlexKomComment" SG_ 937 FLASH_LK "Configuration status CBC";
BA_ "GenSigTimeout_IC" SG_ 937 HL_DLY_TIME 10500;
BA_ "GenSigStartValue" SG_ 937 HL_DLY_TIME 255;
BA_ "GenSigSNA" SG_ 937 HL_DLY_TIME "FFh";
BA_ "GenSigSendType" SG_ 937 HL_DLY_TIME 5;
BA_ "GenSigCycleTime" SG_ 937 HL_DLY_TIME 1000;
BA_ "FlexKomSigStartValue" SG_ 937 HL_DLY_TIME "00FFFFFFFF60h";
BA_ "FlexKomSigStartPos" SG_ 937 HL_DLY_TIME 7;
BA_ "FlexKomSigName" SG_ 937 HL_DLY_TIME "CBC_CFG_STAT";
BA_ "FlexKomSigLaenge" SG_ 937 HL_DLY_TIME 48;
BA_ "FlexKomSID" SG_ 937 HL_DLY_TIME 843;
BA_ "FlexKomIsMotorola" SG_ 937 HL_DLY_TIME 1;
BA_ "FlexKomComment" SG_ 937 HL_DLY_TIME "Configuration status CBC";
BA_ "GenSigTimeout_IC" SG_ 937 HL_WPR 10500;
BA_ "GenSigSNA" SG_ 937 HL_WPR "0h";
BA_ "GenSigSendType" SG_ 937 HL_WPR 5;
BA_ "GenSigCycleTime" SG_ 937 HL_WPR 1000;
BA_ "FlexKomSigStartValue" SG_ 937 HL_WPR "00FFFFFFFF60h";
BA_ "FlexKomSigStartPos" SG_ 937 HL_WPR 7;
BA_ "FlexKomSigName" SG_ 937 HL_WPR "CBC_CFG_STAT";
BA_ "FlexKomSigLaenge" SG_ 937 HL_WPR 48;
BA_ "FlexKomSID" SG_ 937 HL_WPR 843;
BA_ "FlexKomIsMotorola" SG_ 937 HL_WPR 1;
BA_ "FlexKomComment" SG_ 937 HL_WPR "Configuration status CBC";
BA_ "GenSigTimeout_IC" SG_ 937 ILL_APRCH_TIME 10500;
BA_ "GenSigStartValue" SG_ 937 ILL_APRCH_TIME 255;
BA_ "GenSigSNA" SG_ 937 ILL_APRCH_TIME "FFh";
BA_ "GenSigSendType" SG_ 937 ILL_APRCH_TIME 5;
BA_ "GenSigCycleTime" SG_ 937 ILL_APRCH_TIME 1000;
BA_ "FlexKomSigStartValue" SG_ 937 ILL_APRCH_TIME "00FFFFFFFF60h";
BA_ "FlexKomSigStartPos" SG_ 937 ILL_APRCH_TIME 7;
BA_ "FlexKomSigName" SG_ 937 ILL_APRCH_TIME "CBC_CFG_STAT";
BA_ "FlexKomSigLaenge" SG_ 937 ILL_APRCH_TIME 48;
BA_ "FlexKomSID" SG_ 937 ILL_APRCH_TIME 843;
BA_ "FlexKomIsMotorola" SG_ 937 ILL_APRCH_TIME 1;
BA_ "FlexKomComment" SG_ 937 ILL_APRCH_TIME "Configuration status CBC";
BA_ "GenSigTimeout_IC" SG_ 937 SOUND_LK 10500;
BA_ "GenSigSNA" SG_ 937 SOUND_LK "0h";
BA_ "GenSigSendType" SG_ 937 SOUND_LK 5;
BA_ "GenSigCycleTime" SG_ 937 SOUND_LK 1000;
BA_ "FlexKomSigStartValue" SG_ 937 SOUND_LK "00FFFFFFFF60h";
BA_ "FlexKomSigStartPos" SG_ 937 SOUND_LK 7;
BA_ "FlexKomSigName" SG_ 937 SOUND_LK "CBC_CFG_STAT";
BA_ "FlexKomSigLaenge" SG_ 937 SOUND_LK 48;
BA_ "FlexKomSID" SG_ 937 SOUND_LK 843;
BA_ "FlexKomIsMotorola" SG_ 937 SOUND_LK 1;
BA_ "FlexKomComment" SG_ 937 SOUND_LK "Configuration status CBC";
BA_ "GenSigTimeout_IC" SG_ 937 SOUND_LK_1ST_2ND 10500;
BA_ "GenSigStartValue" SG_ 937 SOUND_LK_1ST_2ND 3;
BA_ "GenSigSNA" SG_ 937 SOUND_LK_1ST_2ND "3h";
BA_ "GenSigSendType" SG_ 937 SOUND_LK_1ST_2ND 5;
BA_ "GenSigCycleTime" SG_ 937 SOUND_LK_1ST_2ND 1000;
BA_ "FlexKomSigStartValue" SG_ 937 SOUND_LK_1ST_2ND "03h";
BA_ "FlexKomSigStartPos" SG_ 937 SOUND_LK_1ST_2ND 57;
BA_ "FlexKomSigName" SG_ 937 SOUND_LK_1ST_2ND "SOUND_LK_1ST_2ND";
BA_ "FlexKomSigLaenge" SG_ 937 SOUND_LK_1ST_2ND 2;
BA_ "FlexKomSID" SG_ 937 SOUND_LK_1ST_2ND 1956;
BA_ "FlexKomIsMotorola" SG_ 937 SOUND_LK_1ST_2ND 1;
BA_ "FlexKomComment" SG_ 937 SOUND_LK_1ST_2ND "Sound horn on lock status";
BA_ "GenSigTimeout_IC" SG_ 937 SOUND_RS 10500;
BA_ "GenSigSNA" SG_ 937 SOUND_RS "0h";
BA_ "GenSigSendType" SG_ 937 SOUND_RS 5;
BA_ "GenSigCycleTime" SG_ 937 SOUND_RS 1000;
BA_ "FlexKomSigStartValue" SG_ 937 SOUND_RS "00h";
BA_ "FlexKomSigStartPos" SG_ 937 SOUND_RS 52;
BA_ "FlexKomSigName" SG_ 937 SOUND_RS "SOUND_RS";
BA_ "FlexKomSigLaenge" SG_ 937 SOUND_RS 1;
BA_ "FlexKomSID" SG_ 937 SOUND_RS 966;
BA_ "FlexKomIsMotorola" SG_ 937 SOUND_RS 1;
BA_ "FlexKomComment" SG_ 937 SOUND_RS "Sound horn on Remote Start ; no = [0], yes = [1]";
BA_ "GenSigTimeout_IC" SG_ 685 CBC_AUX1_HLEnbl 10500;
BA_ "GenSigSNA" SG_ 685 CBC_AUX1_HLEnbl "0h";
BA_ "GenSigSendType" SG_ 685 CBC_AUX1_HLEnbl 5;
BA_ "GenSigCycleTime" SG_ 685 CBC_AUX1_HLEnbl 1000;
BA_ "FlexKomSigStartValue" SG_ 685 CBC_AUX1_HLEnbl "000007000000FFFFh";
BA_ "FlexKomSigStartPos" SG_ 685 CBC_AUX1_HLEnbl 7;
BA_ "FlexKomSigName" SG_ 685 CBC_AUX1_HLEnbl "CBC_Cfg2_Pkt";
BA_ "FlexKomSigLaenge" SG_ 685 CBC_AUX1_HLEnbl 64;
BA_ "FlexKomSID" SG_ 685 CBC_AUX1_HLEnbl 1957;
BA_ "FlexKomIsMotorola" SG_ 685 CBC_AUX1_HLEnbl 1;
BA_ "FlexKomComment" SG_ 685 CBC_AUX1_HLEnbl "Configuration status CBC 2";
BA_ "GenSigTimeout_IC" SG_ 685 CBC_AUX1_PWRMD 10500;
BA_ "GenSigSNA" SG_ 685 CBC_AUX1_PWRMD "0h";
BA_ "GenSigSendType" SG_ 685 CBC_AUX1_PWRMD 5;
BA_ "GenSigCycleTime" SG_ 685 CBC_AUX1_PWRMD 1000;
BA_ "FlexKomSigStartValue" SG_ 685 CBC_AUX1_PWRMD "000007000000FFFFh";
BA_ "FlexKomSigStartPos" SG_ 685 CBC_AUX1_PWRMD 7;
BA_ "FlexKomSigName" SG_ 685 CBC_AUX1_PWRMD "CBC_Cfg2_Pkt";
BA_ "FlexKomSigLaenge" SG_ 685 CBC_AUX1_PWRMD 64;
BA_ "FlexKomSID" SG_ 685 CBC_AUX1_PWRMD 1957;
BA_ "FlexKomIsMotorola" SG_ 685 CBC_AUX1_PWRMD 1;
BA_ "FlexKomComment" SG_ 685 CBC_AUX1_PWRMD "Configuration status CBC 2";
BA_ "GenSigTimeout_IC" SG_ 685 CBC_AUX1_Type 10500;
BA_ "GenSigSNA" SG_ 685 CBC_AUX1_Type "0h";
BA_ "GenSigSendType" SG_ 685 CBC_AUX1_Type 5;
BA_ "GenSigCycleTime" SG_ 685 CBC_AUX1_Type 1000;
BA_ "FlexKomSigStartValue" SG_ 685 CBC_AUX1_Type "000007000000FFFFh";
BA_ "FlexKomSigStartPos" SG_ 685 CBC_AUX1_Type 7;
BA_ "FlexKomSigName" SG_ 685 CBC_AUX1_Type "CBC_Cfg2_Pkt";
BA_ "FlexKomSigLaenge" SG_ 685 CBC_AUX1_Type 64;
BA_ "FlexKomSID" SG_ 685 CBC_AUX1_Type 1957;
BA_ "FlexKomIsMotorola" SG_ 685 CBC_AUX1_Type 1;
BA_ "FlexKomComment" SG_ 685 CBC_AUX1_Type "Configuration status CBC 2";
BA_ "GenSigTimeout_IC" SG_ 685 CBC_AUX2_HLEnbl 10500;
BA_ "GenSigSNA" SG_ 685 CBC_AUX2_HLEnbl "0h";
BA_ "GenSigSendType" SG_ 685 CBC_AUX2_HLEnbl 5;
BA_ "GenSigCycleTime" SG_ 685 CBC_AUX2_HLEnbl 1000;
BA_ "FlexKomSigStartValue" SG_ 685 CBC_AUX2_HLEnbl "000007000000FFFFh";
BA_ "FlexKomSigStartPos" SG_ 685 CBC_AUX2_HLEnbl 7;
BA_ "FlexKomSigName" SG_ 685 CBC_AUX2_HLEnbl "CBC_Cfg2_Pkt";
BA_ "FlexKomSigLaenge" SG_ 685 CBC_AUX2_HLEnbl 64;
BA_ "FlexKomSID" SG_ 685 CBC_AUX2_HLEnbl 1957;
BA_ "FlexKomIsMotorola" SG_ 685 CBC_AUX2_HLEnbl 1;
BA_ "FlexKomComment" SG_ 685 CBC_AUX2_HLEnbl "Configuration status CBC 2";
BA_ "GenSigTimeout_IC" SG_ 685 CBC_AUX2_PWRMD 10500;
BA_ "GenSigSNA" SG_ 685 CBC_AUX2_PWRMD "0h";
BA_ "GenSigSendType" SG_ 685 CBC_AUX2_PWRMD 5;
BA_ "GenSigCycleTime" SG_ 685 CBC_AUX2_PWRMD 1000;
BA_ "FlexKomSigStartValue" SG_ 685 CBC_AUX2_PWRMD "000007000000FFFFh";
BA_ "FlexKomSigStartPos" SG_ 685 CBC_AUX2_PWRMD 7;
BA_ "FlexKomSigName" SG_ 685 CBC_AUX2_PWRMD "CBC_Cfg2_Pkt";
BA_ "FlexKomSigLaenge" SG_ 685 CBC_AUX2_PWRMD 64;
BA_ "FlexKomSID" SG_ 685 CBC_AUX2_PWRMD 1957;
BA_ "FlexKomIsMotorola" SG_ 685 CBC_AUX2_PWRMD 1;
BA_ "FlexKomComment" SG_ 685 CBC_AUX2_PWRMD "Configuration status CBC 2";
BA_ "GenSigTimeout_IC" SG_ 685 CBC_AUX2_Type 10500;
BA_ "GenSigSNA" SG_ 685 CBC_AUX2_Type "0h";
BA_ "GenSigSendType" SG_ 685 CBC_AUX2_Type 5;
BA_ "GenSigCycleTime" SG_ 685 CBC_AUX2_Type 1000;
BA_ "FlexKomSigStartValue" SG_ 685 CBC_AUX2_Type "000007000000FFFFh";
BA_ "FlexKomSigStartPos" SG_ 685 CBC_AUX2_Type 7;
BA_ "FlexKomSigName" SG_ 685 CBC_AUX2_Type "CBC_Cfg2_Pkt";
BA_ "FlexKomSigLaenge" SG_ 685 CBC_AUX2_Type 64;
BA_ "FlexKomSID" SG_ 685 CBC_AUX2_Type 1957;
BA_ "FlexKomIsMotorola" SG_ 685 CBC_AUX2_Type 1;
BA_ "FlexKomComment" SG_ 685 CBC_AUX2_Type "Configuration status CBC 2";
BA_ "GenSigTimeout_IC" SG_ 685 CBC_AUX3_HLEnbl 10500;
BA_ "GenSigSNA" SG_ 685 CBC_AUX3_HLEnbl "0h";
BA_ "GenSigSendType" SG_ 685 CBC_AUX3_HLEnbl 5;
BA_ "GenSigCycleTime" SG_ 685 CBC_AUX3_HLEnbl 1000;
BA_ "FlexKomSigStartValue" SG_ 685 CBC_AUX3_HLEnbl "000007000000FFFFh";
BA_ "FlexKomSigStartPos" SG_ 685 CBC_AUX3_HLEnbl 7;
BA_ "FlexKomSigName" SG_ 685 CBC_AUX3_HLEnbl "CBC_Cfg2_Pkt";
BA_ "FlexKomSigLaenge" SG_ 685 CBC_AUX3_HLEnbl 64;
BA_ "FlexKomSID" SG_ 685 CBC_AUX3_HLEnbl 1957;
BA_ "FlexKomIsMotorola" SG_ 685 CBC_AUX3_HLEnbl 1;
BA_ "FlexKomComment" SG_ 685 CBC_AUX3_HLEnbl "Configuration status CBC 2";
BA_ "GenSigTimeout_IC" SG_ 685 CBC_AUX3_PWRMD 10500;
BA_ "GenSigSNA" SG_ 685 CBC_AUX3_PWRMD "0h";
BA_ "GenSigSendType" SG_ 685 CBC_AUX3_PWRMD 5;
BA_ "GenSigCycleTime" SG_ 685 CBC_AUX3_PWRMD 1000;
BA_ "FlexKomSigStartValue" SG_ 685 CBC_AUX3_PWRMD "000007000000FFFFh";
BA_ "FlexKomSigStartPos" SG_ 685 CBC_AUX3_PWRMD 7;
BA_ "FlexKomSigName" SG_ 685 CBC_AUX3_PWRMD "CBC_Cfg2_Pkt";
BA_ "FlexKomSigLaenge" SG_ 685 CBC_AUX3_PWRMD 64;
BA_ "FlexKomSID" SG_ 685 CBC_AUX3_PWRMD 1957;
BA_ "FlexKomIsMotorola" SG_ 685 CBC_AUX3_PWRMD 1;
BA_ "FlexKomComment" SG_ 685 CBC_AUX3_PWRMD "Configuration status CBC 2";
BA_ "GenSigTimeout_IC" SG_ 685 CBC_AUX3_Type 10500;
BA_ "GenSigSNA" SG_ 685 CBC_AUX3_Type "0h";
BA_ "GenSigSendType" SG_ 685 CBC_AUX3_Type 5;
BA_ "GenSigCycleTime" SG_ 685 CBC_AUX3_Type 1000;
BA_ "FlexKomSigStartValue" SG_ 685 CBC_AUX3_Type "000007000000FFFFh";
BA_ "FlexKomSigStartPos" SG_ 685 CBC_AUX3_Type 7;
BA_ "FlexKomSigName" SG_ 685 CBC_AUX3_Type "CBC_Cfg2_Pkt";
BA_ "FlexKomSigLaenge" SG_ 685 CBC_AUX3_Type 64;
BA_ "FlexKomSID" SG_ 685 CBC_AUX3_Type 1957;
BA_ "FlexKomIsMotorola" SG_ 685 CBC_AUX3_Type 1;
BA_ "FlexKomComment" SG_ 685 CBC_AUX3_Type "Configuration status CBC 2";
BA_ "GenSigTimeout_IC" SG_ 685 CBC_AUX4_HLEnbl 10500;
BA_ "GenSigSNA" SG_ 685 CBC_AUX4_HLEnbl "0h";
BA_ "GenSigSendType" SG_ 685 CBC_AUX4_HLEnbl 5;
BA_ "GenSigCycleTime" SG_ 685 CBC_AUX4_HLEnbl 1000;
BA_ "FlexKomSigStartValue" SG_ 685 CBC_AUX4_HLEnbl "000007000000FFFFh";
BA_ "FlexKomSigStartPos" SG_ 685 CBC_AUX4_HLEnbl 7;
BA_ "FlexKomSigName" SG_ 685 CBC_AUX4_HLEnbl "CBC_Cfg2_Pkt";
BA_ "FlexKomSigLaenge" SG_ 685 CBC_AUX4_HLEnbl 64;
BA_ "FlexKomSID" SG_ 685 CBC_AUX4_HLEnbl 1957;
BA_ "FlexKomIsMotorola" SG_ 685 CBC_AUX4_HLEnbl 1;
BA_ "FlexKomComment" SG_ 685 CBC_AUX4_HLEnbl "Configuration status CBC 2";
BA_ "GenSigTimeout_IC" SG_ 685 CBC_AUX4_PWRMD 10500;
BA_ "GenSigSNA" SG_ 685 CBC_AUX4_PWRMD "0h";
BA_ "GenSigSendType" SG_ 685 CBC_AUX4_PWRMD 5;
BA_ "GenSigCycleTime" SG_ 685 CBC_AUX4_PWRMD 1000;
BA_ "FlexKomSigStartValue" SG_ 685 CBC_AUX4_PWRMD "000007000000FFFFh";
BA_ "FlexKomSigStartPos" SG_ 685 CBC_AUX4_PWRMD 7;
BA_ "FlexKomSigName" SG_ 685 CBC_AUX4_PWRMD "CBC_Cfg2_Pkt";
BA_ "FlexKomSigLaenge" SG_ 685 CBC_AUX4_PWRMD 64;
BA_ "FlexKomSID" SG_ 685 CBC_AUX4_PWRMD 1957;
BA_ "FlexKomIsMotorola" SG_ 685 CBC_AUX4_PWRMD 1;
BA_ "FlexKomComment" SG_ 685 CBC_AUX4_PWRMD "Configuration status CBC 2";
BA_ "GenSigTimeout_IC" SG_ 685 CBC_AUX4_Type 10500;
BA_ "GenSigSNA" SG_ 685 CBC_AUX4_Type "0h";
BA_ "GenSigSendType" SG_ 685 CBC_AUX4_Type 5;
BA_ "GenSigCycleTime" SG_ 685 CBC_AUX4_Type 1000;
BA_ "FlexKomSigStartValue" SG_ 685 CBC_AUX4_Type "000007000000FFFFh";
BA_ "FlexKomSigStartPos" SG_ 685 CBC_AUX4_Type 7;
BA_ "FlexKomSigName" SG_ 685 CBC_AUX4_Type "CBC_Cfg2_Pkt";
BA_ "FlexKomSigLaenge" SG_ 685 CBC_AUX4_Type 64;
BA_ "FlexKomSID" SG_ 685 CBC_AUX4_Type 1957;
BA_ "FlexKomIsMotorola" SG_ 685 CBC_AUX4_Type 1;
BA_ "FlexKomComment" SG_ 685 CBC_AUX4_Type "Configuration status CBC 2";
BA_ "GenSigTimeout_IC" SG_ 685 Cfg_Aux_PTO 10500;
BA_ "GenSigStartValue" SG_ 685 Cfg_Aux_PTO 7;
BA_ "GenSigSNA" SG_ 685 Cfg_Aux_PTO "7h";
BA_ "GenSigSendType" SG_ 685 Cfg_Aux_PTO 5;
BA_ "GenSigCycleTime" SG_ 685 Cfg_Aux_PTO 1000;
BA_ "FlexKomSigStartValue" SG_ 685 Cfg_Aux_PTO "000007000000FFFFh";
BA_ "FlexKomSigStartPos" SG_ 685 Cfg_Aux_PTO 7;
BA_ "FlexKomSigName" SG_ 685 Cfg_Aux_PTO "CBC_Cfg2_Pkt";
BA_ "FlexKomSigLaenge" SG_ 685 Cfg_Aux_PTO 64;
BA_ "FlexKomSID" SG_ 685 Cfg_Aux_PTO 1957;
BA_ "FlexKomIsMotorola" SG_ 685 Cfg_Aux_PTO 1;
BA_ "FlexKomComment" SG_ 685 Cfg_Aux_PTO "Configuration status CBC 2";
BA_ "RID" SG_ 657 AHB_ACT "971";
BA_ "GenSigTimeout_IC" SG_ 657 AHB_ACT 10500;
BA_ "GenSigSNA" SG_ 657 AHB_ACT "0h";
BA_ "GenSigSendType" SG_ 657 AHB_ACT 5;
BA_ "GenSigCycleTime" SG_ 657 AHB_ACT 1000;
BA_ "FlexKomSigStartValue" SG_ 657 AHB_ACT "00h";
BA_ "FlexKomSigStartPos" SG_ 657 AHB_ACT 14;
BA_ "FlexKomSigName" SG_ 657 AHB_ACT "AHB_ACT";
BA_ "FlexKomSigLaenge" SG_ 657 AHB_ACT 1;
BA_ "FlexKomSID" SG_ 657 AHB_ACT 732;
BA_ "FlexKomIsMotorola" SG_ 657 AHB_ACT 1;
BA_ "FlexKomComment" SG_ 657 AHB_ACT "Automatic high beam active";
BA_ "GenSigTimeout_TBM" SG_ 657 BRK_FLUID_LO 10500;
BA_ "GenSigTimeout_IC" SG_ 657 BRK_FLUID_LO 10500;
BA_ "GenSigTimeout_ETM" SG_ 657 BRK_FLUID_LO 10500;
BA_ "GenSigSNA" SG_ 657 BRK_FLUID_LO "0h";
BA_ "GenSigSendType" SG_ 657 BRK_FLUID_LO 5;
BA_ "GenSigCycleTime" SG_ 657 BRK_FLUID_LO 1000;
BA_ "FlexKomSigStartValue" SG_ 657 BRK_FLUID_LO "00h";
BA_ "FlexKomSigStartPos" SG_ 657 BRK_FLUID_LO 62;
BA_ "FlexKomSigName" SG_ 657 BRK_FLUID_LO "BRK_FLUID_LO";
BA_ "FlexKomSigLaenge" SG_ 657 BRK_FLUID_LO 1;
BA_ "FlexKomSID" SG_ 657 BRK_FLUID_LO 885;
BA_ "FlexKomIsMotorola" SG_ 657 BRK_FLUID_LO 1;
BA_ "FlexKomComment" SG_ 657 BRK_FLUID_LO "Low brake fluid warning; low = [1]";
BA_ "GenSigTimeout_SCCM" SG_ 657 DAY_LGT_MD 10500;
BA_ "GenSigTimeout_RF_HUB" SG_ 657 DAY_LGT_MD 10500;
BA_ "GenSigTimeout_IC" SG_ 657 DAY_LGT_MD 10500;
BA_ "GenSigTimeout_ESM" SG_ 657 DAY_LGT_MD 10500;
BA_ "GenSigSNA" SG_ 657 DAY_LGT_MD "0h";
BA_ "GenSigSendType" SG_ 657 DAY_LGT_MD 5;
BA_ "GenSigCycleTime" SG_ 657 DAY_LGT_MD 1000;
BA_ "FlexKomSigStartValue" SG_ 657 DAY_LGT_MD "000000h";
BA_ "FlexKomSigStartPos" SG_ 657 DAY_LGT_MD 47;
BA_ "FlexKomSigName" SG_ 657 DAY_LGT_MD "IntLtSt_PT";
BA_ "FlexKomSigLaenge" SG_ 657 DAY_LGT_MD 24;
BA_ "FlexKomSID" SG_ 657 DAY_LGT_MD 1417;
BA_ "FlexKomIsMotorola" SG_ 657 DAY_LGT_MD 1;
BA_ "FlexKomComment" SG_ 657 DAY_LGT_MD "Interior lighting status powertrain";
BA_ "GenSigTimeout_TBM" SG_ 657 DRV_AJAR 10500;
BA_ "GenSigTimeout_RF_HUB" SG_ 657 DRV_AJAR 10500;
BA_ "GenSigTimeout_IC" SG_ 657 DRV_AJAR 10500;
BA_ "GenSigSNA" SG_ 657 DRV_AJAR "0h";
BA_ "GenSigSendType" SG_ 657 DRV_AJAR 5;
BA_ "GenSigCycleTime" SG_ 657 DRV_AJAR 1000;
BA_ "FlexKomSigStartValue" SG_ 657 DRV_AJAR "00h";
BA_ "FlexKomSigStartPos" SG_ 657 DRV_AJAR 22;
BA_ "FlexKomSigName" SG_ 657 DRV_AJAR "DR_AJAR";
BA_ "FlexKomSigLaenge" SG_ 657 DRV_AJAR 6;
BA_ "FlexKomSID" SG_ 657 DRV_AJAR 797;
BA_ "FlexKomIsMotorola" SG_ 657 DRV_AJAR 1;
BA_ "FlexKomComment" SG_ 657 DRV_AJAR "Door ajar";
BA_ "GenSigTimeout_RF_HUB" SG_ 657 DR_LK_STAT 10500;
BA_ "GenSigTimeout_IC" SG_ 657 DR_LK_STAT 10500;
BA_ "GenSigStartValue" SG_ 657 DR_LK_STAT 3;
BA_ "GenSigSNA" SG_ 657 DR_LK_STAT "3h";
BA_ "GenSigSendType" SG_ 657 DR_LK_STAT 5;
BA_ "GenSigCycleTime" SG_ 657 DR_LK_STAT 1000;
BA_ "FlexKomSigStartValue" SG_ 657 DR_LK_STAT "03h";
BA_ "FlexKomSigStartPos" SG_ 657 DR_LK_STAT 6;
BA_ "FlexKomSigName" SG_ 657 DR_LK_STAT "DR_LK_STAT";
BA_ "FlexKomSigLaenge" SG_ 657 DR_LK_STAT 2;
BA_ "FlexKomSID" SG_ 657 DR_LK_STAT 861;
BA_ "FlexKomIsMotorola" SG_ 657 DR_LK_STAT 1;
BA_ "FlexKomComment" SG_ 657 DR_LK_STAT "Door lock status";
BA_ "GenSigTimeout_RF_HUB" SG_ 657 FOB_SrchRq 5500;
BA_ "GenSigSNA" SG_ 657 FOB_SrchRq "0h";
BA_ "GenSigSendType" SG_ 657 FOB_SrchRq 5;
BA_ "GenSigCycleTime" SG_ 657 FOB_SrchRq 1000;
BA_ "FlexKomSigStartValue" SG_ 657 FOB_SrchRq "00h";
BA_ "FlexKomSigStartPos" SG_ 657 FOB_SrchRq 9;
BA_ "FlexKomSigName" SG_ 657 FOB_SrchRq "FOB_SrchRq";
BA_ "FlexKomSigLaenge" SG_ 657 FOB_SrchRq 2;
BA_ "FlexKomSID" SG_ 657 FOB_SrchRq 1392;
BA_ "FlexKomIsMotorola" SG_ 657 FOB_SrchRq 1;
BA_ "FlexKomComment" SG_ 657 FOB_SrchRq "FOB search request";
BA_ "GenSigTimeout_IC" SG_ 657 FT_FOG_RQ 10500;
BA_ "GenSigSNA" SG_ 657 FT_FOG_RQ "0h";
BA_ "GenSigSendType" SG_ 657 FT_FOG_RQ 5;
BA_ "GenSigCycleTime" SG_ 657 FT_FOG_RQ 1000;
BA_ "FlexKomSigStartValue" SG_ 657 FT_FOG_RQ "00h";
BA_ "FlexKomSigStartPos" SG_ 657 FT_FOG_RQ 2;
BA_ "FlexKomSigName" SG_ 657 FT_FOG_RQ "FT_FOG_RQ";
BA_ "FlexKomSigLaenge" SG_ 657 FT_FOG_RQ 1;
BA_ "FlexKomSID" SG_ 657 FT_FOG_RQ 758;
BA_ "FlexKomIsMotorola" SG_ 657 FT_FOG_RQ 1;
BA_ "FlexKomComment" SG_ 657 FT_FOG_RQ "Front fog request; off=[0], on=[1]";
BA_ "GenSigSNA" SG_ 657 FT_WPR_NOT_PRK "0h";
BA_ "GenSigSendType" SG_ 657 FT_WPR_NOT_PRK 5;
BA_ "GenSigCycleTime" SG_ 657 FT_WPR_NOT_PRK 1000;
BA_ "FlexKomSigStartValue" SG_ 657 FT_WPR_NOT_PRK "00h";
BA_ "FlexKomSigStartPos" SG_ 657 FT_WPR_NOT_PRK 56;
BA_ "FlexKomSigName" SG_ 657 FT_WPR_NOT_PRK "FT_WPR_NOT_PRK";
BA_ "FlexKomSigLaenge" SG_ 657 FT_WPR_NOT_PRK 1;
BA_ "FlexKomSID" SG_ 657 FT_WPR_NOT_PRK 1046;
BA_ "FlexKomIsMotorola" SG_ 657 FT_WPR_NOT_PRK 1;
BA_ "FlexKomComment" SG_ 657 FT_WPR_NOT_PRK "Front wiper outside park position";
BA_ "GenSigTimeout_IC" SG_ 657 HIBEAM_ON 10500;
BA_ "GenSigSNA" SG_ 657 HIBEAM_ON "0h";
BA_ "GenSigSendType" SG_ 657 HIBEAM_ON 5;
BA_ "GenSigCycleTime" SG_ 657 HIBEAM_ON 1000;
BA_ "FlexKomSigStartValue" SG_ 657 HIBEAM_ON "00h";
BA_ "FlexKomSigStartPos" SG_ 657 HIBEAM_ON 58;
BA_ "FlexKomSigName" SG_ 657 HIBEAM_ON "HIBEAM_ON";
BA_ "FlexKomSigLaenge" SG_ 657 HIBEAM_ON 1;
BA_ "FlexKomSID" SG_ 657 HIBEAM_ON 884;
BA_ "FlexKomIsMotorola" SG_ 657 HIBEAM_ON 1;
BA_ "FlexKomComment" SG_ 657 HIBEAM_ON "High beam is on; off=[0], on=[1]";
BA_ "GenSigTimeout_RF_HUB" SG_ 657 IGN_OFF_TIME_LNG 10500;
BA_ "GenSigTimeout_IC" SG_ 657 IGN_OFF_TIME_LNG 10500;
BA_ "GenSigTimeout_DTCM" SG_ 657 IGN_OFF_TIME_LNG 10500;
BA_ "GenSigStartValue" SG_ 657 IGN_OFF_TIME_LNG 4095;
BA_ "GenSigSNA" SG_ 657 IGN_OFF_TIME_LNG "FFFh";
BA_ "GenSigSendType" SG_ 657 IGN_OFF_TIME_LNG 5;
BA_ "GenSigCycleTime" SG_ 657 IGN_OFF_TIME_LNG 1000;
BA_ "FlexKomSigStartValue" SG_ 657 IGN_OFF_TIME_LNG "0FFFh";
BA_ "FlexKomSigStartPos" SG_ 657 IGN_OFF_TIME_LNG 31;
BA_ "FlexKomSigName" SG_ 657 IGN_OFF_TIME_LNG "IGN_OFF_TIME_LNG";
BA_ "FlexKomSigLaenge" SG_ 657 IGN_OFF_TIME_LNG 16;
BA_ "FlexKomSID" SG_ 657 IGN_OFF_TIME_LNG 998;
BA_ "FlexKomIsMotorola" SG_ 657 IGN_OFF_TIME_LNG 1;
BA_ "FlexKomComment" SG_ 657 IGN_OFF_TIME_LNG "Time since last ignition on (long)";
BA_ "GenSigTimeout_TPM" SG_ 657 LOBEAM_ON 10500;
BA_ "GenSigTimeout_IC" SG_ 657 LOBEAM_ON 10500;
BA_ "GenSigSNA" SG_ 657 LOBEAM_ON "0h";
BA_ "GenSigSendType" SG_ 657 LOBEAM_ON 5;
BA_ "GenSigCycleTime" SG_ 657 LOBEAM_ON 1000;
BA_ "FlexKomSigStartValue" SG_ 657 LOBEAM_ON "00h";
BA_ "FlexKomSigStartPos" SG_ 657 LOBEAM_ON 57;
BA_ "FlexKomSigName" SG_ 657 LOBEAM_ON "LOBEAM_ON";
BA_ "FlexKomSigLaenge" SG_ 657 LOBEAM_ON 1;
BA_ "FlexKomSID" SG_ 657 LOBEAM_ON 883;
BA_ "FlexKomIsMotorola" SG_ 657 LOBEAM_ON 1;
BA_ "FlexKomComment" SG_ 657 LOBEAM_ON "Low beam is on; off=[0], on=[1]";
BA_ "GenSigTimeout_TBM" SG_ 657 L_R_AJAR 10500;
BA_ "GenSigTimeout_RF_HUB" SG_ 657 L_R_AJAR 10500;
BA_ "GenSigTimeout_IC" SG_ 657 L_R_AJAR 10500;
BA_ "GenSigSNA" SG_ 657 L_R_AJAR "0h";
BA_ "GenSigSendType" SG_ 657 L_R_AJAR 5;
BA_ "GenSigCycleTime" SG_ 657 L_R_AJAR 1000;
BA_ "FlexKomSigStartValue" SG_ 657 L_R_AJAR "00h";
BA_ "FlexKomSigStartPos" SG_ 657 L_R_AJAR 22;
BA_ "FlexKomSigName" SG_ 657 L_R_AJAR "DR_AJAR";
BA_ "FlexKomSigLaenge" SG_ 657 L_R_AJAR 6;
BA_ "FlexKomSID" SG_ 657 L_R_AJAR 797;
BA_ "FlexKomIsMotorola" SG_ 657 L_R_AJAR 1;
BA_ "FlexKomComment" SG_ 657 L_R_AJAR "Door ajar";
BA_ "GenSigTimeout_SCCM" SG_ 657 PANEL_INTS 10500;
BA_ "GenSigTimeout_RF_HUB" SG_ 657 PANEL_INTS 10500;
BA_ "GenSigTimeout_IC" SG_ 657 PANEL_INTS 10500;
BA_ "GenSigTimeout_ESM" SG_ 657 PANEL_INTS 10500;
BA_ "GenSigSNA" SG_ 657 PANEL_INTS "FFh";
BA_ "GenSigSendType" SG_ 657 PANEL_INTS 5;
BA_ "GenSigCycleTime" SG_ 657 PANEL_INTS 1000;
BA_ "FlexKomSigStartValue" SG_ 657 PANEL_INTS "000000h";
BA_ "FlexKomSigStartPos" SG_ 657 PANEL_INTS 47;
BA_ "FlexKomSigName" SG_ 657 PANEL_INTS "IntLtSt_PT";
BA_ "FlexKomSigLaenge" SG_ 657 PANEL_INTS 24;
BA_ "FlexKomSID" SG_ 657 PANEL_INTS 1417;
BA_ "FlexKomIsMotorola" SG_ 657 PANEL_INTS 1;
BA_ "FlexKomComment" SG_ 657 PANEL_INTS "Interior lighting status powertrain";
BA_ "GenSigTimeout_RF_HUB" SG_ 657 PARK_BRK_EGD 10500;
BA_ "GenSigTimeout_IC" SG_ 657 PARK_BRK_EGD 10500;
BA_ "GenSigTimeout_DTCM" SG_ 657 PARK_BRK_EGD 10500;
BA_ "GenSigSNA" SG_ 657 PARK_BRK_EGD "0h";
BA_ "GenSigSendType" SG_ 657 PARK_BRK_EGD 5;
BA_ "GenSigCycleTime" SG_ 657 PARK_BRK_EGD 1000;
BA_ "FlexKomSigStartValue" SG_ 657 PARK_BRK_EGD "00h";
BA_ "FlexKomSigStartPos" SG_ 657 PARK_BRK_EGD 23;
BA_ "FlexKomSigName" SG_ 657 PARK_BRK_EGD "PARK_BRK_EGD";
BA_ "FlexKomSigLaenge" SG_ 657 PARK_BRK_EGD 1;
BA_ "FlexKomSID" SG_ 657 PARK_BRK_EGD 805;
BA_ "FlexKomIsMotorola" SG_ 657 PARK_BRK_EGD 1;
BA_ "FlexKomComment" SG_ 657 PARK_BRK_EGD "Park brake switch engaged";
BA_ "GenSigTimeout_IC" SG_ 657 PARK_LMP_ON 10500;
BA_ "GenSigSNA" SG_ 657 PARK_LMP_ON "0h";
BA_ "GenSigSendType" SG_ 657 PARK_LMP_ON 5;
BA_ "GenSigCycleTime" SG_ 657 PARK_LMP_ON 1000;
BA_ "FlexKomSigStartValue" SG_ 657 PARK_LMP_ON "00h";
BA_ "FlexKomSigStartPos" SG_ 657 PARK_LMP_ON 16;
BA_ "FlexKomSigName" SG_ 657 PARK_LMP_ON "PARK_LMP_ON";
BA_ "FlexKomSigLaenge" SG_ 657 PARK_LMP_ON 1;
BA_ "FlexKomSID" SG_ 657 PARK_LMP_ON 767;
BA_ "FlexKomIsMotorola" SG_ 657 PARK_LMP_ON 1;
BA_ "FlexKomComment" SG_ 657 PARK_LMP_ON "Parklamps are on; off=[0], on=[1]";
BA_ "GenSigTimeout_TBM" SG_ 657 PSG_AJAR 10500;
BA_ "GenSigTimeout_RF_HUB" SG_ 657 PSG_AJAR 10500;
BA_ "GenSigTimeout_ORC" SG_ 657 PSG_AJAR 3500;
BA_ "GenSigTimeout_IC" SG_ 657 PSG_AJAR 10500;
BA_ "GenSigSNA" SG_ 657 PSG_AJAR "0h";
BA_ "GenSigSendType" SG_ 657 PSG_AJAR 5;
BA_ "GenSigCycleTime" SG_ 657 PSG_AJAR 1000;
BA_ "FlexKomSigStartValue" SG_ 657 PSG_AJAR "00h";
BA_ "FlexKomSigStartPos" SG_ 657 PSG_AJAR 22;
BA_ "FlexKomSigName" SG_ 657 PSG_AJAR "DR_AJAR";
BA_ "FlexKomSigLaenge" SG_ 657 PSG_AJAR 6;
BA_ "FlexKomSID" SG_ 657 PSG_AJAR 797;
BA_ "FlexKomIsMotorola" SG_ 657 PSG_AJAR 1;
BA_ "FlexKomComment" SG_ 657 PSG_AJAR "Door ajar";
BA_ "GenSigStartValue" SG_ 657 PTC_REL1_STAT 3;
BA_ "GenSigSNA" SG_ 657 PTC_REL1_STAT "3h";
BA_ "GenSigSendType" SG_ 657 PTC_REL1_STAT 5;
BA_ "GenSigCycleTime" SG_ 657 PTC_REL1_STAT 1000;
BA_ "FlexKomSigStartValue" SG_ 657 PTC_REL1_STAT "3Fh";
BA_ "FlexKomSigStartPos" SG_ 657 PTC_REL1_STAT 47;
BA_ "FlexKomSigName" SG_ 657 PTC_REL1_STAT "PTC_REL_STAT";
BA_ "FlexKomSigLaenge" SG_ 657 PTC_REL1_STAT 6;
BA_ "FlexKomSID" SG_ 657 PTC_REL1_STAT 859;
BA_ "FlexKomIsMotorola" SG_ 657 PTC_REL1_STAT 1;
BA_ "FlexKomComment" SG_ 657 PTC_REL1_STAT "PTC relays status";
BA_ "GenSigStartValue" SG_ 657 PTC_REL2_STAT 3;
BA_ "GenSigSNA" SG_ 657 PTC_REL2_STAT "3h";
BA_ "GenSigSendType" SG_ 657 PTC_REL2_STAT 5;
BA_ "GenSigCycleTime" SG_ 657 PTC_REL2_STAT 1000;
BA_ "FlexKomSigStartValue" SG_ 657 PTC_REL2_STAT "3Fh";
BA_ "FlexKomSigStartPos" SG_ 657 PTC_REL2_STAT 47;
BA_ "FlexKomSigName" SG_ 657 PTC_REL2_STAT "PTC_REL_STAT";
BA_ "FlexKomSigLaenge" SG_ 657 PTC_REL2_STAT 6;
BA_ "FlexKomSID" SG_ 657 PTC_REL2_STAT 859;
BA_ "FlexKomIsMotorola" SG_ 657 PTC_REL2_STAT 1;
BA_ "FlexKomComment" SG_ 657 PTC_REL2_STAT "PTC relays status";
BA_ "GenSigStartValue" SG_ 657 PTC_REL3_STAT 3;
BA_ "GenSigSNA" SG_ 657 PTC_REL3_STAT "3h";
BA_ "GenSigSendType" SG_ 657 PTC_REL3_STAT 5;
BA_ "GenSigCycleTime" SG_ 657 PTC_REL3_STAT 1000;
BA_ "FlexKomSigStartValue" SG_ 657 PTC_REL3_STAT "3Fh";
BA_ "FlexKomSigStartPos" SG_ 657 PTC_REL3_STAT 47;
BA_ "FlexKomSigName" SG_ 657 PTC_REL3_STAT "PTC_REL_STAT";
BA_ "FlexKomSigLaenge" SG_ 657 PTC_REL3_STAT 6;
BA_ "FlexKomSID" SG_ 657 PTC_REL3_STAT 859;
BA_ "FlexKomIsMotorola" SG_ 657 PTC_REL3_STAT 1;
BA_ "FlexKomComment" SG_ 657 PTC_REL3_STAT "PTC relays status";
BA_ "GenSigTimeout_TPM" SG_ 657 REV_GEAR 10500;
BA_ "GenSigTimeout_RF_HUB" SG_ 657 REV_GEAR 10500;
BA_ "GenSigTimeout_PTS" SG_ 657 REV_GEAR 3500;
BA_ "GenSigTimeout_ORC" SG_ 657 REV_GEAR 3500;
BA_ "GenSigTimeout_IC" SG_ 657 REV_GEAR 10500;
BA_ "GenSigSNA" SG_ 657 REV_GEAR "0h";
BA_ "GenSigSendType" SG_ 657 REV_GEAR 5;
BA_ "GenSigCycleTime" SG_ 657 REV_GEAR 1000;
BA_ "FlexKomSigStartValue" SG_ 657 REV_GEAR "00h";
BA_ "FlexKomSigStartPos" SG_ 657 REV_GEAR 4;
BA_ "FlexKomSigName" SG_ 657 REV_GEAR "REV_GEAR";
BA_ "FlexKomSigLaenge" SG_ 657 REV_GEAR 1;
BA_ "FlexKomSID" SG_ 657 REV_GEAR 685;
BA_ "FlexKomIsMotorola" SG_ 657 REV_GEAR 1;
BA_ "FlexKomComment" SG_ 657 REV_GEAR "Reverse Gear (manual trans)";
BA_ "GenSigTimeout_IC" SG_ 657 R_FOG_RQ 10500;
BA_ "GenSigSNA" SG_ 657 R_FOG_RQ "0h";
BA_ "GenSigSendType" SG_ 657 R_FOG_RQ 5;
BA_ "GenSigCycleTime" SG_ 657 R_FOG_RQ 1000;
BA_ "FlexKomSigStartValue" SG_ 657 R_FOG_RQ "00h";
BA_ "FlexKomSigStartPos" SG_ 657 R_FOG_RQ 3;
BA_ "FlexKomSigName" SG_ 657 R_FOG_RQ "R_FOG_RQ";
BA_ "FlexKomSigLaenge" SG_ 657 R_FOG_RQ 1;
BA_ "FlexKomSID" SG_ 657 R_FOG_RQ 427;
BA_ "FlexKomIsMotorola" SG_ 657 R_FOG_RQ 1;
BA_ "FlexKomComment" SG_ 657 R_FOG_RQ "Rear fog request; [0] = off, [1] = on";
BA_ "GenSigTimeout_TBM" SG_ 657 R_R_AJAR 10500;
BA_ "GenSigTimeout_RF_HUB" SG_ 657 R_R_AJAR 10500;
BA_ "GenSigTimeout_IC" SG_ 657 R_R_AJAR 10500;
BA_ "GenSigSNA" SG_ 657 R_R_AJAR "0h";
BA_ "GenSigSendType" SG_ 657 R_R_AJAR 5;
BA_ "GenSigCycleTime" SG_ 657 R_R_AJAR 1000;
BA_ "FlexKomSigStartValue" SG_ 657 R_R_AJAR "00h";
BA_ "FlexKomSigStartPos" SG_ 657 R_R_AJAR 22;
BA_ "FlexKomSigName" SG_ 657 R_R_AJAR "DR_AJAR";
BA_ "FlexKomSigLaenge" SG_ 657 R_R_AJAR 6;
BA_ "FlexKomSID" SG_ 657 R_R_AJAR 797;
BA_ "FlexKomIsMotorola" SG_ 657 R_R_AJAR 1;
BA_ "FlexKomComment" SG_ 657 R_R_AJAR "Door ajar";
BA_ "GenSigTimeout_TPM" SG_ 657 SHIP_STAT 10500;
BA_ "GenSigTimeout_RF_HUB" SG_ 657 SHIP_STAT 10500;
BA_ "GenSigTimeout_ORC" SG_ 657 SHIP_STAT 3500;
BA_ "GenSigTimeout_IC" SG_ 657 SHIP_STAT 10500;
BA_ "GenSigTimeout_DTCM" SG_ 657 SHIP_STAT 10500;
BA_ "GenSigStartValue" SG_ 657 SHIP_STAT 3;
BA_ "GenSigSNA" SG_ 657 SHIP_STAT "3h";
BA_ "GenSigSendType" SG_ 657 SHIP_STAT 5;
BA_ "GenSigCycleTime" SG_ 657 SHIP_STAT 1000;
BA_ "FlexKomSigStartValue" SG_ 657 SHIP_STAT "03h";
BA_ "FlexKomSigStartPos" SG_ 657 SHIP_STAT 29;
BA_ "FlexKomSigName" SG_ 657 SHIP_STAT "SHIP_STAT";
BA_ "FlexKomSigLaenge" SG_ 657 SHIP_STAT 2;
BA_ "FlexKomSID" SG_ 657 SHIP_STAT 869;
BA_ "FlexKomIsMotorola" SG_ 657 SHIP_STAT 1;
BA_ "FlexKomComment" SG_ 657 SHIP_STAT "Shipping status";
BA_ "GenSigTimeout_TBM" SG_ 657 TLG_AJAR 10500;
BA_ "GenSigTimeout_RF_HUB" SG_ 657 TLG_AJAR 10500;
BA_ "GenSigTimeout_IC" SG_ 657 TLG_AJAR 10500;
BA_ "GenSigSNA" SG_ 657 TLG_AJAR "0h";
BA_ "GenSigSendType" SG_ 657 TLG_AJAR 5;
BA_ "GenSigCycleTime" SG_ 657 TLG_AJAR 1000;
BA_ "FlexKomSigStartValue" SG_ 657 TLG_AJAR "00h";
BA_ "FlexKomSigStartPos" SG_ 657 TLG_AJAR 22;
BA_ "FlexKomSigName" SG_ 657 TLG_AJAR "DR_AJAR";
BA_ "FlexKomSigLaenge" SG_ 657 TLG_AJAR 6;
BA_ "FlexKomSID" SG_ 657 TLG_AJAR 797;
BA_ "FlexKomIsMotorola" SG_ 657 TLG_AJAR 1;
BA_ "FlexKomComment" SG_ 657 TLG_AJAR "Door ajar";
BA_ "GenSigTimeout_PTS" SG_ 657 TurnInd_LT_ON 10500;
BA_ "GenSigTimeout_IC" SG_ 657 TurnInd_LT_ON 10500;
BA_ "GenSigSNA" SG_ 657 TurnInd_LT_ON "0h";
BA_ "GenSigSendType" SG_ 657 TurnInd_LT_ON 5;
BA_ "GenSigCycleTime" SG_ 657 TurnInd_LT_ON 1000;
BA_ "FlexKomSigStartValue" SG_ 657 TurnInd_LT_ON "00h";
BA_ "FlexKomSigStartPos" SG_ 657 TurnInd_LT_ON 31;
BA_ "FlexKomSigName" SG_ 657 TurnInd_LT_ON "TurnInd_STAT";
BA_ "FlexKomSigLaenge" SG_ 657 TurnInd_LT_ON 2;
BA_ "FlexKomSID" SG_ 657 TurnInd_LT_ON 759;
BA_ "FlexKomIsMotorola" SG_ 657 TurnInd_LT_ON 1;
BA_ "FlexKomComment" SG_ 657 TurnInd_LT_ON "Turn indication status";
BA_ "GenSigTimeout_PTS" SG_ 657 TurnInd_RT_ON 10500;
BA_ "GenSigTimeout_IC" SG_ 657 TurnInd_RT_ON 10500;
BA_ "GenSigSNA" SG_ 657 TurnInd_RT_ON "0h";
BA_ "GenSigSendType" SG_ 657 TurnInd_RT_ON 5;
BA_ "GenSigCycleTime" SG_ 657 TurnInd_RT_ON 1000;
BA_ "FlexKomSigStartValue" SG_ 657 TurnInd_RT_ON "00h";
BA_ "FlexKomSigStartPos" SG_ 657 TurnInd_RT_ON 31;
BA_ "FlexKomSigName" SG_ 657 TurnInd_RT_ON "TurnInd_STAT";
BA_ "FlexKomSigLaenge" SG_ 657 TurnInd_RT_ON 2;
BA_ "FlexKomSID" SG_ 657 TurnInd_RT_ON 759;
BA_ "FlexKomIsMotorola" SG_ 657 TurnInd_RT_ON 1;
BA_ "FlexKomComment" SG_ 657 TurnInd_RT_ON "Turn indication status";
BA_ "GenSigTimeout_TBM" SG_ 657 WASH_FLUID_LO 10500;
BA_ "GenSigTimeout_IC" SG_ 657 WASH_FLUID_LO 10500;
BA_ "GenSigTimeout_ETM" SG_ 657 WASH_FLUID_LO 10500;
BA_ "GenSigSNA" SG_ 657 WASH_FLUID_LO "0h";
BA_ "GenSigSendType" SG_ 657 WASH_FLUID_LO 5;
BA_ "GenSigCycleTime" SG_ 657 WASH_FLUID_LO 1000;
BA_ "FlexKomSigStartValue" SG_ 657 WASH_FLUID_LO "00h";
BA_ "FlexKomSigStartPos" SG_ 657 WASH_FLUID_LO 63;
BA_ "FlexKomSigName" SG_ 657 WASH_FLUID_LO "WASH_FLUID_LO";
BA_ "FlexKomSigLaenge" SG_ 657 WASH_FLUID_LO 1;
BA_ "FlexKomSID" SG_ 657 WASH_FLUID_LO 965;
BA_ "FlexKomIsMotorola" SG_ 657 WASH_FLUID_LO 1;
BA_ "FlexKomComment" SG_ 657 WASH_FLUID_LO "Low washer fluid warning (1=Fluid is low)";
BA_ "GenSigTimeout_IC" SG_ 613 AUX_UNAV_BATT_CHRG 10500;
BA_ "GenSigSNA" SG_ 613 AUX_UNAV_BATT_CHRG "0h";
BA_ "GenSigSendType" SG_ 613 AUX_UNAV_BATT_CHRG 5;
BA_ "GenSigCycleTime" SG_ 613 AUX_UNAV_BATT_CHRG 1000;
BA_ "FlexKomSigStartValue" SG_ 613 AUX_UNAV_BATT_CHRG "00000000003F06FFh";
BA_ "FlexKomSigStartPos" SG_ 613 AUX_UNAV_BATT_CHRG 7;
BA_ "FlexKomSigName" SG_ 613 AUX_UNAV_BATT_CHRG "CBC_PT10_Pkt";
BA_ "FlexKomSigLaenge" SG_ 613 AUX_UNAV_BATT_CHRG 64;
BA_ "FlexKomSID" SG_ 613 AUX_UNAV_BATT_CHRG 2499;
BA_ "FlexKomIsMotorola" SG_ 613 AUX_UNAV_BATT_CHRG 1;
BA_ "FlexKomComment" SG_ 613 AUX_UNAV_BATT_CHRG "CBC message 10 packet";
BA_ "GenSigStartValue" SG_ 613 DriverDoorOnOffSts 3;
BA_ "GenSigSNA" SG_ 613 DriverDoorOnOffSts "3h";
BA_ "GenSigSendType" SG_ 613 DriverDoorOnOffSts 5;
BA_ "GenSigCycleTime" SG_ 613 DriverDoorOnOffSts 1000;
BA_ "FlexKomSigStartValue" SG_ 613 DriverDoorOnOffSts "00000000003F06FFh";
BA_ "FlexKomSigStartPos" SG_ 613 DriverDoorOnOffSts 7;
BA_ "FlexKomSigName" SG_ 613 DriverDoorOnOffSts "CBC_PT10_Pkt";
BA_ "FlexKomSigLaenge" SG_ 613 DriverDoorOnOffSts 64;
BA_ "FlexKomSID" SG_ 613 DriverDoorOnOffSts 2499;
BA_ "FlexKomIsMotorola" SG_ 613 DriverDoorOnOffSts 1;
BA_ "FlexKomComment" SG_ 613 DriverDoorOnOffSts "CBC message 10 packet";
BA_ "GenSigTimeout_IC" SG_ 613 DrvMd_PopUpRqst 10500;
BA_ "GenSigSNA" SG_ 613 DrvMd_PopUpRqst "FFh";
BA_ "GenSigSendType" SG_ 613 DrvMd_PopUpRqst 5;
BA_ "GenSigCycleTime" SG_ 613 DrvMd_PopUpRqst 1000;
BA_ "FlexKomSigStartValue" SG_ 613 DrvMd_PopUpRqst "00000000003F06FFh";
BA_ "FlexKomSigStartPos" SG_ 613 DrvMd_PopUpRqst 7;
BA_ "FlexKomSigName" SG_ 613 DrvMd_PopUpRqst "CBC_PT10_Pkt";
BA_ "FlexKomSigLaenge" SG_ 613 DrvMd_PopUpRqst 64;
BA_ "FlexKomSID" SG_ 613 DrvMd_PopUpRqst 2499;
BA_ "FlexKomIsMotorola" SG_ 613 DrvMd_PopUpRqst 1;
BA_ "FlexKomComment" SG_ 613 DrvMd_PopUpRqst "CBC message 10 packet";
BA_ "RID" SG_ 613 Exhaust_RQ_ICS "6788";
BA_ "GenSigSNA" SG_ 613 Exhaust_RQ_ICS "3h";
BA_ "GenSigSendType" SG_ 613 Exhaust_RQ_ICS 5;
BA_ "GenSigCycleTime" SG_ 613 Exhaust_RQ_ICS 1000;
BA_ "FlexKomSigStartValue" SG_ 613 Exhaust_RQ_ICS "00000000003F06FFh";
BA_ "FlexKomSigStartPos" SG_ 613 Exhaust_RQ_ICS 7;
BA_ "FlexKomSigName" SG_ 613 Exhaust_RQ_ICS "CBC_PT10_Pkt";
BA_ "FlexKomSigLaenge" SG_ 613 Exhaust_RQ_ICS 64;
BA_ "FlexKomSID" SG_ 613 Exhaust_RQ_ICS 2499;
BA_ "FlexKomIsMotorola" SG_ 613 Exhaust_RQ_ICS 1;
BA_ "FlexKomComment" SG_ 613 Exhaust_RQ_ICS "CBC message 10 packet";
BA_ "GenSigStartValue" SG_ 613 LHRDoorOnOffSts 3;
BA_ "GenSigSNA" SG_ 613 LHRDoorOnOffSts "3h";
BA_ "GenSigSendType" SG_ 613 LHRDoorOnOffSts 5;
BA_ "GenSigCycleTime" SG_ 613 LHRDoorOnOffSts 1000;
BA_ "FlexKomSigStartValue" SG_ 613 LHRDoorOnOffSts "00000000003F06FFh";
BA_ "FlexKomSigStartPos" SG_ 613 LHRDoorOnOffSts 7;
BA_ "FlexKomSigName" SG_ 613 LHRDoorOnOffSts "CBC_PT10_Pkt";
BA_ "FlexKomSigLaenge" SG_ 613 LHRDoorOnOffSts 64;
BA_ "FlexKomSID" SG_ 613 LHRDoorOnOffSts 2499;
BA_ "FlexKomIsMotorola" SG_ 613 LHRDoorOnOffSts 1;
BA_ "FlexKomComment" SG_ 613 LHRDoorOnOffSts "CBC message 10 packet";
BA_ "GenSigStartValue" SG_ 613 PsngrDoorOnOffSts 3;
BA_ "GenSigSNA" SG_ 613 PsngrDoorOnOffSts "3h";
BA_ "GenSigSendType" SG_ 613 PsngrDoorOnOffSts 5;
BA_ "GenSigCycleTime" SG_ 613 PsngrDoorOnOffSts 1000;
BA_ "FlexKomSigStartValue" SG_ 613 PsngrDoorOnOffSts "00000000003F06FFh";
BA_ "FlexKomSigStartPos" SG_ 613 PsngrDoorOnOffSts 7;
BA_ "FlexKomSigName" SG_ 613 PsngrDoorOnOffSts "CBC_PT10_Pkt";
BA_ "FlexKomSigLaenge" SG_ 613 PsngrDoorOnOffSts 64;
BA_ "FlexKomSID" SG_ 613 PsngrDoorOnOffSts 2499;
BA_ "FlexKomIsMotorola" SG_ 613 PsngrDoorOnOffSts 1;
BA_ "FlexKomComment" SG_ 613 PsngrDoorOnOffSts "CBC message 10 packet";
BA_ "GenSigStartValue" SG_ 613 RHRDoorOnOffSts 3;
BA_ "GenSigSNA" SG_ 613 RHRDoorOnOffSts "3h";
BA_ "GenSigSendType" SG_ 613 RHRDoorOnOffSts 5;
BA_ "GenSigCycleTime" SG_ 613 RHRDoorOnOffSts 1000;
BA_ "FlexKomSigStartValue" SG_ 613 RHRDoorOnOffSts "00000000003F06FFh";
BA_ "FlexKomSigStartPos" SG_ 613 RHRDoorOnOffSts 7;
BA_ "FlexKomSigName" SG_ 613 RHRDoorOnOffSts "CBC_PT10_Pkt";
BA_ "FlexKomSigLaenge" SG_ 613 RHRDoorOnOffSts 64;
BA_ "FlexKomSID" SG_ 613 RHRDoorOnOffSts 2499;
BA_ "FlexKomIsMotorola" SG_ 613 RHRDoorOnOffSts 1;
BA_ "FlexKomComment" SG_ 613 RHRDoorOnOffSts "CBC message 10 packet";
BA_ "GenSigTimeout_TPM" SG_ 119 CmdIgnStat 1010;
BA_ "GenSigTimeout_TCM" SG_ 119 CmdIgnStat 210;
BA_ "GenSigTimeout_SCCM" SG_ 119 CmdIgnStat 210;
BA_ "GenSigTimeout_PTS" SG_ 119 CmdIgnStat 210;
BA_ "GenSigTimeout_ORC" SG_ 119 CmdIgnStat 70;
BA_ "GenSigTimeout_IC" SG_ 119 CmdIgnStat 210;
BA_ "GenSigTimeout_ESM" SG_ 119 CmdIgnStat 310;
BA_ "GenSigTimeout_ESL" SG_ 119 CmdIgnStat 110;
BA_ "GenSigTimeout_EHPS" SG_ 119 CmdIgnStat 210;
BA_ "GenSigTimeout_DTCM" SG_ 119 CmdIgnStat 210;
BA_ "GenSigTimeout_ASBS" SG_ 119 CmdIgnStat 410;
BA_ "GenSigTimeout_AHLM" SG_ 119 CmdIgnStat 210;
BA_ "GenSigSNA" SG_ 119 CmdIgnStat "7h";
BA_ "GenSigCycleTime" SG_ 119 CmdIgnStat 20;
BA_ "FlexKomSigStartValue" SG_ 119 CmdIgnStat "0000h";
BA_ "FlexKomSigStartPos" SG_ 119 CmdIgnStat 7;
BA_ "FlexKomSigName" SG_ 119 CmdIgnStat "VehStart_PKT";
BA_ "FlexKomSigLaenge" SG_ 119 CmdIgnStat 16;
BA_ "FlexKomSID" SG_ 119 CmdIgnStat 880;
BA_ "FlexKomIsMotorola" SG_ 119 CmdIgnStat 1;
BA_ "FlexKomComment" SG_ 119 CmdIgnStat "Vehicle start packet";
BA_ "GenSigTimeout_TPM" SG_ 119 KeyInIgn 1010;
BA_ "GenSigTimeout_ORC" SG_ 119 KeyInIgn 70;
BA_ "GenSigTimeout_IC" SG_ 119 KeyInIgn 210;
BA_ "GenSigTimeout_ESM" SG_ 119 KeyInIgn 310;
BA_ "GenSigTimeout_ESL" SG_ 119 KeyInIgn 110;
BA_ "GenSigSNA" SG_ 119 KeyInIgn "3h";
BA_ "GenSigCycleTime" SG_ 119 KeyInIgn 20;
BA_ "FlexKomSigStartValue" SG_ 119 KeyInIgn "0000h";
BA_ "FlexKomSigStartPos" SG_ 119 KeyInIgn 7;
BA_ "FlexKomSigName" SG_ 119 KeyInIgn "VehStart_PKT";
BA_ "FlexKomSigLaenge" SG_ 119 KeyInIgn 16;
BA_ "FlexKomSID" SG_ 119 KeyInIgn 880;
BA_ "FlexKomIsMotorola" SG_ 119 KeyInIgn 1;
BA_ "FlexKomComment" SG_ 119 KeyInIgn "Vehicle start packet";
BA_ "GenSigTimeout_TPM" SG_ 119 RemStActv 1010;
BA_ "GenSigTimeout_ORC" SG_ 119 RemStActv 70;
BA_ "GenSigTimeout_IC" SG_ 119 RemStActv 210;
BA_ "GenSigTimeout_ESM" SG_ 119 RemStActv 310;
BA_ "GenSigSNA" SG_ 119 RemStActv "0h";
BA_ "GenSigCycleTime" SG_ 119 RemStActv 20;
BA_ "FlexKomSigStartValue" SG_ 119 RemStActv "0000h";
BA_ "FlexKomSigStartPos" SG_ 119 RemStActv 7;
BA_ "FlexKomSigName" SG_ 119 RemStActv "VehStart_PKT";
BA_ "FlexKomSigLaenge" SG_ 119 RemStActv 16;
BA_ "FlexKomSID" SG_ 119 RemStActv 880;
BA_ "FlexKomIsMotorola" SG_ 119 RemStActv 1;
BA_ "FlexKomComment" SG_ 119 RemStActv "Vehicle start packet";
BA_ "GenSigTimeout_TPM" SG_ 119 StTyp 1010;
BA_ "GenSigTimeout_ORC" SG_ 119 StTyp 70;
BA_ "GenSigTimeout_IC" SG_ 119 StTyp 210;
BA_ "GenSigSNA" SG_ 119 StTyp "7h";
BA_ "GenSigCycleTime" SG_ 119 StTyp 20;
BA_ "FlexKomSigStartValue" SG_ 119 StTyp "0000h";
BA_ "FlexKomSigStartPos" SG_ 119 StTyp 7;
BA_ "FlexKomSigName" SG_ 119 StTyp "VehStart_PKT";
BA_ "FlexKomSigLaenge" SG_ 119 StTyp 16;
BA_ "FlexKomSID" SG_ 119 StTyp 880;
BA_ "FlexKomIsMotorola" SG_ 119 StTyp 1;
BA_ "FlexKomComment" SG_ 119 StTyp "Vehicle start packet";
BA_ "GenSigTimeout_ORC" SG_ 119 StartRelayBCMFault 70;
BA_ "GenSigSNA" SG_ 119 StartRelayBCMFault "0h";
BA_ "GenSigCycleTime" SG_ 119 StartRelayBCMFault 20;
BA_ "FlexKomSigStartValue" SG_ 119 StartRelayBCMFault "00h";
BA_ "FlexKomSigStartPos" SG_ 119 StartRelayBCMFault 14;
BA_ "FlexKomSigName" SG_ 119 StartRelayBCMFault "StartRelayBCMFault";
BA_ "FlexKomSigLaenge" SG_ 119 StartRelayBCMFault 1;
BA_ "FlexKomSID" SG_ 119 StartRelayBCMFault 1573;
BA_ "FlexKomIsMotorola" SG_ 119 StartRelayBCMFault 1;
BA_ "FlexKomComment" SG_ 119 StartRelayBCMFault "CBC starter relay fault detected";
BA_ "GenSigSNA" SG_ 119 StartRelayBCMSts "0h";
BA_ "GenSigCycleTime" SG_ 119 StartRelayBCMSts 20;
BA_ "FlexKomSigStartValue" SG_ 119 StartRelayBCMSts "00h";
BA_ "FlexKomSigStartPos" SG_ 119 StartRelayBCMSts 13;
BA_ "FlexKomSigName" SG_ 119 StartRelayBCMSts "StartRelayBCMSts";
BA_ "FlexKomSigLaenge" SG_ 119 StartRelayBCMSts 1;
BA_ "FlexKomSID" SG_ 119 StartRelayBCMSts 1526;
BA_ "FlexKomIsMotorola" SG_ 119 StartRelayBCMSts 1;
BA_ "FlexKomComment" SG_ 119 StartRelayBCMSts "CBC starter relay status; [1] = ON";
BA_ "GenSigTimeout_RF_HUB" SG_ 299 AMB_TEMP_AVG 1050;
BA_ "GenSigTimeout_ORC" SG_ 299 AMB_TEMP_AVG 350;
BA_ "GenSigTimeout_IC" SG_ 299 AMB_TEMP_AVG 1050;
BA_ "GenSigStartValue" SG_ 299 AMB_TEMP_AVG 65535;
BA_ "GenSigSNA" SG_ 299 AMB_TEMP_AVG "FFFFh";
BA_ "GenSigCycleTime" SG_ 299 AMB_TEMP_AVG 100;
BA_ "FlexKomSigStartValue" SG_ 299 AMB_TEMP_AVG "FFFFh";
BA_ "FlexKomSigStartPos" SG_ 299 AMB_TEMP_AVG 15;
BA_ "FlexKomSigName" SG_ 299 AMB_TEMP_AVG "AMB_TEMP_AVG";
BA_ "FlexKomSigLaenge" SG_ 299 AMB_TEMP_AVG 16;
BA_ "FlexKomSID" SG_ 299 AMB_TEMP_AVG 840;
BA_ "FlexKomIsMotorola" SG_ 299 AMB_TEMP_AVG 1;
BA_ "FlexKomComment" SG_ 299 AMB_TEMP_AVG "Averaged ambient temperature";
BA_ "RID" SG_ 299 AMB_TEMP_VOLT "1805";
BA_ "GenSigTimeout_ORC" SG_ 299 AMB_TEMP_VOLT 350;
BA_ "GenSigStartValue" SG_ 299 AMB_TEMP_VOLT 255;
BA_ "GenSigSNA" SG_ 299 AMB_TEMP_VOLT "FFh";
BA_ "GenSigCycleTime" SG_ 299 AMB_TEMP_VOLT 100;
BA_ "FlexKomSigStartValue" SG_ 299 AMB_TEMP_VOLT "FFh";
BA_ "FlexKomSigStartPos" SG_ 299 AMB_TEMP_VOLT 31;
BA_ "FlexKomSigName" SG_ 299 AMB_TEMP_VOLT "AMB_TEMP_VOLT";
BA_ "FlexKomSigLaenge" SG_ 299 AMB_TEMP_VOLT 8;
BA_ "FlexKomSID" SG_ 299 AMB_TEMP_VOLT 1201;
BA_ "FlexKomIsMotorola" SG_ 299 AMB_TEMP_VOLT 1;
BA_ "FlexKomComment" SG_ 299 AMB_TEMP_VOLT "Ambient Temp Sensor A/D Voltage";
BA_ "GenSigTimeout_RF_HUB" SG_ 299 AirTemp_Outsd 1050;
BA_ "GenSigTimeout_ORC" SG_ 299 AirTemp_Outsd 350;
BA_ "GenSigTimeout_IC" SG_ 299 AirTemp_Outsd 1050;
BA_ "GenSigTimeout_DTCM" SG_ 299 AirTemp_Outsd 1050;
BA_ "GenSigStartValue" SG_ 299 AirTemp_Outsd 255;
BA_ "GenSigSNA" SG_ 299 AirTemp_Outsd "FFh";
BA_ "GenSigCycleTime" SG_ 299 AirTemp_Outsd 100;
BA_ "FlexKomSigStartValue" SG_ 299 AirTemp_Outsd "FFh";
BA_ "FlexKomSigStartPos" SG_ 299 AirTemp_Outsd 7;
BA_ "FlexKomSigName" SG_ 299 AirTemp_Outsd "AirTemp_Outsd";
BA_ "FlexKomSigLaenge" SG_ 299 AirTemp_Outsd 8;
BA_ "FlexKomSID" SG_ 299 AirTemp_Outsd 773;
BA_ "FlexKomIsMotorola" SG_ 299 AirTemp_Outsd 1;
BA_ "FlexKomComment" SG_ 299 AirTemp_Outsd "Outside air temperature";
BA_ "GenSigTimeout_SCCM" SG_ 299 BATT_VOLT 1050;
BA_ "GenSigTimeout_RF_HUB" SG_ 299 BATT_VOLT 1050;
BA_ "GenSigTimeout_ORC" SG_ 299 BATT_VOLT 350;
BA_ "GenSigTimeout_IC" SG_ 299 BATT_VOLT 1050;
BA_ "GenSigTimeout_ESM" SG_ 299 BATT_VOLT 1050;
BA_ "GenSigTimeout_EHPS" SG_ 299 BATT_VOLT 1050;
BA_ "GenSigTimeout_DTCM" SG_ 299 BATT_VOLT 1050;
BA_ "GenSigStartValue" SG_ 299 BATT_VOLT 255;
BA_ "GenSigSNA" SG_ 299 BATT_VOLT "FFh";
BA_ "GenSigCycleTime" SG_ 299 BATT_VOLT 100;
BA_ "FlexKomSigStartValue" SG_ 299 BATT_VOLT "FFh";
BA_ "FlexKomSigStartPos" SG_ 299 BATT_VOLT 55;
BA_ "FlexKomSigName" SG_ 299 BATT_VOLT "BATT_VOLT";
BA_ "FlexKomSigLaenge" SG_ 299 BATT_VOLT 8;
BA_ "FlexKomSID" SG_ 299 BATT_VOLT 839;
BA_ "FlexKomIsMotorola" SG_ 299 BATT_VOLT 1;
BA_ "FlexKomComment" SG_ 299 BATT_VOLT "System voltage";
BA_ "GenSigTimeout_IC" SG_ 299 FUEL_VOLT 1050;
BA_ "GenSigStartValue" SG_ 299 FUEL_VOLT 255;
BA_ "GenSigSNA" SG_ 299 FUEL_VOLT "FFh";
BA_ "GenSigCycleTime" SG_ 299 FUEL_VOLT 100;
BA_ "FlexKomSigStartValue" SG_ 299 FUEL_VOLT "FFh";
BA_ "FlexKomSigStartPos" SG_ 299 FUEL_VOLT 39;
BA_ "FlexKomSigName" SG_ 299 FUEL_VOLT "FUEL_VOLT";
BA_ "FlexKomSigLaenge" SG_ 299 FUEL_VOLT 8;
BA_ "FlexKomSID" SG_ 299 FUEL_VOLT 881;
BA_ "FlexKomIsMotorola" SG_ 299 FUEL_VOLT 1;
BA_ "FlexKomComment" SG_ 299 FUEL_VOLT "Fuel level A/D Voltage (Single tank OR Primary on ";
BA_ "GenSigTimeout_SCCM" SG_ 643 ACC_DLY_ACT 10500;
BA_ "GenSigTimeout_IC" SG_ 643 ACC_DLY_ACT 10500;
BA_ "GenSigSNA" SG_ 643 ACC_DLY_ACT "0h";
BA_ "GenSigSendType" SG_ 643 ACC_DLY_ACT 5;
BA_ "GenSigCycleTime" SG_ 643 ACC_DLY_ACT 1000;
BA_ "FlexKomSigStartValue" SG_ 643 ACC_DLY_ACT "00h";
BA_ "FlexKomSigStartPos" SG_ 643 ACC_DLY_ACT 26;
BA_ "FlexKomSigName" SG_ 643 ACC_DLY_ACT "ACC_DLY_ACT";
BA_ "FlexKomSigLaenge" SG_ 643 ACC_DLY_ACT 1;
BA_ "FlexKomSID" SG_ 643 ACC_DLY_ACT 841;
BA_ "FlexKomIsMotorola" SG_ 643 ACC_DLY_ACT 1;
BA_ "FlexKomComment" SG_ 643 ACC_DLY_ACT "Accessory Delay Active";
BA_ "GenSigTimeout_IC" SG_ 643 HdAjar 10500;
BA_ "GenSigStartValue" SG_ 643 HdAjar 1;
BA_ "GenSigSNA" SG_ 643 HdAjar "1h";
BA_ "GenSigSendType" SG_ 643 HdAjar 5;
BA_ "GenSigCycleTime" SG_ 643 HdAjar 1000;
BA_ "FlexKomSigStartValue" SG_ 643 HdAjar "01h";
BA_ "FlexKomSigStartPos" SG_ 643 HdAjar 10;
BA_ "FlexKomSigName" SG_ 643 HdAjar "HdAjar";
BA_ "FlexKomSigLaenge" SG_ 643 HdAjar 1;
BA_ "FlexKomSID" SG_ 643 HdAjar 1818;
BA_ "FlexKomIsMotorola" SG_ 643 HdAjar 1;
BA_ "FlexKomComment" SG_ 643 HdAjar "Hood latch ajar, left or single (1=ajar)";
BA_ "GenSigTimeout_IC" SG_ 643 RemSt_Inhibit 10500;
BA_ "GenSigTimeout_ETM" SG_ 643 RemSt_Inhibit 10500;
BA_ "GenSigSNA" SG_ 643 RemSt_Inhibit "FFh";
BA_ "GenSigSendType" SG_ 643 RemSt_Inhibit 5;
BA_ "GenSigCycleTime" SG_ 643 RemSt_Inhibit 1000;
BA_ "FlexKomSigStartValue" SG_ 643 RemSt_Inhibit "00h";
BA_ "FlexKomSigStartPos" SG_ 643 RemSt_Inhibit 39;
BA_ "FlexKomSigName" SG_ 643 RemSt_Inhibit "RemSt_Inhibit";
BA_ "FlexKomSigLaenge" SG_ 643 RemSt_Inhibit 8;
BA_ "FlexKomSID" SG_ 643 RemSt_Inhibit 1047;
BA_ "FlexKomIsMotorola" SG_ 643 RemSt_Inhibit 1;
BA_ "FlexKomComment" SG_ 643 RemSt_Inhibit "Remote start inhibit";
BA_ "GenSigTimeout_IC" SG_ 643 TurnLmp_FL_Flt 10500;
BA_ "GenSigSNA" SG_ 643 TurnLmp_FL_Flt "0h";
BA_ "GenSigSendType" SG_ 643 TurnLmp_FL_Flt 5;
BA_ "GenSigCycleTime" SG_ 643 TurnLmp_FL_Flt 1000;
BA_ "FlexKomSigStartValue" SG_ 643 TurnLmp_FL_Flt "00h";
BA_ "FlexKomSigStartPos" SG_ 643 TurnLmp_FL_Flt 14;
BA_ "FlexKomSigName" SG_ 643 TurnLmp_FL_Flt "TurnLmp_F_Flt";
BA_ "FlexKomSigLaenge" SG_ 643 TurnLmp_FL_Flt 2;
BA_ "FlexKomSID" SG_ 643 TurnLmp_FL_Flt 973;
BA_ "FlexKomIsMotorola" SG_ 643 TurnLmp_FL_Flt 1;
BA_ "FlexKomComment" SG_ 643 TurnLmp_FL_Flt "Turn indication lamp front fault";
BA_ "GenSigTimeout_IC" SG_ 643 TurnLmp_FR_Flt 10500;
BA_ "GenSigSNA" SG_ 643 TurnLmp_FR_Flt "0h";
BA_ "GenSigSendType" SG_ 643 TurnLmp_FR_Flt 5;
BA_ "GenSigCycleTime" SG_ 643 TurnLmp_FR_Flt 1000;
BA_ "FlexKomSigStartValue" SG_ 643 TurnLmp_FR_Flt "00h";
BA_ "FlexKomSigStartPos" SG_ 643 TurnLmp_FR_Flt 14;
BA_ "FlexKomSigName" SG_ 643 TurnLmp_FR_Flt "TurnLmp_F_Flt";
BA_ "FlexKomSigLaenge" SG_ 643 TurnLmp_FR_Flt 2;
BA_ "FlexKomSID" SG_ 643 TurnLmp_FR_Flt 973;
BA_ "FlexKomIsMotorola" SG_ 643 TurnLmp_FR_Flt 1;
BA_ "FlexKomComment" SG_ 643 TurnLmp_FR_Flt "Turn indication lamp front fault";
BA_ "GenSigTimeout_IC" SG_ 643 TurnLmp_RL_Flt 10500;
BA_ "GenSigSNA" SG_ 643 TurnLmp_RL_Flt "0h";
BA_ "GenSigSendType" SG_ 643 TurnLmp_RL_Flt 5;
BA_ "GenSigCycleTime" SG_ 643 TurnLmp_RL_Flt 1000;
BA_ "FlexKomSigStartValue" SG_ 643 TurnLmp_RL_Flt "00h";
BA_ "FlexKomSigStartPos" SG_ 643 TurnLmp_RL_Flt 25;
BA_ "FlexKomSigName" SG_ 643 TurnLmp_RL_Flt "TurnLmp_R_Flt";
BA_ "FlexKomSigLaenge" SG_ 643 TurnLmp_RL_Flt 2;
BA_ "FlexKomSID" SG_ 643 TurnLmp_RL_Flt 1033;
BA_ "FlexKomIsMotorola" SG_ 643 TurnLmp_RL_Flt 1;
BA_ "FlexKomComment" SG_ 643 TurnLmp_RL_Flt "Turn indication lamp rear fault";
BA_ "GenSigTimeout_IC" SG_ 643 TurnLmp_RR_Flt 10500;
BA_ "GenSigSNA" SG_ 643 TurnLmp_RR_Flt "0h";
BA_ "GenSigSendType" SG_ 643 TurnLmp_RR_Flt 5;
BA_ "GenSigCycleTime" SG_ 643 TurnLmp_RR_Flt 1000;
BA_ "FlexKomSigStartValue" SG_ 643 TurnLmp_RR_Flt "00h";
BA_ "FlexKomSigStartPos" SG_ 643 TurnLmp_RR_Flt 25;
BA_ "FlexKomSigName" SG_ 643 TurnLmp_RR_Flt "TurnLmp_R_Flt";
BA_ "FlexKomSigLaenge" SG_ 643 TurnLmp_RR_Flt 2;
BA_ "FlexKomSID" SG_ 643 TurnLmp_RR_Flt 1033;
BA_ "FlexKomIsMotorola" SG_ 643 TurnLmp_RR_Flt 1;
BA_ "FlexKomComment" SG_ 643 TurnLmp_RR_Flt "Turn indication lamp rear fault";
BA_ "GenSigSNA" SG_ 643 WPR_SYS_AUTO "0h";
BA_ "GenSigCycleTime" SG_ 643 WPR_SYS_AUTO 1000;
BA_ "FlexKomSigStartValue" SG_ 643 WPR_SYS_AUTO "01h";
BA_ "FlexKomSigStartPos" SG_ 643 WPR_SYS_AUTO 47;
BA_ "FlexKomSigName" SG_ 643 WPR_SYS_AUTO "WPR_SYS_STAT";
BA_ "FlexKomSigLaenge" SG_ 643 WPR_SYS_AUTO 8;
BA_ "FlexKomSID" SG_ 643 WPR_SYS_AUTO 1048;
BA_ "FlexKomIsMotorola" SG_ 643 WPR_SYS_AUTO 1;
BA_ "FlexKomComment" SG_ 643 WPR_SYS_AUTO "Wiper System Status";
BA_ "GenSigSNA" SG_ 643 WPR_SYS_FLT "0h";
BA_ "GenSigCycleTime" SG_ 643 WPR_SYS_FLT 1000;
BA_ "FlexKomSigStartValue" SG_ 643 WPR_SYS_FLT "01h";
BA_ "FlexKomSigStartPos" SG_ 643 WPR_SYS_FLT 47;
BA_ "FlexKomSigName" SG_ 643 WPR_SYS_FLT "WPR_SYS_STAT";
BA_ "FlexKomSigLaenge" SG_ 643 WPR_SYS_FLT 8;
BA_ "FlexKomSID" SG_ 643 WPR_SYS_FLT 1048;
BA_ "FlexKomIsMotorola" SG_ 643 WPR_SYS_FLT 1;
BA_ "FlexKomComment" SG_ 643 WPR_SYS_FLT "Wiper System Status";
BA_ "GenSigSNA" SG_ 643 WPR_SYS_HIGH "0h";
BA_ "GenSigCycleTime" SG_ 643 WPR_SYS_HIGH 1000;
BA_ "FlexKomSigStartValue" SG_ 643 WPR_SYS_HIGH "01h";
BA_ "FlexKomSigStartPos" SG_ 643 WPR_SYS_HIGH 47;
BA_ "FlexKomSigName" SG_ 643 WPR_SYS_HIGH "WPR_SYS_STAT";
BA_ "FlexKomSigLaenge" SG_ 643 WPR_SYS_HIGH 8;
BA_ "FlexKomSID" SG_ 643 WPR_SYS_HIGH 1048;
BA_ "FlexKomIsMotorola" SG_ 643 WPR_SYS_HIGH 1;
BA_ "FlexKomComment" SG_ 643 WPR_SYS_HIGH "Wiper System Status";
BA_ "GenSigSNA" SG_ 643 WPR_SYS_INT "0h";
BA_ "GenSigCycleTime" SG_ 643 WPR_SYS_INT 1000;
BA_ "FlexKomSigStartValue" SG_ 643 WPR_SYS_INT "01h";
BA_ "FlexKomSigStartPos" SG_ 643 WPR_SYS_INT 47;
BA_ "FlexKomSigName" SG_ 643 WPR_SYS_INT "WPR_SYS_STAT";
BA_ "FlexKomSigLaenge" SG_ 643 WPR_SYS_INT 8;
BA_ "FlexKomSID" SG_ 643 WPR_SYS_INT 1048;
BA_ "FlexKomIsMotorola" SG_ 643 WPR_SYS_INT 1;
BA_ "FlexKomComment" SG_ 643 WPR_SYS_INT "Wiper System Status";
BA_ "GenSigSNA" SG_ 643 WPR_SYS_LOW "0h";
BA_ "GenSigCycleTime" SG_ 643 WPR_SYS_LOW 1000;
BA_ "FlexKomSigStartValue" SG_ 643 WPR_SYS_LOW "01h";
BA_ "FlexKomSigStartPos" SG_ 643 WPR_SYS_LOW 47;
BA_ "FlexKomSigName" SG_ 643 WPR_SYS_LOW "WPR_SYS_STAT";
BA_ "FlexKomSigLaenge" SG_ 643 WPR_SYS_LOW 8;
BA_ "FlexKomSID" SG_ 643 WPR_SYS_LOW 1048;
BA_ "FlexKomIsMotorola" SG_ 643 WPR_SYS_LOW 1;
BA_ "FlexKomComment" SG_ 643 WPR_SYS_LOW "Wiper System Status";
BA_ "GenSigSNA" SG_ 643 WPR_SYS_MIST "0h";
BA_ "GenSigCycleTime" SG_ 643 WPR_SYS_MIST 1000;
BA_ "FlexKomSigStartValue" SG_ 643 WPR_SYS_MIST "01h";
BA_ "FlexKomSigStartPos" SG_ 643 WPR_SYS_MIST 47;
BA_ "FlexKomSigName" SG_ 643 WPR_SYS_MIST "WPR_SYS_STAT";
BA_ "FlexKomSigLaenge" SG_ 643 WPR_SYS_MIST 8;
BA_ "FlexKomSID" SG_ 643 WPR_SYS_MIST 1048;
BA_ "FlexKomIsMotorola" SG_ 643 WPR_SYS_MIST 1;
BA_ "FlexKomComment" SG_ 643 WPR_SYS_MIST "Wiper System Status";
BA_ "GenSigStartValue" SG_ 643 WPR_SYS_OFF 1;
BA_ "GenSigSNA" SG_ 643 WPR_SYS_OFF "1h";
BA_ "GenSigCycleTime" SG_ 643 WPR_SYS_OFF 1000;
BA_ "FlexKomSigStartValue" SG_ 643 WPR_SYS_OFF "01h";
BA_ "FlexKomSigStartPos" SG_ 643 WPR_SYS_OFF 47;
BA_ "FlexKomSigName" SG_ 643 WPR_SYS_OFF "WPR_SYS_STAT";
BA_ "FlexKomSigLaenge" SG_ 643 WPR_SYS_OFF 8;
BA_ "FlexKomSID" SG_ 643 WPR_SYS_OFF 1048;
BA_ "FlexKomIsMotorola" SG_ 643 WPR_SYS_OFF 1;
BA_ "FlexKomComment" SG_ 643 WPR_SYS_OFF "Wiper System Status";
BA_ "GenSigSNA" SG_ 643 WPR_SYS_WASH "0h";
BA_ "GenSigCycleTime" SG_ 643 WPR_SYS_WASH 1000;
BA_ "FlexKomSigStartValue" SG_ 643 WPR_SYS_WASH "01h";
BA_ "FlexKomSigStartPos" SG_ 643 WPR_SYS_WASH 47;
BA_ "FlexKomSigName" SG_ 643 WPR_SYS_WASH "WPR_SYS_STAT";
BA_ "FlexKomSigLaenge" SG_ 643 WPR_SYS_WASH 8;
BA_ "FlexKomSID" SG_ 643 WPR_SYS_WASH 1048;
BA_ "FlexKomIsMotorola" SG_ 643 WPR_SYS_WASH 1;
BA_ "FlexKomComment" SG_ 643 WPR_SYS_WASH "Wiper System Status";
VAL_ 969 AMB_TEMP_AVG_C 255 "SNA" ;
VAL_ 969 AMB_TEMP_AVG_F 255 "SNA" ;
VAL_ 881 SwayBarEVICDisplay 0 "TM0" 1 "TM1" 2 "TM2" 3 "TM3" 4 "TM4" 5 "TM5" 6 "TM6" 7 "TM7" 8 "TM8" 9 "TM9" 10 "TM10" 11 "TM11" 12 "TM12" 13 "TM13" 14 "TM14" 15 "SNA" ;
VAL_ 881 SwayBar_LEDRq 0 "OFF" 1 "CONT" 2 "BLINK" 3 "SNA" ;
VAL_ 881 SwayBar_Sts 0 "UNLOCKED" 1 "LOCKED" 2 "S_I_P" 3 "SNA" ;
VAL_ 838 AS_CHIME_TYPE 0 "NONE" 1 "TYP_1" 2 "TYP_2" 3 "TYP_3" 4 "TYP_4" 5 "TYP_5" 6 "TYP_6" 7 "TYP_7" 8 "TYP_8" 9 "TYP_9" 10 "TYP_10" 11 "TYP_11" 12 "TYP_12" 13 "TYP_13" 14 "TYP_14" 15 "SNA" ;
VAL_ 523 ESLLockUnlockReq 0 "Not_Request" 1 "Unlock" 2 "Lock" ;
VAL_ 720 BSM_CFG_STAT 0 "NT_ENB" 1 "ENB_LED" 2 "ENB_LED_CHM" 3 "SNA" ;
VAL_ 720 BSM_LT_WRN 0 "NW" 2 "RM_LED" 3 "RBM_LED" 4 "FM_LED" 5 "FBM_LED" 7 "SNA" ;
VAL_ 720 BSM_RT_WRN 0 "NW" 2 "RM_LED" 3 "RBM_LED" 4 "FM_LED" 5 "FBM_LED" 7 "SNA" ;
VAL_ 998 BU_NET_CFG_STAT_INT 0 "NA" 1 "PROGAMMED" 2 "NA1" 3 "SNA" ;
VAL_ 998 BU_NetCfg_ANC_I 0 "Not_Present" 1 "Present" ;
VAL_ 999 BU_NET_CFG_STAT_PT 0 "NA" 1 "PROGAMMED" 2 "NA1" 3 "SNA" ;
VAL_ 999 BU_NetCfg_ASBS 0 "Not_Present" 1 "Present" ;
VAL_ 999 BU_NetCfg_BSMO 0 "Not_Present" 1 "Present" ;
VAL_ 999 BU_NetCfg_DPDM 0 "Not_Present" 1 "Present" ;
VAL_ 999 BU_NetCfg_GPF 0 "Not_Present" 1 "Present" ;
VAL_ 999 BU_NetCfg_SGW 0 "Not_Present" 1 "Present" ;
VAL_ 927 BU_NET_CFG_STAT_ePT 0 "NA" 1 "PROGAMMED" 2 "NA1" 3 "SNA" ;
VAL_ 927 BU_NetCfg_BSMO_ePT 0 "Not_Present" 1 "Present" ;
VAL_ 937 HL_DLY_TIME 255 "SNA" ;
VAL_ 937 ILL_APRCH_TIME 255 "SNA" ;
VAL_ 937 SOUND_LK_1ST_2ND 0 "OFF" 1 "FIRST" 2 "SECOND" 3 "SNA" ;
VAL_ 685 Cfg_Aux_PTO 0 "NONE" 3 "FOUR_CUTOFF" 4 "FOUR" 5 "FIVE" 6 "SIX" 7 "SNA" ;
VAL_ 657 DR_LK_STAT 0 "LKD" 1 "DRV_DR_UNLKD" 2 "ALL_DR_UNLKD" 3 "SNA" ;
VAL_ 657 FOB_SrchRq 0 "NO_ACT" 1 "SEARCH" 2 "RCVD_RSLT" ;
VAL_ 657 IGN_OFF_TIME_LNG 4095 "SNA" ;
VAL_ 657 PANEL_INTS 255 "SNA" ;
VAL_ 657 PTC_REL1_STAT 0 "OFF" 1 "ON" 2 "FLT" 3 "SNA" ;
VAL_ 657 PTC_REL2_STAT 0 "OFF" 1 "ON" 2 "FLT" 3 "SNA" ;
VAL_ 657 PTC_REL3_STAT 0 "OFF" 1 "ON" 2 "FLT" 3 "SNA" ;
VAL_ 657 SHIP_STAT 0 "CUST_MD" 1 "ABBRV_MD" 2 "SHIP_MD" 3 "NOT_PROG" ;
VAL_ 613 DriverDoorOnOffSts 0 "DOOR_ON" 1 "DOOR_OFF" 2 "FLT" 3 "SNA" ;
VAL_ 613 DrvMd_PopUpRqst 0 "TM0" 1 "TM1" 2 "TM2" 3 "TM3" 4 "TM4" 5 "TM5" 6 "TM6" 7 "TM7" 8 "TM8" 9 "TM9" 10 "TM10" 11 "TM11" 12 "TM12" 13 "TM13" 14 "TM14" 15 "TM15" 16 "TM16" 17 "TM17" 18 "TM18" 19 "TM19" 20 "TM20" 21 "TM21" 22 "TM22" 255 "SNA" ;
VAL_ 613 Exhaust_RQ_ICS 0 "NOT_PSD" 1 "PSD" 2 "Not_Defined" 3 "SNA" ;
VAL_ 613 LHRDoorOnOffSts 0 "DOOR_ON" 1 "DOOR_OFF" 2 "FLT" 3 "SNA" ;
VAL_ 613 PsngrDoorOnOffSts 0 "DOOR_ON" 1 "DOOR_OFF" 2 "FLT" 3 "SNA" ;
VAL_ 613 RHRDoorOnOffSts 0 "DOOR_ON" 1 "DOOR_OFF" 2 "FLT" 3 "SNA" ;
VAL_ 119 CmdIgnStat 0 "IGN_LK" 3 "IGN_OFF_ACC" 4 "IGN_RUN" 5 "IGN_START" 7 "SNA" ;
VAL_ 119 KeyInIgn 0 "KEY_DEF" 1 "KEY_NOT_IN_IGN" 2 "KEY_IN_IGN" 3 "SNA" ;
VAL_ 119 StTyp 0 "ST_NOT_ACT" 1 "NOR_ST" 2 "TIP_ST" 3 "REM_ST" 7 "SNA" ;
VAL_ 299 AMB_TEMP_AVG 65535 "SNA" ;
VAL_ 299 AMB_TEMP_VOLT 255 "SNA" ;
VAL_ 299 AirTemp_Outsd 255 "SNA" ;
VAL_ 299 BATT_VOLT 255 "SNA" ;
VAL_ 299 FUEL_VOLT 255 "SNA" ;
VAL_ 643 RemSt_Inhibit 0 "INHIBIT_DEFAUILT" 1 "TIME_OUT_RUN" 2 "TIME_OUT_CUST_MODE" 3 "KEY_IN_RUN" 4 "DRV_DOOR_AJAR" 5 "PASS_DOOR_AJAR" 6 "LR_DOOR_AJAR" 7 "RR_DOOR_AJAR" 8 "START_COUNTER" 9 "FAIL_COUNTER" 10 "LOW_RPM_SHUTDOWN" 11 "KEY_IN_IGN" 12 "BRAKE_PRESSED" 13 "HAZARD_LAMP_ON" 14 "NOT_IN_PARK" 15 "VEH_SPEED_HIGH" 16 "HOOD_AJAR" 17 "TRUNK_LIFTGATE" 18 "VTA_ALARM" 19 "PANIC_MODE" 20 "BATT_VOLT_HIGH" 21 "BATT_VOLT_LOW" 22 "POWER_LOSS" 23 "MIL_ON" 24 "OIL_PRESSURE_LOW" 25 "COOLANT_TEMP_HIGH" 26 "RPM_HIGH" 27 "CRANK_NO_START" 28 "REMOTE_OFF_RQ" 29 "RS_DISABLED_PREV" 30 "NOT_CONFIGURED" 31 "NO_HOOD_SWITCH" 32 "NO_AUTO_TRANS" 33 "NOT_ENABLED" 34 "INVALID_SKIM_KEY" 35 "IGN_SNA" 36 "IGN_NOT_LOCK" 37 "GLOW_PLUG_TIMEOUT" 38 "LOW_FUEL" 39 "ETC_LAMP_ON" 40 "LOGISTIC_MODE" 41 "COLD_START_LAMP" 42 "ESL_NOT_UNLOCK" 43 "RFHUB_HS_FAIL" 44 "PSA_Not_Active" 45 "ABORT_CRANKING_ENABLE" 255 "SNA" ;
VAL_ 643 WPR_SYS_AUTO 0 "SNA" ;
VAL_ 643 WPR_SYS_FLT 0 "SNA" ;
VAL_ 643 WPR_SYS_HIGH 0 "SNA" ;
VAL_ 643 WPR_SYS_INT 0 "SNA" ;
VAL_ 643 WPR_SYS_LOW 0 "SNA" ;
VAL_ 643 WPR_SYS_MIST 0 "SNA" ;
VAL_ 643 WPR_SYS_OFF 1 "SNA" ;
VAL_ 643 WPR_SYS_WASH 0 "SNA" ;
